AUTOSAR XML (schema 00049)
# Copyright (c) 2024 Mercedes-Benz AG
standard types defined: boolean, uint16, uint32, uint8
package /Units
  13 x unit:
    percent: display-name=%  # %
    A: display-name=A
    km: display-name=km
    km_per_h: display-name=km/h  # km/h
    m_per_s_sq: display-name=m/s²  # m/s²
    NoUnit: display-name=NoUnit
    ns: display-name=ns
    s: display-name=s
    V: display-name=V
    deg: display-name=°  # °
    deg_per_s: display-name=°/s  # °/s
    deg_per_s_sq: display-name=°/s²  # °/s²
    deg_C: display-name=°C  # °C
package /ImplementationDataTypes
  41 x impl type, all with category=TYPE_REFERENCE:
    c02_Ndef_False_True_ST3: data-constr=c02_Ndef_False_True_ST3, implementation-data-type=uint8, invalid-value=3  # 02_Ndef_False_True_ST3
    c02_TransMd_Stat: data-constr=c02_TransMd_Stat, implementation-data-type=uint8, invalid-value=3  # 02_TransMd_Stat
    c3_HAD_Ext_Stat_ST3: data-constr=c3_HAD_Ext_Stat_ST3, implementation-data-type=uint8, invalid-value=7  # 03_HAD_Ext_State_ST3
    c03_IMU_Force_Ang_Stat_ST3: data-constr=c03_IMU_Force_Ang_Stat_ST3, implementation-data-type=uint8  # 03_IMU_Force_Ang_Stat_ST3
    c03_IMU_Stat_ST3: data-constr=c03_IMU_Stat_ST3, implementation-data-type=uint8  # 03_IMU_Stat_ST3
    c03_ISw_Stat: data-constr=c03_ISw_Stat, implementation-data-type=uint8, invalid-value=7  # 03_ISw_Stat
    c03_PN14_ProdMd_Stat_ST3: data-constr=c03_PN14_ProdMd_Stat_ST3, implementation-data-type=uint8, invalid-value=7  # 03_PN14_ProdMd_Stat_ST3
    c03_PN14_TDP_Sw_Stat: data-constr=c03_PN14_TDP_Sw_Stat, implementation-data-type=uint8, invalid-value=7  # 03_PN14_TDP_Sw_Stat
    c04_VehOpMode: data-constr=c04_VehOpMode, implementation-data-type=uint8, invalid-value=15  # 04_VehOpMode
    c07_per_0to100_1_SNA: data-constr=c07_per_0to100_1_SNA, implementation-data-type=uint8, invalid-value=127  # 07_%_0-100_1_SNA
    c07_0_111_1_SNA: data-constr=c07_0_111_1_SNA, implementation-data-type=uint8, invalid-value=127  # 07_0-111_SNA
    c08_0_254_1_SNA_255: data-constr=c08_0_254_1_SNA_255, implementation-data-type=uint8, invalid-value=255  # 08_0-254_1_SNA=255
    c08_0_255_1_SNA_na: data-constr=c08_0_255_1_SNA_na, implementation-data-type=uint8  # 08_0-255_1_SNA=-
    c08_TmSync_Stat: implementation-data-type=uint8  # 08_TmSync_Stat
    c08_UInt_SNA_na: data-constr=c08_UInt_SNA_na, implementation-data-type=uint8  # 08_UInt_SNA=-
    c08_deg_m50_160_1: data-constr=c08_deg_m50_160_1, implementation-data-type=uint8, invalid-value=255  # 08_°_-50-+160_1
    c08_degC_m40_85_0k5: data-constr=c08_degC_m40_85_0k5, implementation-data-type=uint8, invalid-value=255  # 08_°C_-40-+85_0,5
    c10_V_0_25k55_0k025: data-constr=c10_V_0_25k55_0k025, implementation-data-type=uint16, invalid-value=1023  # 10_V_0-25,55_0,025
    c10_WakeupRsn_ST3: data-constr=c10_WakeupRsn_ST3, implementation-data-type=uint16, invalid-value=1023  # 10_WakeupRsn_ST3
    c12_0_4094_1_SNA: data-constr=c12_0_4094_1_SNA, implementation-data-type=uint16, invalid-value=4095  # 12_0-4094_1_SNA
    c12_km_p_h_0_409k4_0k1: data-constr=c12_km_p_h_0_409k4_0k1, implementation-data-type=uint16, invalid-value=4095  # 12_km/h_0-409,4_0,1
    c13_A_m409k6_409k4_0k1: data-constr=c13_A_m409k6_409k4_0k1, implementation-data-type=uint16, invalid-value=8191  # 13_A_-409,6-409,4_0,1
    c16_CRC_woSNA: data-constr=c16_CRC_woSNA, implementation-data-type=uint16  # 16_CRC_w/oSNA
    c16_m_pro_s_sq_m50_50_0d002: data-constr=c16_m_pro_s_sq_m50_50_0d002, implementation-data-type=uint16, invalid-value=65535  # 16_m/s²_-50_+50_0.002
    c16_deg_per_sec_m300_300_0d01: data-constr=c16_deg_per_sec_m300_300_0d01, implementation-data-type=uint16, invalid-value=65535  # 16_°/s_-300-+300_0,01
    c16_deg_per_s_sq_m1200_1200_0d04: data-constr=c16_deg_per_s_sq_m1200_1200_0d04, implementation-data-type=uint16, invalid-value=65535  # 16_°/s²_-1200-+1200_0,04
    c24_km_0_999999k9_0k1_Invld_SNA: data-constr=c24_km_0_999999k9_0k1_Invld_SNA, implementation-data-type=uint32, invalid-value=16777215  # 24_km_0-999999,9_0,1_Invld_SNA
    c32_ns_0_4294967295_1_noSNA: data-constr=c32_ns_0_4294967295_1_noSNA, implementation-data-type=uint32  # 32_ns_0-4294967295_1_noSNA
    c32_s_0_4294967295_1_noSNA: data-constr=c32_s_0_4294967295_1_noSNA, implementation-data-type=uint32  # 32_s_0-4294967295_1_noSNA
    DC_BOOL: implementation-data-type=boolean
    NM_ActvWakeup: implementation-data-type=boolean
    NM_Coord_Id: range raw 0..3, implementation-data-type=uint8
    NM_Coord_SleepRdy: implementation-data-type=boolean
    NM_PartNw_Info: implementation-data-type=boolean
    NM_RepeatMsg_Rq: implementation-data-type=boolean
    Rsrv03: range raw 0..7, implementation-data-type=uint8, invalid-value=7
    Rsrv05: range raw 0..31, implementation-data-type=uint8, invalid-value=31
    Rsrv08: range raw 0..255, implementation-data-type=uint8, invalid-value=255
    Rsrv09: range raw 0..511, implementation-data-type=uint16, invalid-value=511
    Rsrv16: range raw 0..65535, implementation-data-type=uint16, invalid-value=65535
    Rsrv32: range raw 0..4294967295, implementation-data-type=uint32, invalid-value=4294967295
package /DataConstraints
  range c02_Ndef_False_True_ST3: raw 1..3  # 02_Ndef_False_True_ST3
  range c02_TransMd_Stat: raw 0..3  # 02_TransMd_Stat
  range c3_HAD_Ext_Stat_ST3: raw 0..7  # 03_HAD_Ext_State_ST3
  range c03_IMU_Force_Ang_Stat_ST3: raw 0..6  # 03_IMU_Force_Ang_Stat_ST3
  range c03_IMU_Stat_ST3: raw 0..4  # 03_IMU_Stat_ST3
  range c03_ISw_Stat: raw 0..7  # 03_ISw_Stat
  range c03_PN14_ProdMd_Stat_ST3: raw 0..7  # 03_PN14_ProdMd_Stat_ST3
  range c03_PN14_TDP_Sw_Stat: raw 0..7  # 03_PN14_TDP_Sw_Stat
  range c04_VehOpMode: raw 0..15  # 04_VehOpMode
  range c07_per_0to100_1_SNA: phys 0..127, raw 0..127  # 07_%_0-100_1_SNA
  range c07_0_111_1_SNA: phys 0..127, raw 0..127  # 07_0-111_SNA
  range c08_0_254_1_SNA_255: phys 0..255, raw 0..255  # 08_0-254_1_SNA=255
  range c08_0_255_1_SNA_na: phys 0..255, raw 0..255  # 08_0-255_1_SNA=-
  range c08_UInt_SNA_na: raw 0..255  # 08_UInt_SNA=-
  range c08_deg_m50_160_1: phys -50..205, raw 0..255  # 08_°_-50-+160_1
  range c08_degC_m40_85_0k5: phys -40..87.5, raw 0..255  # 08_°C_-40-+85_0,5
  range c10_V_0_25k55_0k025: phys 0..25.575, raw 0..1023  # 10_V_0-25,55_0,025
  range c10_WakeupRsn_ST3: raw 0..1023  # 10_WakeupRsn_ST3
  range c12_0_4094_1_SNA: phys 0..4095, raw 0..4095  # 12_0-4094_1_SNA
  range c12_km_p_h_0_409k4_0k1: phys 0..409.5, raw 0..4095  # 12_km/h_0-409,4_0,1
  range c13_A_m409k6_409k4_0k1: phys -409.6..409.5, raw 0..8191  # 13_A_-409,6-409,4_0,1
  range c16_CRC_woSNA: raw 0..65535  # 16_CRC_w/oSNA
  range c16_m_pro_s_sq_m50_50_0d002: phys -50..81.07, raw 0..65535  # 16_m/s²_-50_+50_0.002
  range c16_deg_per_sec_m300_300_0d01: phys -300..355.35, raw 0..65535  # 16_°/s_-300-+300_0,01
  range c16_deg_per_s_sq_m1200_1200_0d04: phys -1200..1421.4, raw 0..65535  # 16_°/s²_-1200-+1200_0,04
  range c24_km_0_999999k9_0k1_Invld_SNA: phys 0..1677721.5, raw 0..16777215  # 24_km_0-999999,9_0,1_Invld_SNA
  range c32_ns_0_4294967295_1_noSNA: phys 0..4294967295, raw 0..4294967295  # 32_ns_0-4294967295_1_noSNA
  range c32_s_0_4294967295_1_noSNA: phys 0..4294967295, raw 0..4294967295  # 32_s_0-4294967295_1_noSNA
package /ApplicationDataTypes
  41 x app type:
    c02_Ndef_False_True_ST3: category=VALUE, compu-method=c02_Ndef_False_True_ST3, data-constr=c02_Ndef_False_True_ST3, invalid-value=I_C02_NDEF_FALSE_TRUE_ST3_SNA  # 02_Ndef_False_True_ST3
    c02_TransMd_Stat: category=VALUE, compu-method=c02_TransMd_Stat, data-constr=c02_TransMd_Stat, invalid-value=I_C02_TRANSMD_STAT_SNA  # 02_TransMd_Stat
    c3_HAD_Ext_Stat_ST3: category=VALUE, compu-method=c3_HAD_Ext_Stat_ST3, data-constr=c3_HAD_Ext_Stat_ST3, invalid-value=I_C3_HAD_EXT_STAT_ST3_SNA  # 03_HAD_Ext_State_ST3
    c03_IMU_Force_Ang_Stat_ST3: category=VALUE, compu-method=c03_IMU_Force_Ang_Stat_ST3, data-constr=c03_IMU_Force_Ang_Stat_ST3  # 03_IMU_Force_Ang_Stat_ST3
    c03_IMU_Stat_ST3: category=VALUE, compu-method=c03_IMU_Stat_ST3, data-constr=c03_IMU_Stat_ST3  # 03_IMU_Stat_ST3
    c03_ISw_Stat: category=VALUE, compu-method=c03_ISw_Stat, data-constr=c03_ISw_Stat, invalid-value=I_C03_ISW_STAT_SNA  # 03_ISw_Stat
    c03_PN14_ProdMd_Stat_ST3: category=VALUE, compu-method=c03_PN14_ProdMd_Stat_ST3, data-constr=c03_PN14_ProdMd_Stat_ST3, invalid-value=I_C03_PN14_PRODMD_STAT_ST3_SNA  # 03_PN14_ProdMd_Stat_ST3
    c03_PN14_TDP_Sw_Stat: category=VALUE, compu-method=c03_PN14_TDP_Sw_Stat, data-constr=c03_PN14_TDP_Sw_Stat, invalid-value=I_C03_PN14_TDP_SW_STAT_SNA  # 03_PN14_TDP_Sw_Stat
    c04_VehOpMode: category=VALUE, compu-method=c04_VehOpMode, data-constr=c04_VehOpMode, invalid-value=I_C04_VEHOPMODE_SNA  # 04_VehOpMode
    c07_per_0to100_1_SNA: category=VALUE, compu-method=c07_per_0to100_1_SNA, data-constr=c07_per_0to100_1_SNA, invalid-value=I_C07_PER_0TO100_1_SNA_SNA %, unit=%  # 07_%_0-100_1_SNA
    c07_0_111_1_SNA: category=VALUE, compu-method=c07_0_111_1_SNA, data-constr=c07_0_111_1_SNA, invalid-value=I_C07_0_111_1_SNA_SNA, unit=NoUnit  # 07_0-111_SNA
    c08_0_254_1_SNA_255: category=VALUE, compu-method=c08_0_254_1_SNA_255, data-constr=c08_0_254_1_SNA_255, invalid-value=I_C08_0_254_1_SNA_255_SNA, unit=NoUnit  # 08_0-254_1_SNA=255
    c08_0_255_1_SNA_na: category=VALUE, compu {identical}, data-constr=c08_0_255_1_SNA_na, unit=NoUnit  # 08_0-255_1_SNA=-
    c08_TmSync_Stat: category=VALUE, compu-method=c08_TmSync_Stat  # 08_TmSync_Stat
    c08_UInt_SNA_na: category=VALUE, data-constr=c08_UInt_SNA_na  # 08_UInt_SNA=-
    c08_deg_m50_160_1: category=VALUE, compu-method=c08_deg_m50_160_1, data-constr=c08_deg_m50_160_1, invalid-value=I_C08_DEG_M50_160_1_SNA °, unit=°  # 08_°_-50-+160_1
    c08_degC_m40_85_0k5: category=VALUE, compu-method=c08_degC_m40_85_0k5, data-constr=c08_degC_m40_85_0k5, invalid-value=I_C08_DEGC_M40_85_0K5_SNA °C, unit=°C  # 08_°C_-40-+85_0,5
    c10_V_0_25k55_0k025: category=VALUE, compu-method=c10_V_0_25k55_0k025, data-constr=c10_V_0_25k55_0k025, invalid-value=I_C10_V_0_25K55_0K025_SNA V, unit=V  # 10_V_0-25,55_0,025
    c10_WakeupRsn_ST3: category=VALUE, compu-method=c10_WakeupRsn_ST3, data-constr=c10_WakeupRsn_ST3, invalid-value=I_C10_WAKEUPRSN_ST3_SNA  # 10_WakeupRsn_ST3
    c12_0_4094_1_SNA: category=VALUE, compu-method=c12_0_4094_1_SNA, data-constr=c12_0_4094_1_SNA, invalid-value=I_C12_0_4094_1_SNA_SNA, unit=NoUnit  # 12_0-4094_1_SNA
    c12_km_p_h_0_409k4_0k1: category=VALUE, compu-method=c12_km_p_h_0_409k4_0k1, data-constr=c12_km_p_h_0_409k4_0k1, invalid-value=I_C12_KM_P_H_0_409K4_0K1_SNA km/h, unit=km/h  # 12_km/h_0-409,4_0,1
    c13_A_m409k6_409k4_0k1: category=VALUE, compu-method=c13_A_m409k6_409k4_0k1, data-constr=c13_A_m409k6_409k4_0k1, invalid-value=I_C13_A_M409K6_409K4_0K1_SNA A, unit=A  # 13_A_-409,6-409,4_0,1
    c16_CRC_woSNA: category=VALUE, data-constr=c16_CRC_woSNA  # 16_CRC_w/oSNA
    c16_m_pro_s_sq_m50_50_0d002: category=VALUE, compu-method=c16_m_pro_s_sq_m50_50_0d002, data-constr=c16_m_pro_s_sq_m50_50_0d002, invalid-value=I_C16_M_PRO_S_SQ_M50_50_0D002_SNA m/s², unit=m/s²  # 16_m/s²_-50_+50_0.002
    c16_deg_per_sec_m300_300_0d01: category=VALUE, compu-method=c16_deg_per_sec_m300_300_0d01, data-constr=c16_deg_per_sec_m300_300_0d01, invalid-value=I_C16_DEG_PER_SEC_M300_300_0D01_SNA °/s, unit=°/s  # 16_°/s_-300-+300_0,01
    c16_deg_per_s_sq_m1200_1200_0d04: category=VALUE, compu-method=c16_deg_per_s_sq_m1200_1200_0d04, data-constr=c16_deg_per_s_sq_m1200_1200_0d04, invalid-value=I_C16_DEG_PER_S_SQ_M1200_1200_0D04_SNA °/s², unit=°/s²  # 16_°/s²_-1200-+1200_0,04
    c24_km_0_999999k9_0k1_Invld_SNA: category=VALUE, compu-method=c24_km_0_999999k9_0k1_Invld_SNA, data-constr=c24_km_0_999999k9_0k1_Invld_SNA, invalid-value=I_C24_KM_0_999999K9_0K1_INVLD_SNA_SNA km, unit=km  # 24_km_0-999999,9_0,1_Invld_SNA
    c32_ns_0_4294967295_1_noSNA: category=VALUE, compu {identical; unit ns}, data-constr=c32_ns_0_4294967295_1_noSNA, unit=ns  # 32_ns_0-4294967295_1_noSNA
    c32_s_0_4294967295_1_noSNA: category=VALUE, compu {identical; unit s}, data-constr=c32_s_0_4294967295_1_noSNA, unit=s  # 32_s_0-4294967295_1_noSNA
    DC_BOOL: category=BOOLEAN, compu {0=FALSE, 1=TRUE}
    NM_ActvWakeup: category=BOOLEAN, compu {0=FALSE, 1=TRUE}
    NM_Coord_Id: category=VALUE, range raw 0..3
    NM_Coord_SleepRdy: category=BOOLEAN, compu {0=FALSE, 1=TRUE}
    NM_PartNw_Info: category=BOOLEAN, compu {0=FALSE, 1=TRUE}
    NM_RepeatMsg_Rq: category=BOOLEAN, compu {0=FALSE, 1=TRUE}
    Rsrv03: category=VALUE, range raw 0..7, invalid-value=7
    Rsrv05: category=VALUE, range raw 0..31, invalid-value=31
    Rsrv08: category=VALUE, range raw 0..255, invalid-value=255
    Rsrv09: category=VALUE, range raw 0..511, invalid-value=511
    Rsrv16: category=VALUE, range raw 0..65535, invalid-value=65535
    Rsrv32: category=VALUE, range raw 0..4294967295, invalid-value=4294967295
package /CompuMethods
  compu method c02_Ndef_False_True_ST3: 1=I_C02_NDEF_FALSE_TRUE_ST3_FALSE (FALSE) (False), 2=I_C02_NDEF_FALSE_TRUE_ST3_TRUE (TRUE) (True), 3=I_C02_NDEF_FALSE_TRUE_ST3_SNA (SNA) (SNA value from data type)  # OLDNAME: st3_02_NDEF_FALSE_TRUE_SNA / DO NOT USE for future implementation of STAR3 and following architectures. Use 02_False_True instead.
  compu method c02_TransMd_Stat: 0=I_C02_TRANSMD_STAT_OFF (OFF) (Transport mode permanently off), 1=I_C02_TRANSMD_STAT_TEMP_OFF (TEMP_OFF) (Transport mode temporarily off), 2=I_C02_TRANSMD_STAT_ACTV (ACTV) (Transport mode active), 3=I_C02_TRANSMD_STAT_SNA (SNA) (SNA value from data type)
  compu method c3_HAD_Ext_Stat_ST3: 0=I_C3_HAD_EXT_STAT_ST3_HAD_OFF (HAD_OFF), 1=I_C3_HAD_EXT_STAT_ST3_HAD_IN_PREPARATION (HAD_IN_PREPARATION), 2=I_C3_HAD_EXT_STAT_ST3_HAD_FADE_IN (HAD_FADE_IN) (HAD FADE IN), 3=I_C3_HAD_EXT_STAT_ST3_HAD_ON (HAD_ON), 4=I_C3_HAD_EXT_STAT_ST3_HAD_FADE_OUT (HAD_FADE_OUT) (HAD FADE OUT), 7=I_C3_HAD_EXT_STAT_ST3_SNA (SNA) (SNA value from data type)  # st3_03_HAD_State / 03_HAD_Ext_State_ST3
  compu method c03_IMU_Force_Ang_Stat_ST3: 0=I_C03_IMU_FORCE_ANG_STAT_ST3_UNKNOWN (UNKNOWN) (Unknown), 1=I_C03_IMU_FORCE_ANG_STAT_ST3_INIT (INIT) (Initialization phase), 2=I_C03_IMU_FORCE_ANG_STAT_ST3_VALID (VALID) (Angular rates valid, within specification), 3=I_C03_IMU_FORCE_ANG_STAT_ST3_ERROR_SPORADIC (ERROR_SPORADIC) (Sporadic error of angular rates), 4=I_C03_IMU_FORCE_ANG_STAT_ST3_ERROR_PERMANENT (ERROR_PERMANENT) (Permanent error of angular rates), 5=I_C03_IMU_FORCE_ANG_STAT_ST3_ERROR_OVERLOAD (ERROR_OVERLOAD) (Overload of angular rates), 6=I_C03_IMU_FORCE_ANG_STAT_ST3_ERROR_TEMPERATURE (ERROR_TEMPERATURE) (Temperature outside of range or temperature gradient to high)
  compu method c03_IMU_Stat_ST3: 0=I_C03_IMU_STAT_ST3_UNKNOWN (UNKNOWN) (Unknown), 1=I_C03_IMU_STAT_ST3_INIT (INIT) (Initialization phase), 2=I_C03_IMU_STAT_ST3_OPERATIONAL (OPERATIONAL) (IMU operational, no overall error), 3=I_C03_IMU_STAT_ST3_ERROR_SPORADIC (ERROR_SPORADIC) (Overall sporadic error), 4=I_C03_IMU_STAT_ST3_ERROR_PERMANENT (ERROR_PERMANENT) (Overall permanent error)
  compu method c03_ISw_Stat: 0=I_C03_ISW_STAT_IGN_LOCK (IGN_LOCK) (Ignition lock (0)), 1=I_C03_ISW_STAT_IGN_OFF (IGN_OFF) (Ignition off (15c)), 2=I_C03_ISW_STAT_IGN_ACC (IGN_ACC) (Ignition accessory (15r)), 4=I_C03_ISW_STAT_IGN_ON (IGN_ON) (Ignition on (15)), 5=I_C03_ISW_STAT_IGN_START (IGN_START) (Ignition start (50)), 7=I_C03_ISW_STAT_SNA (SNA) (SNA value from data type)
  compu method c03_PN14_ProdMd_Stat_ST3: 0=I_C03_PN14_PRODMD_STAT_ST3_OFF (OFF) (Productionmode off), 1=I_C03_PN14_PRODMD_STAT_ST3_ON (ON) (Productionmode active), 2=I_C03_PN14_PRODMD_STAT_ST3_SF01 (SF01) (Productionmode Special Funcion 1), 3=I_C03_PN14_PRODMD_STAT_ST3_SF02 (SF02) (Productionmode Special Funcion 2), 4=I_C03_PN14_PRODMD_STAT_ST3_SF03 (SF03) (Productionmode Special Funcion 3), 7=I_C03_PN14_PRODMD_STAT_ST3_SNA (SNA) (SNA value from data type)
  compu method c03_PN14_TDP_Sw_Stat: 0=I_C03_PN14_TDP_SW_STAT_CLS (CLS) (TDP switch is closed), 1=I_C03_PN14_TDP_SW_STAT_PRE_RESET (PRE_RESET) (Pre-Reset warning), 2=I_C03_PN14_TDP_SW_STAT_RESET (RESET) (Reset active), 3=I_C03_PN14_TDP_SW_STAT_PRE_OPN (PRE_OPN) (Pre-Open warning), 4=I_C03_PN14_TDP_SW_STAT_OPN (OPN) (TDP switch is open), 7=I_C03_PN14_TDP_SW_STAT_SNA (SNA) (SNA value from data type)
  compu method c04_VehOpMode: 0=I_C04_VEHOPMODE_DRV (DRV) (Drive), 1=I_C04_VEHOPMODE_DIAG (DIAG) (Diagnostic), 2=I_C04_VEHOPMODE_REMSTART_PRECON (REMSTART_PRECON) (Remote_start preconditioning), 3=I_C04_VEHOPMODE_ENG_RUN_CONT (ENG_RUN_CONT) (Engine continuos running), 4=I_C04_VEHOPMODE_KEY_PARK (KEY_PARK) (Key_parking), 5=I_C04_VEHOPMODE_REMSTART_BAT_CHRG (REMSTART_BAT_CHRG) (Remote start battery charge), 6=I_C04_VEHOPMODE_AVP (AVP) (Automated Valet Parking), 7=I_C04_VEHOPMODE_SDC (SDC) (Self Driving Car), 8=I_C04_VEHOPMODE_ADSE (ADSE) (Automated Driving for Specific Environments), 15=I_C04_VEHOPMODE_SNA (SNA) (SNA value from data type)
  compu method c07_per_0to100_1_SNA: phys=raw for raw 0..100, 127=I_C07_PER_0TO100_1_SNA_SNA (SNA) (SNA value from data type); unit %
  compu method percent_1_0: identical; unit %
  compu method c07_0_111_1_SNA: phys=raw for raw 0..111, 127=I_C07_0_111_1_SNA_SNA (SNA) (SNA value from data type)
  compu method c08_0_254_1_SNA_255: phys=raw for raw 0..254, 255=I_C08_0_254_1_SNA_255_SNA (SNA) (SNA value from data type)
  compu method c08_TmSync_Stat: mask 0b10000000: 0b00000000=c08_TmSync_Stat_TM_SYNC_STAT_INVALID_FALSE (c08_TmSync_Stat_TM_SYNC_STAT_INVALID), mask 0b10000000: 0b10000000=c08_TmSync_Stat_TM_SYNC_STAT_INVALID_TRUE (c08_TmSync_Stat_TM_SYNC_STAT_INVALID), mask 0b10000001: 0b00000000=c08_TmSync_Stat_TIMEOUT_FALSE (c08_TmSync_Stat_TIMEOUT), mask 0b10000001: 0b00000001=c08_TmSync_Stat_TIMEOUT_TRUE (c08_TmSync_Stat_TIMEOUT), mask 0b10000010: 0b00000000=c08_TmSync_Stat_BIT1_RESERVED_FALSE (c08_TmSync_Stat_BIT1_RESERVED), mask 0b10000010: 0b00000010=c08_TmSync_Stat_BIT1_RESERVED_TRUE (c08_TmSync_Stat_BIT1_RESERVED), mask 0b10000100: 0b00000000=c08_TmSync_Stat_SYNC_TO_GATEWAY_FALSE (c08_TmSync_Stat_SYNC_TO_GATEWAY), mask 0b10000100: 0b00000100=c08_TmSync_Stat_SYNC_TO_GATEWAY_TRUE (c08_TmSync_Stat_SYNC_TO_GATEWAY), mask 0b10001000: 0b00000000=c08_TmSync_Stat_GLOBAL_TIME_BASE_FALSE (c08_TmSync_Stat_GLOBAL_TIME_BASE), mask 0b10001000: 0b00001000=c08_TmSync_Stat_GLOBAL_TIME_BASE_TRUE (c08_TmSync_Stat_GLOBAL_TIME_BASE), mask 0b10010000: 0b00000000=c08_TmSync_Stat_TIMELEAP_FUTURE_FALSE (c08_TmSync_Stat_TIMELEAP_FUTURE), mask 0b10010000: 0b00010000=c08_TmSync_Stat_TIMELEAP_FUTURE_TRUE (c08_TmSync_Stat_TIMELEAP_FUTURE), mask 0b10100000: 0b00000000=c08_TmSync_Stat_TIMELEAP_PAST_FALSE (c08_TmSync_Stat_TIMELEAP_PAST), mask 0b10100000: 0b00100000=c08_TmSync_Stat_TIMELEAP_PAST_TRUE (c08_TmSync_Stat_TIMELEAP_PAST), mask 0b11000000: 0b00000000=c08_TmSync_Stat_SYNC_TO_PURE_LOCAL_TIME_BASE_FALSE (c08_TmSync_Stat_SYNC_TO_PURE_LOCAL_TIME_BASE), mask 0b11000000: 0b01000000=c08_TmSync_Stat_SYNC_TO_PURE_LOCAL_TIME_BASE_TRUE (c08_TmSync_Stat_SYNC_TO_PURE_LOCAL_TIME_BASE)
  compu method c08_deg_m50_160_1: phys=raw-50 for raw 0..210, 255=I_C08_DEG_M50_160_1_SNA (SNA) (SNA value from data type); unit °
  compu method deg_1_m50: phys=raw-50; unit °
  compu method c08_degC_m40_85_0k5: phys=raw*0.5-40 for raw 0..250, 255=I_C08_DEGC_M40_85_0K5_SNA (SNA) (SNA value from data type); unit °C
  compu method deg_C_0d5_m40: phys=raw*0.5-40; unit °C
  compu method c10_V_0_25k55_0k025: phys=raw*0.025 for raw 0..1022, 1023=I_C10_V_0_25K55_0K025_SNA (SNA) (SNA value from data type); unit V
  compu method V_0d025_0: phys=raw*0.025; unit V
  compu method c10_WakeupRsn_ST3: 0=I_C10_WAKEUPRSN_ST3_NETWORK (NETWORK) (Wakeup by network), 1=I_C10_WAKEUPRSN_ST3_NW_MAIN (NW_MAIN) (Wakeup by MAIN Ethernet), 11=I_C10_WAKEUPRSN_ST3_NW_HEADUNIT1 (NW_HEADUNIT1) (Wakeup by HEADUNIT1 CAN), 12=I_C10_WAKEUPRSN_ST3_NW_HEADUNIT2 (NW_HEADUNIT2) (Wakeup by HEADUNIT2 CAN), 13=I_C10_WAKEUPRSN_ST3_NW_PERIPHERY (NW_PERIPHERY) (Wakeup by PERIPHERY CAN), 14=I_C10_WAKEUPRSN_ST3_NW_BODY1 (NW_BODY1) (Wakeup by BODY1 CAN), 15=I_C10_WAKEUPRSN_ST3_NW_CHASSIS (NW_CHASSIS) (Wakeup by CHASSIS FlexRay), 16=I_C10_WAKEUPRSN_ST3_NW_RADAR_R (NW_RADAR_R) (Wakeup by RADAR_R CAN), 17=I_C10_WAKEUPRSN_ST3_NW_RADAR_F (NW_RADAR_F) (Wakeup by RADAR_F CAN), 18=I_C10_WAKEUPRSN_ST3_NW_OBD_PTI (NW_OBD_PTI) (Wakeup by OBD_PTI CAN), 19=I_C10_WAKEUPRSN_ST3_NW_STEERING_WHEEL (NW_STEERING_WHEEL) (Wakeup by STEERING_WHEEL CAN), 20=I_C10_WAKEUPRSN_ST3_NW_CPC (NW_CPC) (Wakeup by CPC CAN), 21=I_C10_WAKEUPRSN_ST3_NW_ECM (NW_ECM) (Wakeup by ECM CAN), 22=I_C10_WAKEUPRSN_ST3_NW_ENERGY (NW_ENERGY) (Wakeup by ENERGY CAN), 23=I_C10_WAKEUPRSN_ST3_NW_INV (NW_INV) (Wakeup by INV CAN), 24=I_C10_WAKEUPRSN_ST3_NW_TCM (NW_TCM) (Wakeup by TCM CAN), 25=I_C10_WAKEUPRSN_ST3_NW_AEPU (NW_AEPU) (Wakeup by AEPU CAN), 26=I_C10_WAKEUPRSN_ST3_NW_BODY2 (NW_BODY2) (Wakeup by BODY2 CAN), 27=I_C10_WAKEUPRSN_ST3_NW_BODY3 (NW_BODY3) (Wakeup by BODY3 CAN), 28=I_C10_WAKEUPRSN_ST3_NW_CAL_COC (NW_CAL_COC) (Wakeup by CAL_COC CAN), 29=I_C10_WAKEUPRSN_ST3_NW_CAL_DL (NW_CAL_DL) (Wakeup by CAL_DL CAN), 30=I_C10_WAKEUPRSN_ST3_NW_CAL_DR (NW_CAL_DR) (Wakeup by CAL_DR CAN), 31=I_C10_WAKEUPRSN_ST3_NW_ECM_PERIPHERY1 (NW_ECM_PERIPHERY1) (Wakeup by ECM_PERIPHERY1 CAN), 32=I_C10_WAKEUPRSN_ST3_NW_ECM_PERIPHERY2 (NW_ECM_PERIPHERY2) (Wakeup by ECM_PERIPHERY2 CAN), 33=I_C10_WAKEUPRSN_ST3_NW_ENGINE_PT3 (NW_ENGINE_PT3) (Wakeup by ENGINE_PT3 CAN), 34=I_C10_WAKEUPRSN_ST3_NW_HAD_BACKUP (NW_HAD_BACKUP) (Wakeup by HAD_BACKUP CAN), 35=I_C10_WAKEUPRSN_ST3_NW_HYBRID_PT3 (NW_HYBRID_PT3) (Wakeup by HYBRID_PT3 CAN), 36=I_C10_WAKEUPRSN_ST3_NW_LSM_F (NW_LSM_F) (Wakeup by LSM_F CAN), 37=I_C10_WAKEUPRSN_ST3_NW_POWERTRAIN_PT3 (NW_POWERTRAIN_PT3) (Wakeup by POWERTRAIN_PT3 CAN), 38=I_C10_WAKEUPRSN_ST3_NW_PT_SENSOR_PT3 (NW_PT_SENSOR_PT3) (Wakeup by PT_SENSOR_PT3 CAN), 39=I_C10_WAKEUPRSN_ST3_NW_RVC_HSVL (NW_RVC_HSVL) (Wakeup by RVC_HSVL CAN), 40=I_C10_WAKEUPRSN_ST3_NW_SPV (NW_SPV) (Wakeup by SPV CAN), 41=I_C10_WAKEUPRSN_ST3_NW_SUSPENSION_F (NW_SUSPENSION_F) (Wakeup by SUSPENSION_F CAN), 42=I_C10_WAKEUPRSN_ST3_NW_SUSPENSION_R (NW_SUSPENSION_R) (Wakeup by SUSPENSION_R CAN), 43=I_C10_WAKEUPRSN_ST3_NW_EIS_BASE_GW (NW_EIS_BASE_GW) (Wakeup by EIS_BASE_GW CAN), 44=I_C10_WAKEUPRSN_ST3_NW_EIS_GW_BASE (NW_EIS_GW_BASE) (Wakeup by EIS_GW_BASE CAN), 45=I_C10_WAKEUPRSN_ST3_NW_AUXILIARY1 (NW_AUXILIARY1) (Wakeup by AUXILIARY1 CAN), 46=I_C10_WAKEUPRSN_ST3_NW_AUXILIARY2 (NW_AUXILIARY2) (Wakeup by AUXILIARY2 CAN), 47=I_C10_WAKEUPRSN_ST3_NW_DRIVE_UNIT (NW_DRIVE_UNIT) (Wakeup by DRIVE_UNIT CAN), 48=I_C10_WAKEUPRSN_ST3_NW_INLET (NW_INLET) (Wakeup by INLET CAN), 49=I_C10_WAKEUPRSN_ST3_NW_BODY4 (NW_BODY4) (Wakeup by BODY4 CAN), 50=I_C10_WAKEUPRSN_ST3_NW_DRIVING (NW_DRIVING) (Wakeup by DRIVING-CAN), 51=I_C10_WAKEUPRSN_ST3_NW_EDS1 (NW_EDS1) (Wakeup by EDS1-CAN), 52=I_C10_WAKEUPRSN_ST3_NW_EDS2 (NW_EDS2) (Wakeup by EDS2-CAN), 53=I_C10_WAKEUPRSN_ST3_NW_HAD_IMU (NW_HAD_IMU) (Wakeup by HAD_IMU-CAN), 54=I_C10_WAKEUPRSN_ST3_NW_MULTIPURPOSE (NW_MULTIPURPOSE) (Wakeup by MULTIPURPOSE-CAN), 55=I_C10_WAKEUPRSN_ST3_NW_PERIPHERY2 (NW_PERIPHERY2) (Wakeup by PERIPHERY2-CAN), 56=I_C10_WAKEUPRSN_ST3_NW_SUSPENSION_AMG (NW_SUSPENSION_AMG) (Wakeup by SUSPENSION_AMG-CAN), 57=I_C10_WAKEUPRSN_ST3_NW_BMS_SENSOR (NW_BMS_SENSOR) (Wakeup by BMS_SENSOR-CAN), 115=I_C10_WAKEUPRSN_ST3_LIN_HVAC_F (LIN_HVAC_F) (Wakeup by LIN-Slave HVAC_F), 116=I_C10_WAKEUPRSN_ST3_LIN_HVAC_R (LIN_HVAC_R) (Wakeup by LIN-Slave HVAC_R), 117=I_C10_WAKEUPRSN_ST3_LIN_VCS (LIN_VCS) (Wakeup by LIN-Slave VCS), 118=I_C10_WAKEUPRSN_ST3_LIN_WPRA (LIN_WPRA) (Wakeup by LIN-Slave WPRA), 119=I_C10_WAKEUPRSN_ST3_LIN_IHTM_RC (LIN_IHTM_RC) (Wakeup by LIN-Slave IHTM_RC), 120=I_C10_WAKEUPRSN_ST3_LIN_PTC48_R (LIN_PTC48_R) (Wakeup by LIN-Slave PTC48_R), 121=I_C10_WAKEUPRSN_ST3_LIN_AQS (LIN_AQS) (Wakeup by LIN-Slave AQS), 122=I_C10_WAKEUPRSN_ST3_LIN_ECP2_1 (LIN_ECP2_1) (Wakeup by LIN-Slave ECP2_1), 123=I_C10_WAKEUPRSN_ST3_LIN_EXV1 (LIN_EXV1) (Wakeup by LIN-Slave EXV1), 124=I_C10_WAKEUPRSN_ST3_LIN_IHTM (LIN_IHTM) (Wakeup by LIN-Slave IHTM), 125=I_C10_WAKEUPRSN_ST3_LIN_EAC (LIN_EAC) (Wakeup by LIN-Slave EAC), 126=I_C10_WAKEUPRSN_ST3_LIN_EAC48 (LIN_EAC48) (Wakeup by LIN-Slave EAC48), 127=I_C10_WAKEUPRSN_ST3_LIN_PTC_HV (LIN_PTC_HV) (Wakeup by LIN-Slave PTC_HV), 128=I_C10_WAKEUPRSN_ST3_TERM_15 (TERM_15) (Wakeup by discrete terminal 15 signal), 129=I_C10_WAKEUPRSN_ST3_SBW_LVR_PSD (SBW_LVR_PSD) (Shift By Wire Lever Pressed), 130=I_C10_WAKEUPRSN_ST3_TERM_54 (TERM_54) (Wakeup by terminal 54 active), 131=I_C10_WAKEUPRSN_ST3_LIN_HFA (LIN_HFA) (Wakeup by LIN-Slave Hands Free Access), 132=I_C10_WAKEUPRSN_ST3_LIN_IBS (LIN_IBS) (Wakeup by LIN-Slave Battery sensor), 133=I_C10_WAKEUPRSN_ST3_LIN_DOOR_HANDLE (LIN_DOOR_HANDLE) (Wakeup by LIN-Slave Door Handle), 134=I_C10_WAKEUPRSN_ST3_LIN_LISB48 (LIN_LISB48) (Wakeup by LIN-Slave LISB48), 135=I_C10_WAKEUPRSN_ST3_CMN_ECU_RST_POR (CMN_ECU_RST_POR) (Wakeup by ECU Power On Reset, Common Reason), 136=I_C10_WAKEUPRSN_ST3_CMN_ECU_RST_DIAG (CMN_ECU_RST_DIAG) (Wakeup by ECU Diagnostic Reset, Common Reason), 137=I_C10_WAKEUPRSN_ST3_CMN_ECU_RST_TEST (CMN_ECU_RST_TEST) (Wakeup by ECU Test Reset, Common Reason), 138=I_C10_WAKEUPRSN_ST3_CMN_ECU_RST_ERR (CMN_ECU_RST_ERR) (Wakeup by ECU Error Reset, Common Reason), 139=I_C10_WAKEUPRSN_ST3_CMN_ETH_WAKEUPLINE (CMN_ETH_WAKEUPLINE) (Wakeup by Ethernet Wakeup-Line, Common Reason), 140=I_C10_WAKEUPRSN_ST3_CMN_AFTERRUN (CMN_AFTERRUN) (Wakeup by afterrun, Common Reason), 141=I_C10_WAKEUPRSN_ST3_CRASH (CRASH) (Wakeup by crash signal), 142=I_C10_WAKEUPRSN_ST3_LIN_VCI (LIN_VCI) (Wakeup by LIN-Slave VCI), 143=I_C10_WAKEUPRSN_ST3_LIN_CIS (LIN_CIS) (Wakeup by LIN-Slave CIS), 150=I_C10_WAKEUPRSN_ST3_HANDLE_TAG2 (HANDLE_TAG2) (Wakeup by door handle TAG 2), 151=I_C10_WAKEUPRSN_ST3_DAC_MOBILE (DAC_MOBILE) (Wakeup by DAC Mobile (driving authorization check)), 181=I_C10_WAKEUPRSN_ST3_EASY_ENTRY_ACTV (EASY_ENTRY_ACTV) (Wakeup by Easy Entry active), 183=I_C10_WAKEUPRSN_ST3_ERR_SEAT_HTVN (ERR_SEAT_HTVN) (Wakeup by error seat heating/ventilation), 184=I_C10_WAKEUPRSN_ST3_ERR_SEAT_CHM (ERR_SEAT_CHM) (Wakeup by error console heating), 199=I_C10_WAKEUPRSN_ST3_VEHSL_EVENT (VEHSL_EVENT) (Wakeup by Vehicle State Living signal update), 200=I_C10_WAKEUPRSN_ST3_RLS (RLS) (Wakeup by rotary light switch), 201=I_C10_WAKEUPRSN_ST3_EF_KEY (EF_KEY) (Wakeup by emergency flasher key), 202=I_C10_WAKEUPRSN_ST3_RHU_FT (RHU_FT) (Wakeup by residual heat utilization front), 203=I_C10_WAKEUPRSN_ST3_RHU_R (RHU_R) (Wakeup by residual heat utilization rear), 204=I_C10_WAKEUPRSN_ST3_ICH_RQ (ICH_RQ) (Wakeup by idependent car heater request), 205=I_C10_WAKEUPRSN_ST3_VPRZR_VN (VPRZR_VN) (Wakeup by Vaporizer ventilation), 206=I_C10_WAKEUPRSN_ST3_PRECON (PRECON) (Wakeup by PreConditioning), 207=I_C10_WAKEUPRSN_ST3_SOL_VN (SOL_VN) (Wakeup by Solar Ventilation), 208=I_C10_WAKEUPRSN_ST3_EXTLGT_ACTV (EXTLGT_ACTV) (Wakeup by exterior lighting active), 209=I_C10_WAKEUPRSN_ST3_INTLGT_ACTV (INTLGT_ACTV) (Wakeup by interior lighting active), 210=I_C10_WAKEUPRSN_ST3_TSSR_ACTV (TSSR_ACTV) (Wakeup by TSSR active), 211=I_C10_WAKEUPRSN_ST3_SEAT_HT_F_ACTV (SEAT_HT_F_ACTV) (Wakeup by seat heating front active), 212=I_C10_WAKEUPRSN_ST3_SEAT_HT_R_ACTV (SEAT_HT_R_ACTV) (Wakeup by seat heating rear active), 213=I_C10_WAKEUPRSN_ST3_SEAT_VN_F_ACTV (SEAT_VN_F_ACTV) (Wakeup by seat ventilation front active), 214=I_C10_WAKEUPRSN_ST3_SEAT_VN_R_ACTV (SEAT_VN_R_ACTV) (Wakeup by seat ventilation rear active), 215=I_C10_WAKEUPRSN_ST3_EHS_3S (EHS_3S) (Wakeup by 3S engine hood switch (Pawl)), 216=I_C10_WAKEUPRSN_ST3_T58D_POTI (T58D_POTI) (Wakeup by terminal 58d potentiometer), 217=I_C10_WAKEUPRSN_ST3_DRB (DRB) (Wakeup by Double Roller Blind), 218=I_C10_WAKEUPRSN_ST3_BKRST_UNLK_RM (BKRST_UNLK_RM) (Wakeup by Backrest Unlock rear Middle), 219=I_C10_WAKEUPRSN_ST3_DL_SW2_PSD (DL_SW2_PSD) (Wakeup by Deck Lid Switch Pressed 2), 220=I_C10_WAKEUPRSN_ST3_DL_SW (DL_SW) (Wakeup by deck lid switch pressed), 221=I_C10_WAKEUPRSN_ST3_BGC_SW (BGC_SW) (Wakeup by switch inside baggage compartment pressed), 222=I_C10_WAKEUPRSN_ST3_BKRST_RL_LK_UNLK (BKRST_RL_LK_UNLK) (Wakeup by back rest rear left locked or unlocked), 223=I_C10_WAKEUPRSN_ST3_BKRST_RR_LK_UNLK (BKRST_RR_LK_UNLK) (Wakeup by back rest rear right locked or unlocked), 224=I_C10_WAKEUPRSN_ST3_DL_CLS_LK_SW (DL_CLS_LK_SW) (Wakeup by deck lid switch close/lock close pressed), 225=I_C10_WAKEUPRSN_ST3_DL_RLTCH (DL_RLTCH) (Wakeup by deck lid rotary latch pressed), 226=I_C10_WAKEUPRSN_ST3_BKRST_3L_LK_UNLK (BKRST_3L_LK_UNLK) (Wakeup by back rest 3rd row left locked or unlocked), 227=I_C10_WAKEUPRSN_ST3_BKRST_3R_LK_UNLK (BKRST_3R_LK_UNLK) (Wakeup by back rest 3rd row right locked or unlocked), 228=I_C10_WAKEUPRSN_ST3_GAS_DR_SW (GAS_DR_SW) (Wakeup by gas door switch), 229=I_C10_WAKEUPRSN_ST3_AILCF (AILCF) (Wakeup by AILCF), 230=I_C10_WAKEUPRSN_ST3_AILCC (AILCC) (Wakeup by AILCC), 250=I_C10_WAKEUPRSN_ST3_FRONT_TRUNK_SWITCH (FRONT_TRUNK_SWITCH) (Wakeup by front trunk switch), 251=I_C10_WAKEUPRSN_ST3_FRONT_TRUNK_LATCH_PRSD (FRONT_TRUNK_LATCH_PRSD) (Wakeup by front trunk latch pressed), 252=I_C10_WAKEUPRSN_ST3_BIG_FLIP_WNDW_SWITCH (BIG_FLIP_WNDW_SWITCH) (Wakeup by big flip window switch), 253=I_C10_WAKEUPRSN_ST3_BIG_FLIP_WNDW_STATE (BIG_FLIP_WNDW_STATE) (Wakeup by big flip window state), 256=I_C10_WAKEUPRSN_ST3_TRLR_ELEC_ACT (TRLR_ELEC_ACT) (Wakeup by electrical trailer hitch activation), 257=I_C10_WAKEUPRSN_ST3_TRLR_DET (TRLR_DET) (Wakeup by trailer detected), 258=I_C10_WAKEUPRSN_ST3_DL_LK (DL_LK) (Wakeup by delayed locking), 259=I_C10_WAKEUPRSN_ST3_START_SW_PSD (START_SW_PSD) (Wakeup by start switch pressed), 260=I_C10_WAKEUPRSN_ST3_RADIO_DATA (RADIO_DATA) (Wakeup by radio data), 261=I_C10_WAKEUPRSN_ST3_RLTCH_DR (RLTCH_DR) (Wakeup by rotational latch door), 263=I_C10_WAKEUPRSN_ST3_PKBRKSW (PKBRKSW) (Wakeup by Parking switch pressed), 264=I_C10_WAKEUPRSN_ST3_KEYLESS_GO (KEYLESS_GO) (Wakeup by Keyless Go/Start (Core 1/0)), 265=I_C10_WAKEUPRSN_ST3_PNM12 (PNM12) (Wakeup by Power network management 12V), 266=I_C10_WAKEUPRSN_ST3_PNM48 (PNM48) (Wakeup by Power network management 48V), 267=I_C10_WAKEUPRSN_ST3_BAT48_LOWCHARGE (BAT48_LOWCHARGE) (Wakeup by 48V battery due to low charge), 270=I_C10_WAKEUPRSN_ST3_PN14_IODM (PN14_IODM) (Wakeup by IOD Measurement), 271=I_C10_WAKEUPRSN_ST3_PN14_REMSRV_STAT (PN14_REMSRV_STAT) (Wakeup by Change of Remote Service Status), 272=I_C10_WAKEUPRSN_ST3_PN14_DDP (PN14_DDP) (Wakeup by Deep Discharge Protection), 273=I_C10_WAKEUPRSN_ST3_PN14_LOWCHARGE (PN14_LOWCHARGE) (Wakeup by low charge of the battery), 274=I_C10_WAKEUPRSN_ST3_PN14_REMODHV12V (PN14_REMODHV12V) (Wakeup by reload mode HV 12V), 275=I_C10_WAKEUPRSN_ST3_PN14_DLM (PN14_DLM) (Wakeup by Powernet CutOff (Dynamic Load Management)), 276=I_C10_WAKEUPRSN_ST3_SDC_PN2_LOWCHARGE (SDC_PN2_LOWCHARGE) (Wakeup by low charge of the battery in SDC_PNM2), 277=I_C10_WAKEUPRSN_ST3_SDC_PN2_REMODHV12V (SDC_PN2_REMODHV12V) (Wakeup by reload mode HV 12 in SDC_PNM2), 278=I_C10_WAKEUPRSN_ST3_PN14_REM_ENGINE_START (PN14_REM_ENGINE_START) (Wakeup by PN14 remote engine start), 280=I_C10_WAKEUPRSN_ST3_DATA_EXCHG (DATA_EXCHG) (Wakeup by data exchange with vehicle functions), 281=I_C10_WAKEUPRSN_ST3_INTERNET_CON (INTERNET_CON) (Wakeup by internet connection), 282=I_C10_WAKEUPRSN_ST3_CMN_USER_DATA (CMN_USER_DATA) (Wakeup by user data, Common Reason), 290=I_C10_WAKEUPRSN_ST3_CMN_SERV_LOCAL (CMN_SERV_LOCAL) (Wakeup by local activated service, Common Reason), 291=I_C10_WAKEUPRSN_ST3_CMN_SERV_REM (CMN_SERV_REM) (Wakeup by remote activated service, Common Reason), 292=I_C10_WAKEUPRSN_ST3_VEH_REAR_LOWERING (VEH_REAR_LOWERING) (Wakeup by vehicle rear lowering), 300=I_C10_WAKEUPRSN_ST3_CMN_BTN_PSD (CMN_BTN_PSD) (Wakeup by button pressed, Common Reason), 301=I_C10_WAKEUPRSN_ST3_FLAP_PSD (FLAP_PSD) (Wakeup by flap pressed), 302=I_C10_WAKEUPRSN_ST3_CHADEMO (CHADEMO) (Wakeup by CHADEMO charging system), 303=I_C10_WAKEUPRSN_ST3_GBT (GBT) (Wakeup by GBT charging system), 304=I_C10_WAKEUPRSN_ST3_CMN_PROXIMITY (CMN_PROXIMITY) (Wakeup by proximity, Common Reason), 305=I_C10_WAKEUPRSN_ST3_CTRL_PILOT (CTRL_PILOT) (Wakeup by control pilot), 306=I_C10_WAKEUPRSN_ST3_CMN_HV_DET (CMN_HV_DET) (Wakeup by HiVolt detection, Common Reason), 307=I_C10_WAKEUPRSN_ST3_CMN_CHRG_TMR (CMN_CHRG_TMR) (Wakeup by charging timer, Common Reason), 308=I_C10_WAKEUPRSN_ST3_TRCT_BAT_OP_STRATEGY (TRCT_BAT_OP_STRATEGY) (Wakeup by traction battery operating strategy), 309=I_C10_WAKEUPRSN_ST3_VTA (VTA) (Wakeup by VTA alarm), 310=I_C10_WAKEUPRSN_ST3_PDD (PDD) (Wakeup by PDD collision detected), 311=I_C10_WAKEUPRSN_ST3_UNEQUAL_STRING_VOLT (UNEQUAL_STRING_VOLT) (Wakeup by unequal string voltages), 312=I_C10_WAKEUPRSN_ST3_MUTE_ACTV (MUTE_ACTV) (Wakeup by mute activated), 313=I_C10_WAKEUPRSN_ST3_VIDEO_RQ (VIDEO_RQ) (Wakeup by video in request), 314=I_C10_WAKEUPRSN_ST3_ALARM_ACTV (ALARM_ACTV) (Wakeup by alarm activation), 315=I_C10_WAKEUPRSN_ST3_RECIRC_AIR_RQ (RECIRC_AIR_RQ) (Wakeup by FLA/NFS recirc air request), 316=I_C10_WAKEUPRSN_ST3_TPM_SYNC (TPM_SYNC) (Wakeup by TPM synchronize BackEndServer), 320=I_C10_WAKEUPRSN_ST3_DI_DISP_RQ (DI_DISP_RQ) (Wakeup by DI display request), 321=I_C10_WAKEUPRSN_ST3_DI_IND_RQ (DI_IND_RQ) (Wakeup by DI indicator request), 322=I_C10_WAKEUPRSN_ST3_HUD_RQ (HUD_RQ) (Wakeup by HUD request), 323=I_C10_WAKEUPRSN_ST3_ON_KEY (ON_KEY) (Wakeup by on key), 325=I_C10_WAKEUPRSN_ST3_MSG_DISP_RQ (MSG_DISP_RQ) (Wakeup by message display request), 326=I_C10_WAKEUPRSN_ST3_ROOF_LMP_ON_RQ (ROOF_LMP_ON_RQ) (Wakeup by rooflamps on request), 327=I_C10_WAKEUPRSN_ST3_IL_ON_RQ (IL_ON_RQ) (Wakeup by interior light activated from special vehicle), 328=I_C10_WAKEUPRSN_ST3_SPS_APPL (SPS_APPL) (Wakeup by special vehicle application), 330=I_C10_WAKEUPRSN_ST3_PWC_WRAPPER (PWC_WRAPPER) (Wakeup by PWC Wrapper), 331=I_C10_WAKEUPRSN_ST3_PW_SW (PW_SW) (Wakeup by power window switch), 332=I_C10_WAKEUPRSN_ST3_CLKS_SW (CLKS_SW) (Wakeup by centrol locking system switch), 333=I_C10_WAKEUPRSN_ST3_SEAT_SW (SEAT_SW) (Wakeup by seat switch), 334=I_C10_WAKEUPRSN_ST3_DL_REM_SW (DL_REM_SW) (Wakeup by deck lid remote switch), 335=I_C10_WAKEUPRSN_ST3_TANK_UNLK_SW (TANK_UNLK_SW) (Wakeup by tank unlock switch), 336=I_C10_WAKEUPRSN_ST3_SLTCH_DR (SLTCH_DR) (Wakeup by secondary latch), 337=I_C10_WAKEUPRSN_ST3_INSRLVR_SW (INSRLVR_SW) (Wakeup by inside release lever switch), 338=I_C10_WAKEUPRSN_ST3_OUTSRLVR_SW (OUTSRLVR_SW) (Wakeup by outside release lever switch), 339=I_C10_WAKEUPRSN_ST3_TRL_HTCH_SW (TRL_HTCH_SW) (Wakeup by trailer hitch switch), 340=I_C10_WAKEUPRSN_ST3_TSSR_R_RB_SW (TSSR_R_RB_SW) (Wakeup by TSSR switch), 341=I_C10_WAKEUPRSN_ST3_CSL_SW (CSL_SW) (Wakeup by child security switch), 342=I_C10_WAKEUPRSN_ST3_GEAR_SW (GEAR_SW) (Wakeup by gear switch), 343=I_C10_WAKEUPRSN_ST3_AD_SW (AD_SW) (Wakeup by automated door switch), 344=I_C10_WAKEUPRSN_ST3_T2R_SW (T2R_SW) (Wakeup by automated door Tip2Run), 345=I_C10_WAKEUPRSN_ST3_HV_INTERLOCK_ERR (HV_INTERLOCK_ERR) (Wakeup by interlock error), 346=I_C10_WAKEUPRSN_ST3_NFC (NFC) (Wakeup by NFC), 347=I_C10_WAKEUPRSN_ST3_POLLING (POLLING) (Wakeup by Polling (COD belonging to the car was detected)), 348=I_C10_WAKEUPRSN_ST3_TSL_P_PSD (TSL_P_PSD) (Wakeup by Transmission Selector Lever P button pressed), 349=I_C10_WAKEUPRSN_ST3_STWHL_LVR_PSD (STWHL_LVR_PSD) (Wakeup by Steering Wheel Lever pressed), 350=I_C10_WAKEUPRSN_ST3_BAT14_DDP (BAT14_DDP) (Wakeup by Deep discharge protection), 351=I_C10_WAKEUPRSN_ST3_BAT14_LOWCHARGE (BAT14_LOWCHARGE) (Wakeup by low charge of the 12V battery), 352=I_C10_WAKEUPRSN_ST3_BAT14_CHARGECURR (BAT14_CHARGECURR) (Wakeup by charge Current detection), 353=I_C10_WAKEUPRSN_ST3_BAT14_IODM (BAT14_IODM) (Wakeup by IOD Measurement), 354=I_C10_WAKEUPRSN_ST3_BAT14_IODAVG (BAT14_IODAVG) (Wakeup by Average IOD Measurement), 355=I_C10_WAKEUPRSN_ST3_BMS_TMR (BMS_TMR) (Wakeup by BMS timer), 356=I_C10_WAKEUPRSN_ST3_CPD (CPD) (Wakeup by child presence detection), 357=I_C10_WAKEUPRSN_ST3_BMS_TP_EVENT (BMS_TP_EVENT) (Wakeup by thermal propagation event), 358=I_C10_WAKEUPRSN_ST3_BMS_TEMP_CHANGE (BMS_TEMP_CHANGE) (Wakeup by temperature change in HV Battery), 359=I_C10_WAKEUPRSN_ST3_BMS_CHARGE_OVER_MAX_OCV (BMS_CHARGE_OVER_MAX_OCV) (Wakeup by charge over maximum allowed OCV), 360=I_C10_WAKEUPRSN_ST3_BRK_PDL (BRK_PDL) (Wakeup by brake pedal), 361=I_C10_WAKEUPRSN_ST3_VEPM_TMR (VEPM_TMR) (Wakeup by RTC event from VEPM), 362=I_C10_WAKEUPRSN_ST3_PNM_TMR (PNM_TMR) (Wakeup by RTC event from PNM), 363=I_C10_WAKEUPRSN_ST3_BAT14_PREOPEN (BAT14_PREOPEN) (Wakeup by Bat14 for pre open request), 364=I_C10_WAKEUPRSN_ST3_BAT14_HIGHCHARGE (BAT14_HIGHCHARGE) (Wakeup by high charge of the 12V battery), 365=I_C10_WAKEUPRSN_ST3_BAT14_FULLCHRGEMG (BAT14_FULLCHRGEMG) (Wakeup by Bat14 for Fullcharge emergency), 366=I_C10_WAKEUPRSN_ST3_BAT14_CTREMG (BAT14_CTREMG) (Wakeup by Bat14 for CTR emergency), 380=I_C10_WAKEUPRSN_ST3_PNSEC (PNSec) (Wakeup by Secondary Power Network 12V), 381=I_C10_WAKEUPRSN_ST3_PNSEC_BCM (PNSec_BCM) (Wakeup by BCM (recharge battery) of Secondary Power Network 12V), 382=I_C10_WAKEUPRSN_ST3_PNSEC_DCDCCTRL (PNSec_DCDCCtrl) (Wakeup by DCDCCtrl (DCDC-converter for battery recharge) of Secondary Power Network 12V), 383=I_C10_WAKEUPRSN_ST3_PNSEC_DDP (PNSec_DDP) (Wakeup by DDP (deep discharge protection) of Secondary Power Network 12V), 384=I_C10_WAKEUPRSN_ST3_PNSEC_ICC (PNSec_ICC) (Wakeup by ICC (battery warning) of Secondary Power Network 12V), 385=I_C10_WAKEUPRSN_ST3_DEPTM_TMR (DEPTM_TMR) (Wakeup by Departure Time Timer), 390=I_C10_WAKEUPRSN_ST3_CNM_ETH_WAKEUPLINE_CS (CNM_ETH_WAKEUPLINE_CS) (Wakeup by Ethernet CS Line), 391=I_C10_WAKEUPRSN_ST3_CNM_DIAGNOSTIC_ETH_ACT_LINE (CNM_DIAGNOSTIC_ETH_ACT_LINE) (Wakeup by Ethernet Tester connected via the TX Line and pulled the diagnostic activation line), 400=I_C10_WAKEUPRSN_ST3_FOTA_TMR (FOTA_TMR) (Wakeup by FOTA Timer), 410=I_C10_WAKEUPRSN_ST3_BMS_RTM_AFTERRUN_DATA_TRANSFER (BMS_RTM_AFTERRUN_DATA_TRANSFER) (Wakeup by real time monitoring data transfer trigger of BMS), 1020=I_C10_WAKEUPRSN_ST3_RESERVE_3 (RESERVE_3) (Wakeup by Reserve 3), 1021=I_C10_WAKEUPRSN_ST3_RESERVE_2 (RESERVE_2) (Wakeup by Reserve 2), 1022=I_C10_WAKEUPRSN_ST3_RESERVE_1 (RESERVE_1) (Wakeup by Reserve 1), 1023=I_C10_WAKEUPRSN_ST3_SNA (SNA) (SNA value from data type)  # 1 - 99: Auflistung der Netzwerke, z.B. MAIN Wakeup by MAIN -CHASSIS Wakeup by CHASSIS -ENGINE Wakeup by ENGINE … Was ist mit LIN? 100 - 1022: ECU-spezifische Weckgründe, allgemein gehalten, damit die Gründe von allen ECUs verwendet werden können. / 1 - 99: Networks,e.g. MAIN Wakeup by MAIN - CHASSIS Wakeup by CHASSIS -ENGINE Wakeup by ENGINE | What about LIN? 100 - 1022: ECU-specific wakeup reasons, generically so that the reasons can be used by all ECUs
  compu method c12_0_4094_1_SNA: phys=raw for raw 0..4094, 4095=I_C12_0_4094_1_SNA_SNA (SNA) (SNA value from data type)
  compu method c12_km_p_h_0_409k4_0k1: phys=raw*0.1 for raw 0..4094, 4095=I_C12_KM_P_H_0_409K4_0K1_SNA (SNA) (SNA value from data type); unit km/h
  compu method km_per_h_0d1_0: phys=raw*0.1; unit km/h
  compu method c13_A_m409k6_409k4_0k1: phys=raw*0.1-409.6 for raw 0..8190, 8191=I_C13_A_M409K6_409K4_0K1_SNA (SNA) (SNA value from data type); unit A
  compu method A_0d1_m409d6: phys=raw*0.1-409.6; unit A
  compu method c16_m_pro_s_sq_m50_50_0d002: phys=raw*0.002-50 for raw 0..50000, 65535=I_C16_M_PRO_S_SQ_M50_50_0D002_SNA (SNA) (SNA value from data type); unit m/s²
  compu method m_per_s_sq_0d002_m50d0: phys=raw*0.002-50; unit m/s²
  compu method c16_deg_per_sec_m300_300_0d01: phys=raw*0.01-300 for raw 0..60000, 65535=I_C16_DEG_PER_SEC_M300_300_0D01_SNA (SNA) (SNA value from data type); unit °/s
  compu method deg_per_sec_0d01_m300: phys=raw*0.01-300; unit °/s
  compu method c16_deg_per_s_sq_m1200_1200_0d04: phys=raw*0.04-1200 for raw 0..60000, 65535=I_C16_DEG_PER_S_SQ_M1200_1200_0D04_SNA (SNA) (SNA value from data type); unit °/s²
  compu method deg_per_s_sq_0d04_m1200: phys=raw*0.04-1200; unit °/s²
  compu method c24_km_0_999999k9_0k1_Invld_SNA: phys=raw*0.1 for raw 0..9999999, 16777214=I_C24_KM_0_999999K9_0K1_INVLD_SNA_INVLD (INVLD) (Invalid), 16777215=I_C24_KM_0_999999K9_0K1_INVLD_SNA_SNA (SNA) (SNA value from data type); unit km
  compu method km_0d1_0: phys=raw*0.1; unit km
package /DataTypeMappingSets
  data type mapping set DATA_TYPE_MAPPING_SET
    data-type-maps:
      application-data-type=c02_Ndef_False_True_ST3, implementation-data-type=c02_Ndef_False_True_ST3
      application-data-type=c02_TransMd_Stat, implementation-data-type=c02_TransMd_Stat
      application-data-type=c3_HAD_Ext_Stat_ST3, implementation-data-type=c3_HAD_Ext_Stat_ST3
      application-data-type=c03_IMU_Force_Ang_Stat_ST3, implementation-data-type=c03_IMU_Force_Ang_Stat_ST3
      application-data-type=c03_IMU_Stat_ST3, implementation-data-type=c03_IMU_Stat_ST3
      application-data-type=c03_ISw_Stat, implementation-data-type=c03_ISw_Stat
      application-data-type=c03_PN14_ProdMd_Stat_ST3, implementation-data-type=c03_PN14_ProdMd_Stat_ST3
      application-data-type=c03_PN14_TDP_Sw_Stat, implementation-data-type=c03_PN14_TDP_Sw_Stat
      application-data-type=c04_VehOpMode, implementation-data-type=c04_VehOpMode
      application-data-type=c07_per_0to100_1_SNA, implementation-data-type=c07_per_0to100_1_SNA
      application-data-type=c07_0_111_1_SNA, implementation-data-type=c07_0_111_1_SNA
      application-data-type=c08_0_254_1_SNA_255, implementation-data-type=c08_0_254_1_SNA_255
      application-data-type=c08_0_255_1_SNA_na, implementation-data-type=c08_0_255_1_SNA_na
      application-data-type=c08_TmSync_Stat, implementation-data-type=c08_TmSync_Stat
      application-data-type=c08_UInt_SNA_na, implementation-data-type=c08_UInt_SNA_na
      application-data-type=c08_deg_m50_160_1, implementation-data-type=c08_deg_m50_160_1
      application-data-type=c08_degC_m40_85_0k5, implementation-data-type=c08_degC_m40_85_0k5
      application-data-type=c10_V_0_25k55_0k025, implementation-data-type=c10_V_0_25k55_0k025
      application-data-type=c10_WakeupRsn_ST3, implementation-data-type=c10_WakeupRsn_ST3
      application-data-type=c12_0_4094_1_SNA, implementation-data-type=c12_0_4094_1_SNA
      application-data-type=c12_km_p_h_0_409k4_0k1, implementation-data-type=c12_km_p_h_0_409k4_0k1
      application-data-type=c13_A_m409k6_409k4_0k1, implementation-data-type=c13_A_m409k6_409k4_0k1
      application-data-type=c16_CRC_woSNA, implementation-data-type=c16_CRC_woSNA
      application-data-type=c16_m_pro_s_sq_m50_50_0d002, implementation-data-type=c16_m_pro_s_sq_m50_50_0d002
      application-data-type=c16_deg_per_sec_m300_300_0d01, implementation-data-type=c16_deg_per_sec_m300_300_0d01
      application-data-type=c16_deg_per_s_sq_m1200_1200_0d04, implementation-data-type=c16_deg_per_s_sq_m1200_1200_0d04
      application-data-type=c24_km_0_999999k9_0k1_Invld_SNA, implementation-data-type=c24_km_0_999999k9_0k1_Invld_SNA
      application-data-type=c32_ns_0_4294967295_1_noSNA, implementation-data-type=c32_ns_0_4294967295_1_noSNA
      application-data-type=c32_s_0_4294967295_1_noSNA, implementation-data-type=c32_s_0_4294967295_1_noSNA
      application-data-type=DC_BOOL, implementation-data-type=DC_BOOL
      application-data-type=NM_ActvWakeup, implementation-data-type=NM_ActvWakeup
      application-data-type=NM_Coord_Id, implementation-data-type=NM_Coord_Id
      application-data-type=NM_Coord_SleepRdy, implementation-data-type=NM_Coord_SleepRdy
      application-data-type=NM_PartNw_Info, implementation-data-type=NM_PartNw_Info
      application-data-type=NM_RepeatMsg_Rq, implementation-data-type=NM_RepeatMsg_Rq
      application-data-type=Rsrv03, implementation-data-type=Rsrv03
      application-data-type=Rsrv05, implementation-data-type=Rsrv05
      application-data-type=Rsrv08, implementation-data-type=Rsrv08
      application-data-type=Rsrv09, implementation-data-type=Rsrv09
      application-data-type=Rsrv16, implementation-data-type=Rsrv16
      application-data-type=Rsrv32, implementation-data-type=Rsrv32
package /SystemSignalGroups
  20 x system signal group:
    ADAS_HAD_Stat_IDC_M_FSI_Pr5_ST3: system-signal=[ADAS_HAD_Ext_Stat_M_FSI_ST3, CRC_ADAS_HAD_Stat_IDC_M_FSI_Pr5_ST3, Rsrv1_ADAS_HAD_Stat_IDC_M_FSI_Pr5_ST3, Rsrv2_ADAS_HAD_Stat_IDC_M_FSI_Pr5_ST3, SQC_ADAS_HAD_Stat_IDC_M_FSI_Pr5_ST3]  # Zustand hochautomatisiertes Fahren IDC Master / Highly automated driving state Master
    ADAS_HAD_Stat_IDC_M_FSI_Pr5_ST3_azb6uvmzdxiqsmnean8m9u52u: system-signal=[ADAS_HAD_Ext_Stat_M_FSI_ST3, CRC_ADAS_HAD_Stat_IDC_M_FSI_Pr5_ST3, Rsrv1_ADAS_HAD_Stat_IDC_M_FSI_Pr5_ST3, Rsrv2_ADAS_HAD_Stat_IDC_M_FSI_Pr5_ST3, SQC_ADAS_HAD_Stat_IDC_M_FSI_Pr5_ST3]  # Zustand hochautomatisiertes Fahren IDC Master (degraded) / Highly automated driving state Master (degraded)
    DI_Odo_Pr5_ST3: system-signal=[CRC_DI_Odo_Pr5_ST3, Odo_ST3, SQC_DI_Odo_Pr5_ST3]  # DriverInformation Odometer
    DI_Odo_Pr5_ST3_e68xmtlkywxgxsdwekdjjhw3t: system-signal=[CRC_DI_Odo_Pr5_ST3, Odo_ST3, SQC_DI_Odo_Pr5_ST3]  # DriverInformation Odometer (degraded)
    Ign_Stat_Pr5_ST3: system-signal=[CRC_Ign_Stat_Pr5_ST3, ISw_Stat_ST3, KG_StartSw_Psd_ST3, SQC_Ign_Stat_Pr5_ST3, Veh_Op_Mode_ST3]  # Zuendungsstatus / Ignition state
    Ign_Stat_Pr5_ST3_csgs1dv6drms80o1i9p49677w: system-signal=[CRC_Ign_Stat_Pr5_ST3, ISw_Stat_ST3, KG_StartSw_Psd_ST3, SQC_Ign_Stat_Pr5_ST3, Veh_Op_Mode_ST3]  # Zuendungsstatus (degraded) / Ignition state (degraded)
    IMU_A_Output_Fast_Pr5_ST3: system-signal=[CRC_IMU_A_Output_Fast_Pr5_ST3, IMU_A_AngAcc_Stat_Fast_ST3, IMU_A_AngAcc_X_Fast_ST3, IMU_A_AngAcc_Y_Fast_ST3, IMU_A_AngAcc_Z_Fast_ST3, IMU_A_AngRate_X_Fast_ST3, IMU_A_AngRate_Y_Fast_ST3, IMU_A_AngRate_Z_Fast_ST3, IMU_A_AngRates_Stat_Fast_ST3, IMU_A_SpecForce_Stat_Fast_ST3, IMU_A_SpecForce_X_Fast_ST3, IMU_A_SpecForce_Y_Fast_ST3, IMU_A_SpecForce_Z_Fast_ST3, IMU_A_Stat_Fast_ST3, IMU_A_Temp_Fast_ST3, IMU_A_TmStmp_NanoSec_Fast_ST3, IMU_A_TmStmp_Sec_Fast_ST3, IMU_A_TmSync_Stat_Fast_ST3, Rsrv01_IMU_A_Output_Fast_Pr5_ST3, Rsrv02_IMU_A_Output_Fast_Pr5_ST3, Rsrv03_IMU_A_Output_Fast_Pr5_ST3, Rsrv04_IMU_A_Output_Fast_Pr5_ST3, Rsrv05_IMU_A_Output_Fast_Pr5_ST3, Rsrv06_IMU_A_Output_Fast_Pr5_ST3, Rsrv07_IMU_A_Output_Fast_Pr5_ST3, SQC_IMU_A_Output_Fast_Pr5_ST3]  # IMU A Output Pr 5 ST3
    IMU_A_Output_Fast_Pr5_ST3_5ym0lyqjosyobfhfksta75zc4: system-signal=[CRC_IMU_A_Output_Fast_Pr5_ST3, IMU_A_AngAcc_Stat_Fast_ST3, IMU_A_AngAcc_X_Fast_ST3, IMU_A_AngAcc_Y_Fast_ST3, IMU_A_AngAcc_Z_Fast_ST3, IMU_A_AngRate_X_Fast_ST3, IMU_A_AngRate_Y_Fast_ST3, IMU_A_AngRate_Z_Fast_ST3, IMU_A_AngRates_Stat_Fast_ST3, IMU_A_SpecForce_Stat_Fast_ST3, IMU_A_SpecForce_X_Fast_ST3, IMU_A_SpecForce_Y_Fast_ST3, IMU_A_SpecForce_Z_Fast_ST3, IMU_A_Stat_Fast_ST3, IMU_A_Temp_Fast_ST3, IMU_A_TmStmp_NanoSec_Fast_ST3, IMU_A_TmStmp_Sec_Fast_ST3, IMU_A_TmSync_Stat_Fast_ST3, Rsrv01_IMU_A_Output_Fast_Pr5_ST3, Rsrv02_IMU_A_Output_Fast_Pr5_ST3, Rsrv03_IMU_A_Output_Fast_Pr5_ST3, Rsrv04_IMU_A_Output_Fast_Pr5_ST3, Rsrv05_IMU_A_Output_Fast_Pr5_ST3, Rsrv06_IMU_A_Output_Fast_Pr5_ST3, Rsrv07_IMU_A_Output_Fast_Pr5_ST3, SQC_IMU_A_Output_Fast_Pr5_ST3]  # IMU A Output Pr 5 ST3 (degraded)
    IMU_B_Output_Fast_Pr5_ST3: system-signal=[CRC_IMU_B_Output_Fast_Pr5_ST3, IMU_B_AngAcc_Stat_Fast_ST3, IMU_B_AngAcc_X_Fast_ST3, IMU_B_AngAcc_Y_Fast_ST3, IMU_B_AngAcc_Z_Fast_ST3, IMU_B_AngRate_X_Fast_ST3, IMU_B_AngRate_Y_Fast_ST3, IMU_B_AngRate_Z_Fast_ST3, IMU_B_AngRates_Stat_Fast_ST3, IMU_B_SpecForce_Stat_Fast_ST3, IMU_B_SpecForce_X_Fast_ST3, IMU_B_SpecForce_Y_Fast_ST3, IMU_B_SpecForce_Z_Fast_ST3, IMU_B_Stat_Fast_ST3, IMU_B_Temp_Fast_ST3, IMU_B_TmStmp_NanoSec_Fast_ST3, IMU_B_TmStmp_Sec_Fast_ST3, IMU_B_TmSync_Stat_Fast_ST3, Rsrv01_IMU_B_Output_Fast_Pr5_ST3, Rsrv02_IMU_B_Output_Fast_Pr5_ST3, Rsrv03_IMU_B_Output_Fast_Pr5_ST3, Rsrv04_IMU_B_Output_Fast_Pr5_ST3, Rsrv05_IMU_B_Output_Fast_Pr5_ST3, Rsrv06_IMU_B_Output_Fast_Pr5_ST3, Rsrv07_IMU_B_Output_Fast_Pr5_ST3, SQC_IMU_B_Output_Fast_Pr5_ST3]  # IMU B Output Pr 5 ST3
    IMU_B_Output_Fast_Pr5_ST3_dk96owji618h3fdh75ws5eyj3: system-signal=[CRC_IMU_B_Output_Fast_Pr5_ST3, IMU_B_AngAcc_Stat_Fast_ST3, IMU_B_AngAcc_X_Fast_ST3, IMU_B_AngAcc_Y_Fast_ST3, IMU_B_AngAcc_Z_Fast_ST3, IMU_B_AngRate_X_Fast_ST3, IMU_B_AngRate_Y_Fast_ST3, IMU_B_AngRate_Z_Fast_ST3, IMU_B_AngRates_Stat_Fast_ST3, IMU_B_SpecForce_Stat_Fast_ST3, IMU_B_SpecForce_X_Fast_ST3, IMU_B_SpecForce_Y_Fast_ST3, IMU_B_SpecForce_Z_Fast_ST3, IMU_B_Stat_Fast_ST3, IMU_B_Temp_Fast_ST3, IMU_B_TmStmp_NanoSec_Fast_ST3, IMU_B_TmStmp_Sec_Fast_ST3, IMU_B_TmSync_Stat_Fast_ST3, Rsrv01_IMU_B_Output_Fast_Pr5_ST3, Rsrv02_IMU_B_Output_Fast_Pr5_ST3, Rsrv03_IMU_B_Output_Fast_Pr5_ST3, Rsrv04_IMU_B_Output_Fast_Pr5_ST3, Rsrv05_IMU_B_Output_Fast_Pr5_ST3, Rsrv06_IMU_B_Output_Fast_Pr5_ST3, Rsrv07_IMU_B_Output_Fast_Pr5_ST3, SQC_IMU_B_Output_Fast_Pr5_ST3]  # IMU B Output Pr 5 ST3 (degraded)
    VSS_TP_Auth_ST3: system-signal=[VSS_TP_Auth_0_ST3, VSS_TP_Auth_1_ST3, VSS_TP_Auth_2_ST3, VSS_TP_Auth_3_ST3, VSS_TP_Auth_4_ST3, VSS_TP_Auth_5_ST3, VSS_TP_Auth_6_ST3, VSS_TP_Auth_7_ST3]  # VSS-Transportprotokoll für Authentifizierung / Vehicle Security System Transport Protocol for authentication broadcast
    VSS_TP_Auth_ST3_6j4id7sghlvlbroli4wjozjik: system-signal=[VSS_TP_Auth_0_ST3, VSS_TP_Auth_1_ST3, VSS_TP_Auth_2_ST3, VSS_TP_Auth_3_ST3, VSS_TP_Auth_4_ST3, VSS_TP_Auth_5_ST3, VSS_TP_Auth_6_ST3, VSS_TP_Auth_7_ST3]  # VSS-Transportprotokoll für Authentifizierung (degraded) / Vehicle Security System Transport Protocol for authentication broadcast (degraded)
    VSS_TP_RealTmOffset_ST3: system-signal=[VSS_TP_RealTmOffset_0_ST3, VSS_TP_RealTmOffset_1_ST3, VSS_TP_RealTmOffset_2_ST3, VSS_TP_RealTmOffset_3_ST3, VSS_TP_RealTmOffset_4_ST3, VSS_TP_RealTmOffset_5_ST3, VSS_TP_RealTmOffset_6_ST3, VSS_TP_RealTmOffset_7_ST3]  # VSS-Transportprotokoll für Echtzeit-Offset / Vehicle Security System Transport Protocol for real time offset broadcast
    VSS_TP_RealTmOffset_ST3_1t7vc44gftc0wv35k5kgc2in9: system-signal=[VSS_TP_RealTmOffset_0_ST3, VSS_TP_RealTmOffset_1_ST3, VSS_TP_RealTmOffset_2_ST3, VSS_TP_RealTmOffset_3_ST3, VSS_TP_RealTmOffset_4_ST3, VSS_TP_RealTmOffset_5_ST3, VSS_TP_RealTmOffset_6_ST3, VSS_TP_RealTmOffset_7_ST3]  # VSS-Transportprotokoll für Echtzeit-Offset (degraded) / Vehicle Security System Transport Protocol for real time offset broadcast (degraded)
    VSS_TP_SecTickCount_Lvl1_ST3: system-signal=[VSS_TP_SecTickCount_Lvl1_0_ST3, VSS_TP_SecTickCount_Lvl1_1_ST3, VSS_TP_SecTickCount_Lvl1_2_ST3, VSS_TP_SecTickCount_Lvl1_3_ST3, VSS_TP_SecTickCount_Lvl1_4_ST3, VSS_TP_SecTickCount_Lvl1_5_ST3, VSS_TP_SecTickCount_Lvl1_6_ST3, VSS_TP_SecTickCount_Lvl1_7_ST3]  # VSS-Transportprotokoll für sichere Zeit Stufe 1 / Vehicle Security System Transport Protocol for secure tick count level #1
    VSS_TP_SecTickCount_Lvl1_ST3_mzmfdqtqz5kvv1kfpvg0kql3: system-signal=[VSS_TP_SecTickCount_Lvl1_0_ST3, VSS_TP_SecTickCount_Lvl1_1_ST3, VSS_TP_SecTickCount_Lvl1_2_ST3, VSS_TP_SecTickCount_Lvl1_3_ST3, VSS_TP_SecTickCount_Lvl1_4_ST3, VSS_TP_SecTickCount_Lvl1_5_ST3, VSS_TP_SecTickCount_Lvl1_6_ST3, VSS_TP_SecTickCount_Lvl1_7_ST3]  # VSS-Transportprotokoll für sichere Zeit Stufe 1 (degraded) / Vehicle Security System Transport Protocol for secure tick count level #1 (degraded)
    VSS_TP_SharedSecret_ST3: system-signal=[VSS_TP_SharedSecret_0_ST3, VSS_TP_SharedSecret_1_ST3, VSS_TP_SharedSecret_2_ST3, VSS_TP_SharedSecret_3_ST3, VSS_TP_SharedSecret_4_ST3, VSS_TP_SharedSecret_5_ST3, VSS_TP_SharedSecret_6_ST3, VSS_TP_SharedSecret_7_ST3]  # VSS-Transportprotokoll für gemeinsames Geheimnis / Vehicle Security System Transport Protocol for shared secret broadcast
    VSS_TP_SharedSecret_ST3_8pj4t8t4rm3tw3pk5hj7vonti: system-signal=[VSS_TP_SharedSecret_0_ST3, VSS_TP_SharedSecret_1_ST3, VSS_TP_SharedSecret_2_ST3, VSS_TP_SharedSecret_3_ST3, VSS_TP_SharedSecret_4_ST3, VSS_TP_SharedSecret_5_ST3, VSS_TP_SharedSecret_6_ST3, VSS_TP_SharedSecret_7_ST3]  # VSS-Transportprotokoll für gemeinsames Geheimnis (degraded) / Vehicle Security System Transport Protocol for shared secret broadcast (degraded)
    VSS_TP_VIN_ST3: system-signal=[VSS_TP_VIN_0_ST3, VSS_TP_VIN_1_ST3, VSS_TP_VIN_2_ST3, VSS_TP_VIN_3_ST3, VSS_TP_VIN_4_ST3, VSS_TP_VIN_5_ST3, VSS_TP_VIN_6_ST3, VSS_TP_VIN_7_ST3]  # VSS-Transportprotokoll für Fahrzeugidentifikationsnummer / Vehicle Security System Transport Protocol for Vehicle Identification Number
    VSS_TP_VIN_ST3_bz1xsv84cxzl09j028gn39p69: system-signal=[VSS_TP_VIN_0_ST3, VSS_TP_VIN_1_ST3, VSS_TP_VIN_2_ST3, VSS_TP_VIN_3_ST3, VSS_TP_VIN_4_ST3, VSS_TP_VIN_5_ST3, VSS_TP_VIN_6_ST3, VSS_TP_VIN_7_ST3]  # VSS-Transportprotokoll für Fahrzeugidentifikationsnummer (degraded) / Vehicle Security System Transport Protocol for Vehicle Identification Number (degraded)
package /EcuInstances
  ecu instance IDC_M_FSI:
    associated-com-i-pdu-group=[IDC_M_FSI_HAD_IMU_Tx_PNC_All_Active, IDC_M_FSI_HAD_IMU_Tx_PNC_20, IDC_M_FSI_HAD_IMU_Tx_PNC_23, IDC_M_FSI_HAD_IMU_Rx_PNC_All_Active, IDC_M_FSI_HAD_IMU_Rx_PNC_20, IDC_M_FSI_HAD_IMU_Rx_PNC_23]
    com-configuration-gw-time-base=0.005
    com-configuration-rx-time-base=0.005
    com-configuration-tx-time-base=0.005
    pn-reset-time=1.1
    pnc-prepare-sleep-timer=1.3
    sleep-mode-supported=true
    wake-up-over-bus-supported=true
    can communication controller IDC_M_FSI_HAD_IMU: wake-up-by-controller-supported=true, can-controller-attributes=can-controller-configuration-requirements={can-controller-fd-requirements={max-number-of-time-quanta-per-bit=20, max-sample-point=75.0, max-sync-jump-width=25.0, min-number-of-time-quanta-per-bit=20, min-sample-point=75.0, min-sync-jump-width=25.0, padding-value=0, tx-bit-rate-switch=true}, max-number-of-time-quanta-per-bit=40, max-sample-point=80.0, max-sync-jump-width=20.0, min-number-of-time-quanta-per-bit=40, min-sample-point=80.0, min-sync-jump-width=20.0}
    can communication connector IDC_M_FSI_HAD_IMU_4176sqdaqq92x7hd4zy6lbigy: comm-controller=IDC_M_FSI_HAD_IMU, pnc-gateway-type=NONE, pnc-wakeup-data-mask=2415919360
  ecu instance IMU_B:
    associated-com-i-pdu-group=[IMU_B_HAD_IMU_Tx_PNC_All_Active, IMU_B_HAD_IMU_Tx_PNC_20, IMU_B_HAD_IMU_Tx_PNC_23, IMU_B_HAD_IMU_Rx_PNC_All_Active, IMU_B_HAD_IMU_Rx_PNC_20, IMU_B_HAD_IMU_Rx_PNC_23]
    com-configuration-gw-time-base=0.005
    com-configuration-rx-time-base=0.005
    com-configuration-tx-time-base=0.005
    pn-reset-time=1.1
    pnc-prepare-sleep-timer=1.3
    sleep-mode-supported=true
    wake-up-over-bus-supported=true
    can communication controller IMU_B_HAD_IMU: wake-up-by-controller-supported=true, can-controller-attributes=can-controller-configuration-requirements={can-controller-fd-requirements={max-number-of-time-quanta-per-bit=20, max-sample-point=75.0, max-sync-jump-width=25.0, min-number-of-time-quanta-per-bit=20, min-sample-point=75.0, min-sync-jump-width=25.0, padding-value=0, tx-bit-rate-switch=true}, max-number-of-time-quanta-per-bit=40, max-sample-point=80.0, max-sync-jump-width=20.0, min-number-of-time-quanta-per-bit=40, min-sample-point=80.0, min-sync-jump-width=20.0}
    can communication connector IMU_B_HAD_IMU_e7z1zoxtgl3nmnp12dav9hlcf: comm-controller=IMU_B_HAD_IMU, pnc-gateway-type=ACTIVE, pnc-wakeup-data-mask=2415919360
package /Pdus/HAD_IMU/PKG_HAD_IMU
  pdu IMU_A_Output_Fast_ST3: length=40, minimum-delay=0.005, transmission-mode-true-timing=event-controlled-timing=number-of-repetitions=0, unused-bit-pattern=255  # IMU A Output ST3
    signal CRC_IMU_A_Output_Fast_Pr5_ST3: start 0, 16 bit, little-endian, data-type-policy=OVERRIDE, i-signal-type=PRIMITIVE, init-value=19231, base-type=uint16, data-constr=c16_CRC_woSNA, to IDC_M_FSI(timeout 0.3 s)  # CRC-Checksumme der Signal Gruppe gemäß AUTOSAR Profil 5 / CRC-checksum of signal group according to AUTOSAR Profile 5
    signal IMU_A_AngAcc_Stat_Fast_ST3: start 27, 3 bit, little-endian, data-type-policy=OVERRIDE, i-signal-type=PRIMITIVE, init-value=0, base-type=uint8, compu-method=c03_IMU_Force_Ang_Stat_ST3, data-constr=c03_IMU_Force_Ang_Stat_ST3, to IDC_M_FSI(timeout 0.3 s)  # Status der Winkelbeschleunigungssignale fast / Status of angular acceleration signals fast
    signal IMU_A_AngAcc_X_Fast_ST3: start 55, 16 bit, little-endian, data-type-policy=OVERRIDE, i-signal-type=PRIMITIVE, init-value=65535, base-type=uint16, invalid-value=65535, compu-method=c16_deg_per_s_sq_m1200_1200_0d04, data-constr=c16_deg_per_s_sq_m1200_1200_0d04, to IDC_M_FSI(timeout 0.3 s)  # Winkelbeschleunigung um die X-Achse fast / Angular acceleration about X axis fast
    signal IMU_A_AngAcc_Y_Fast_ST3: start 71, 16 bit, little-endian, data-type-policy=OVERRIDE, i-signal-type=PRIMITIVE, init-value=65535, base-type=uint16, invalid-value=65535, compu-method=c16_deg_per_s_sq_m1200_1200_0d04, data-constr=c16_deg_per_s_sq_m1200_1200_0d04, to IDC_M_FSI(timeout 0.3 s)  # Winkelbeschleunigung um die Y-Achse fast / Angular acceleration about Y axis fast
    signal IMU_A_AngAcc_Z_Fast_ST3: start 87, 16 bit, little-endian, data-type-policy=OVERRIDE, i-signal-type=PRIMITIVE, init-value=65535, base-type=uint16, invalid-value=65535, compu-method=c16_deg_per_s_sq_m1200_1200_0d04, data-constr=c16_deg_per_s_sq_m1200_1200_0d04, to IDC_M_FSI(timeout 0.3 s)  # Winkelbeschleunigung um die Z-Achse fast / Angular acceleration about Z axis fast
    signal IMU_A_AngRate_X_Fast_ST3: start 103, 16 bit, little-endian, data-type-policy=OVERRIDE, i-signal-type=PRIMITIVE, init-value=65535, base-type=uint16, invalid-value=65535, compu-method=c16_deg_per_sec_m300_300_0d01, data-constr=c16_deg_per_sec_m300_300_0d01, to IDC_M_FSI(timeout 0.3 s)  # Drehrate über die X-Achse fast / Angular rate about X axis fast
    signal IMU_A_AngRate_Y_Fast_ST3: start 119, 16 bit, little-endian, data-type-policy=OVERRIDE, i-signal-type=PRIMITIVE, init-value=65535, base-type=uint16, invalid-value=65535, compu-method=c16_deg_per_sec_m300_300_0d01, data-constr=c16_deg_per_sec_m300_300_0d01, to IDC_M_FSI(timeout 0.3 s)  # Drehrate über die Y-Achse fast / Angular rate about Y axis fast
    signal IMU_A_AngRate_Z_Fast_ST3: start 135, 16 bit, little-endian, data-type-policy=OVERRIDE, i-signal-type=PRIMITIVE, init-value=65535, base-type=uint16, invalid-value=65535, compu-method=c16_deg_per_sec_m300_300_0d01, data-constr=c16_deg_per_sec_m300_300_0d01, to IDC_M_FSI(timeout 0.3 s)  # Drehrate über die Z-Achse fast / Angular rate about Z axis fast
    signal IMU_A_AngRates_Stat_Fast_ST3: start 30, 3 bit, little-endian, data-type-policy=OVERRIDE, i-signal-type=PRIMITIVE, init-value=0, base-type=uint8, compu-method=c03_IMU_Force_Ang_Stat_ST3, data-constr=c03_IMU_Force_Ang_Stat_ST3, to IDC_M_FSI(timeout 0.3 s)  # Status der Drehratensignale fast / Status of angular rate signals fast
    signal IMU_A_SpecForce_Stat_Fast_ST3: start 36, 3 bit, little-endian, data-type-policy=OVERRIDE, i-signal-type=PRIMITIVE, init-value=0, base-type=uint8, compu-method=c03_IMU_Force_Ang_Stat_ST3, data-constr=c03_IMU_Force_Ang_Stat_ST3, to IDC_M_FSI(timeout 0.3 s)  # Status spezifischer Kraftsignale fast / Status of specific force signals fast
    signal IMU_A_SpecForce_X_Fast_ST3: start 151, 16 bit, little-endian, data-type-policy=OVERRIDE, i-signal-type=PRIMITIVE, init-value=65535, base-type=uint16, invalid-value=65535, compu-method=c16_m_pro_s_sq_m50_50_0d002, data-constr=c16_m_pro_s_sq_m50_50_0d002, to IDC_M_FSI(timeout 0.3 s)  # Spezifische Kraft entlang der X-Achse fast / Specific force along X axis fast
    signal IMU_A_SpecForce_Y_Fast_ST3: start 167, 16 bit, little-endian, data-type-policy=OVERRIDE, i-signal-type=PRIMITIVE, init-value=65535, base-type=uint16, invalid-value=65535, compu-method=c16_m_pro_s_sq_m50_50_0d002, data-constr=c16_m_pro_s_sq_m50_50_0d002, to IDC_M_FSI(timeout 0.3 s)  # Spezifische Kraft entlang der Y-Achse fast / Specific force along Y axis fast
    signal IMU_A_SpecForce_Z_Fast_ST3: start 183, 16 bit, little-endian, data-type-policy=OVERRIDE, i-signal-type=PRIMITIVE, init-value=65535, base-type=uint16, invalid-value=65535, compu-method=c16_m_pro_s_sq_m50_50_0d002, data-constr=c16_m_pro_s_sq_m50_50_0d002, to IDC_M_FSI(timeout 0.3 s)  # Spezifische Kraft entlang der Z-Achse fast / Specific force along Z axis fast
    signal IMU_A_Stat_Fast_ST3: start 24, 3 bit, little-endian, data-type-policy=OVERRIDE, i-signal-type=PRIMITIVE, init-value=0, base-type=uint8, compu-method=c03_IMU_Stat_ST3, data-constr=c03_IMU_Stat_ST3, to IDC_M_FSI(timeout 0.3 s)  # Gesamtstatus der IMU fast / Overall IMU status fast
    signal IMU_A_Temp_Fast_ST3: start 39, 8 bit, little-endian, data-type-policy=OVERRIDE, i-signal-type=PRIMITIVE, init-value=255, base-type=uint8, invalid-value=255, compu-method=c08_deg_m50_160_1, data-constr=c08_deg_m50_160_1, to IDC_M_FSI(timeout 0.3 s)  # IMU-Temperatur fast / IMU Temperature fast
    signal IMU_A_TmStmp_NanoSec_Fast_ST3: start 199, 32 bit, little-endian, data-type-policy=OVERRIDE, i-signal-type=PRIMITIVE, init-value=0, base-type=uint32, compu {identical; unit ns}, data-constr=c32_ns_0_4294967295_1_noSNA, to IDC_M_FSI(timeout 0.3 s)  # IMU Zeitstempel, Ziffernbruchteil in Nanosekunden fast / IMU Time Stamp, fractional digits part in nanoseconds fast
    signal IMU_A_TmStmp_Sec_Fast_ST3: start 231, 32 bit, little-endian, data-type-policy=OVERRIDE, i-signal-type=PRIMITIVE, init-value=0, base-type=uint32, compu {identical; unit s}, data-constr=c32_s_0_4294967295_1_noSNA, to IDC_M_FSI(timeout 0.3 s)  # IMU Zeitstempel, ganze Sekunde Teil fast / IMU Time Stamp, whole seconds part fast
    signal IMU_A_TmSync_Stat_Fast_ST3: start 47, 8 bit, little-endian, data-type-policy=OVERRIDE, i-signal-type=PRIMITIVE, init-value=128, base-type=uint8, compu-method=c08_TmSync_Stat, to IDC_M_FSI(timeout 0.3 s)  # Status der globalen Zeitsynchronisierung fast / Global Time Sync Status fast
    signal SQC_IMU_A_Output_Fast_Pr5_ST3: start 16, 8 bit, little-endian, data-type-policy=OVERRIDE, i-signal-type=PRIMITIVE, init-value=0, base-type=uint8, compu {identical}, data-constr=c08_0_255_1_SNA_na, to IDC_M_FSI(timeout 0.3 s)  # Sequenzzähler / Sequence counter
    signal Rsrv01_IMU_A_Output_Fast_Pr5_ST3: start 263, 9 bit, little-endian, data-type-policy=OVERRIDE, i-signal-type=PRIMITIVE, init-value=511, base-type=uint16, invalid-value=511, range raw 0..511, to IDC_M_FSI  # Rsrv 01 IMU A Output Pr 5 ST3 fast
    signal Rsrv02_IMU_A_Output_Fast_Pr5_ST3: start 272, 8 bit, little-endian, data-type-policy=OVERRIDE, i-signal-type=PRIMITIVE, init-value=255, base-type=uint8, invalid-value=255, range raw 0..255, to IDC_M_FSI  # Rsrv 02 IMU A Output Pr 5 ST3 fast
    signal Rsrv03_IMU_A_Output_Fast_Pr5_ST3: start 280, 8 bit, little-endian, data-type-policy=OVERRIDE, i-signal-type=PRIMITIVE, init-value=255, base-type=uint8, invalid-value=255, range raw 0..255, to IDC_M_FSI  # Rsrv 03 IMU A Output Pr 5 ST3 fast
    signal Rsrv04_IMU_A_Output_Fast_Pr5_ST3: start 288, 8 bit, little-endian, data-type-policy=OVERRIDE, i-signal-type=PRIMITIVE, init-value=255, base-type=uint8, invalid-value=255, range raw 0..255, to IDC_M_FSI  # Rsrv 04 IMU A Output Pr 5 ST3 fast
    signal Rsrv05_IMU_A_Output_Fast_Pr5_ST3: start 296, 8 bit, little-endian, data-type-policy=OVERRIDE, i-signal-type=PRIMITIVE, init-value=255, base-type=uint8, invalid-value=255, range raw 0..255, to IDC_M_FSI  # Rsrv 05 IMU A Output Pr 5 ST3 fast
    signal Rsrv06_IMU_A_Output_Fast_Pr5_ST3: start 304, 16 bit, little-endian, data-type-policy=OVERRIDE, i-signal-type=PRIMITIVE, init-value=65535, base-type=uint16, invalid-value=65535, range raw 0..65535, to IDC_M_FSI  # Rsrv 06 IMU A Output Pr 5 ST3 fast
    signal Rsrv07_IMU_A_Output_Fast_Pr5_ST3: start 33, 3 bit, little-endian, data-type-policy=OVERRIDE, i-signal-type=PRIMITIVE, init-value=7, base-type=uint8, invalid-value=7, range raw 0..7, to IDC_M_FSI  # Rsrv 07 IMU A Output Pr 5 ST3 fast
    mapping IMU_A_Output_Fast_Pr5_ST3_5ym0lyqjosyobfhfksta75zc4: i-signal-group=IMU_A_Output_Fast_Pr5_ST3_5ym0lyqjosyobfhfksta75zc4, packing-byte-order=little-endian, transfer-property=TRIGGERED
  pdu IMU_B_Output_Fast_ST3: length=40, minimum-delay=0.005, transmission-mode-true-timing=event-controlled-timing=number-of-repetitions=0, unused-bit-pattern=255  # IMU B Output ST3
    signal CRC_IMU_B_Output_Fast_Pr5_ST3: start 0, 16 bit, little-endian, data-type-policy=OVERRIDE, i-signal-type=PRIMITIVE, init-value=50979, base-type=uint16, data-constr=c16_CRC_woSNA, to IDC_M_FSI(timeout 0.3 s)  # CRC-Checksumme der Signal Gruppe gemäß AUTOSAR Profil 5 / CRC-checksum of signal group according to AUTOSAR Profile 5
    signal IMU_B_AngAcc_Stat_Fast_ST3: start 27, 3 bit, little-endian, data-type-policy=OVERRIDE, i-signal-type=PRIMITIVE, init-value=0, base-type=uint8, compu-method=c03_IMU_Force_Ang_Stat_ST3, data-constr=c03_IMU_Force_Ang_Stat_ST3, to IDC_M_FSI(timeout 0.3 s)  # Status der Winkelbeschleunigungssignale fast / Status of angular acceleration signals fast
    signal IMU_B_AngAcc_X_Fast_ST3: start 55, 16 bit, little-endian, data-type-policy=OVERRIDE, i-signal-type=PRIMITIVE, init-value=65535, base-type=uint16, invalid-value=65535, compu-method=c16_deg_per_s_sq_m1200_1200_0d04, data-constr=c16_deg_per_s_sq_m1200_1200_0d04, to IDC_M_FSI(timeout 0.3 s)  # Winkelbeschleunigung um die X-Achse fast / Angular acceleration about X axis fast
    signal IMU_B_AngAcc_Y_Fast_ST3: start 71, 16 bit, little-endian, data-type-policy=OVERRIDE, i-signal-type=PRIMITIVE, init-value=65535, base-type=uint16, invalid-value=65535, compu-method=c16_deg_per_s_sq_m1200_1200_0d04, data-constr=c16_deg_per_s_sq_m1200_1200_0d04, to IDC_M_FSI(timeout 0.3 s)  # Winkelbeschleunigung um die Y-Achse fast / Angular acceleration about Y axis fast
    signal IMU_B_AngAcc_Z_Fast_ST3: start 87, 16 bit, little-endian, data-type-policy=OVERRIDE, i-signal-type=PRIMITIVE, init-value=65535, base-type=uint16, invalid-value=65535, compu-method=c16_deg_per_s_sq_m1200_1200_0d04, data-constr=c16_deg_per_s_sq_m1200_1200_0d04, to IDC_M_FSI(timeout 0.3 s)  # Winkelbeschleunigung um die Z-Achse fast / Angular acceleration about Z axis fast
    signal IMU_B_AngRate_X_Fast_ST3: start 103, 16 bit, little-endian, data-type-policy=OVERRIDE, i-signal-type=PRIMITIVE, init-value=65535, base-type=uint16, invalid-value=65535, compu-method=c16_deg_per_sec_m300_300_0d01, data-constr=c16_deg_per_sec_m300_300_0d01, to IDC_M_FSI(timeout 0.3 s)  # Drehrate über die X-Achse fast / Angular rate about X axis fast
    signal IMU_B_AngRate_Y_Fast_ST3: start 119, 16 bit, little-endian, data-type-policy=OVERRIDE, i-signal-type=PRIMITIVE, init-value=65535, base-type=uint16, invalid-value=65535, compu-method=c16_deg_per_sec_m300_300_0d01, data-constr=c16_deg_per_sec_m300_300_0d01, to IDC_M_FSI(timeout 0.3 s)  # Drehrate über die Y-Achse fast / Angular rate about Y axis fast
    signal IMU_B_AngRate_Z_Fast_ST3: start 135, 16 bit, little-endian, data-type-policy=OVERRIDE, i-signal-type=PRIMITIVE, init-value=65535, base-type=uint16, invalid-value=65535, compu-method=c16_deg_per_sec_m300_300_0d01, data-constr=c16_deg_per_sec_m300_300_0d01, to IDC_M_FSI(timeout 0.3 s)  # Drehrate über die Z-Achse fast / Angular rate about Z axis fast
    signal IMU_B_AngRates_Stat_Fast_ST3: start 30, 3 bit, little-endian, data-type-policy=OVERRIDE, i-signal-type=PRIMITIVE, init-value=0, base-type=uint8, compu-method=c03_IMU_Force_Ang_Stat_ST3, data-constr=c03_IMU_Force_Ang_Stat_ST3, to IDC_M_FSI(timeout 0.3 s)  # Status der Drehratensignale fast / Status of angular rate signals fast
    signal IMU_B_SpecForce_Stat_Fast_ST3: start 36, 3 bit, little-endian, data-type-policy=OVERRIDE, i-signal-type=PRIMITIVE, init-value=0, base-type=uint8, compu-method=c03_IMU_Force_Ang_Stat_ST3, data-constr=c03_IMU_Force_Ang_Stat_ST3, to IDC_M_FSI(timeout 0.3 s)  # Status spezifischer Kraftsignale fast / Status of specific force signals fast
    signal IMU_B_SpecForce_X_Fast_ST3: start 151, 16 bit, little-endian, data-type-policy=OVERRIDE, i-signal-type=PRIMITIVE, init-value=65535, base-type=uint16, invalid-value=65535, compu-method=c16_m_pro_s_sq_m50_50_0d002, data-constr=c16_m_pro_s_sq_m50_50_0d002, to IDC_M_FSI(timeout 0.3 s)  # Spezifische Kraft entlang der X-Achse fast / Specific force along X axis fast
    signal IMU_B_SpecForce_Y_Fast_ST3: start 167, 16 bit, little-endian, data-type-policy=OVERRIDE, i-signal-type=PRIMITIVE, init-value=65535, base-type=uint16, invalid-value=65535, compu-method=c16_m_pro_s_sq_m50_50_0d002, data-constr=c16_m_pro_s_sq_m50_50_0d002, to IDC_M_FSI(timeout 0.3 s)  # Spezifische Kraft entlang der Y-Achse fast / Specific force along Y axis fast
    signal IMU_B_SpecForce_Z_Fast_ST3: start 183, 16 bit, little-endian, data-type-policy=OVERRIDE, i-signal-type=PRIMITIVE, init-value=65535, base-type=uint16, invalid-value=65535, compu-method=c16_m_pro_s_sq_m50_50_0d002, data-constr=c16_m_pro_s_sq_m50_50_0d002, to IDC_M_FSI(timeout 0.3 s)  # Spezifische Kraft entlang der Z-Achse fast / Specific force along Z axis fast
    signal IMU_B_Stat_Fast_ST3: start 24, 3 bit, little-endian, data-type-policy=OVERRIDE, i-signal-type=PRIMITIVE, init-value=0, base-type=uint8, compu-method=c03_IMU_Stat_ST3, data-constr=c03_IMU_Stat_ST3, to IDC_M_FSI(timeout 0.3 s)  # Gesamtstatus der IMU fast / Overall IMU status fast
    signal IMU_B_Temp_Fast_ST3: start 39, 8 bit, little-endian, data-type-policy=OVERRIDE, i-signal-type=PRIMITIVE, init-value=255, base-type=uint8, invalid-value=255, compu-method=c08_deg_m50_160_1, data-constr=c08_deg_m50_160_1, to IDC_M_FSI(timeout 0.3 s)  # IMU-Temperatur fast / IMU Temperature fast
    signal IMU_B_TmStmp_NanoSec_Fast_ST3: start 199, 32 bit, little-endian, data-type-policy=OVERRIDE, i-signal-type=PRIMITIVE, init-value=0, base-type=uint32, compu {identical; unit ns}, data-constr=c32_ns_0_4294967295_1_noSNA, to IDC_M_FSI(timeout 0.3 s)  # IMU Zeitstempel, Ziffernbruchteil in Nanosekunden fast / IMU Time Stamp, fractional digits part in nanoseconds fast
    signal IMU_B_TmStmp_Sec_Fast_ST3: start 231, 32 bit, little-endian, data-type-policy=OVERRIDE, i-signal-type=PRIMITIVE, init-value=0, base-type=uint32, compu {identical; unit s}, data-constr=c32_s_0_4294967295_1_noSNA, to IDC_M_FSI(timeout 0.3 s)  # IMU Zeitstempel, ganze Sekunde Teil fast / IMU Time Stamp, whole seconds part fast
    signal IMU_B_TmSync_Stat_Fast_ST3: start 47, 8 bit, little-endian, data-type-policy=OVERRIDE, i-signal-type=PRIMITIVE, init-value=128, base-type=uint8, compu-method=c08_TmSync_Stat, to IDC_M_FSI(timeout 0.3 s)  # Status der globalen Zeitsynchronisierung fast / Global Time Sync Status fast
    signal SQC_IMU_B_Output_Fast_Pr5_ST3: start 16, 8 bit, little-endian, data-type-policy=OVERRIDE, i-signal-type=PRIMITIVE, init-value=0, base-type=uint8, compu {identical}, data-constr=c08_0_255_1_SNA_na, to IDC_M_FSI(timeout 0.3 s)  # Sequenzzähler / Sequence counter
    signal Rsrv01_IMU_B_Output_Fast_Pr5_ST3: start 263, 9 bit, little-endian, data-type-policy=OVERRIDE, i-signal-type=PRIMITIVE, init-value=511, base-type=uint16, invalid-value=511, range raw 0..511, to IDC_M_FSI  # Rsrv 01 IMU B Output Pr 5 ST3 fast
    signal Rsrv02_IMU_B_Output_Fast_Pr5_ST3: start 272, 8 bit, little-endian, data-type-policy=OVERRIDE, i-signal-type=PRIMITIVE, init-value=255, base-type=uint8, invalid-value=255, range raw 0..255, to IDC_M_FSI  # Rsrv 02 IMU B Output Pr 5 ST3 fast
    signal Rsrv03_IMU_B_Output_Fast_Pr5_ST3: start 280, 8 bit, little-endian, data-type-policy=OVERRIDE, i-signal-type=PRIMITIVE, init-value=255, base-type=uint8, invalid-value=255, range raw 0..255, to IDC_M_FSI  # Rsrv 03 IMU B Output Pr 5 ST3 fast
    signal Rsrv04_IMU_B_Output_Fast_Pr5_ST3: start 288, 8 bit, little-endian, data-type-policy=OVERRIDE, i-signal-type=PRIMITIVE, init-value=255, base-type=uint8, invalid-value=255, range raw 0..255, to IDC_M_FSI  # Rsrv 04 IMU B Output Pr 5 ST3 fast
    signal Rsrv05_IMU_B_Output_Fast_Pr5_ST3: start 296, 8 bit, little-endian, data-type-policy=OVERRIDE, i-signal-type=PRIMITIVE, init-value=255, base-type=uint8, invalid-value=255, range raw 0..255, to IDC_M_FSI  # Rsrv 05 IMU B Output Pr 5 ST3 fast
    signal Rsrv06_IMU_B_Output_Fast_Pr5_ST3: start 304, 16 bit, little-endian, data-type-policy=OVERRIDE, i-signal-type=PRIMITIVE, init-value=65535, base-type=uint16, invalid-value=65535, range raw 0..65535, to IDC_M_FSI  # Rsrv 06 IMU B Output Pr 5 ST3 fast
    signal Rsrv07_IMU_B_Output_Fast_Pr5_ST3: start 33, 3 bit, little-endian, data-type-policy=OVERRIDE, i-signal-type=PRIMITIVE, init-value=7, base-type=uint8, invalid-value=7, range raw 0..7, to IDC_M_FSI  # Rsrv 07 IMU B Output Pr 5 ST3 fast
    mapping IMU_B_Output_Fast_Pr5_ST3_dk96owji618h3fdh75ws5eyj3: i-signal-group=IMU_B_Output_Fast_Pr5_ST3_dk96owji618h3fdh75ws5eyj3, packing-byte-order=little-endian, transfer-property=TRIGGERED
  secured i pdu IMU_B_HAD_IMU_GW_Container_ST3_IMU_B_HAD_IMU_GW_Container_ST3_Ign_Stat_ST3_secured:
    length=8
    contained-i-pdu-props={collection-semantics=QUEUED, header-id-short-header=0x8000, timeout=0.01, trigger=NEVER}
    authentication-props=SECOC_AP_CMAC_AES_128_24
    freshness-props=SECOC_FP_10000_40_8_true
    payload=IMU_B_HAD_IMU_GW_Container_ST3_IMU_B_HAD_IMU_GW_Container_ST3_Ign_Stat_ST3_9o5nwdmsgjwwul51gt4t8a2ev
    secure-communication-props={authentication-retries=0, data-id=28212, freshness-value-id=1}
  secured i pdu IMU_B_HAD_IMU_GW_Container_ST3_IMU_B_HAD_IMU_GW_Container_ST3_PN14_Master_Stat1_ST3_secured:
    length=12
    contained-i-pdu-props={collection-semantics=QUEUED, header-id-short-header=0x398000, timeout=0.02, trigger=NEVER}
    authentication-props=SECOC_AP_CMAC_AES_128_24
    freshness-props=SECOC_FP_10000_40_8_true
    payload=IMU_B_HAD_IMU_GW_Container_ST3_IMU_B_HAD_IMU_GW_Container_ST3_PN14_Master_Stat1_ST3_55a6a0fnjme4imo147rnfut1q
    secure-communication-props={authentication-retries=0, data-id=57668, freshness-value-id=1}
  secured i pdu IDC_M_FSI_HAD_IMU_Container_ST3_IDC_M_FSI_HAD_IMU_Container_ST3_ADAS_HAD_Stat_IDC_M_FSI_ST3_secured:
    length=12
    contained-i-pdu-props={collection-semantics=QUEUED, header-id-short-header=0xa2fe03, timeout=0.01, trigger=NEVER}
    authentication-props=SECOC_AP_CMAC_AES_128_24
    freshness-props=SECOC_FP_10000_40_8_true
    payload=IDC_M_FSI_HAD_IMU_Container_ST3_IDC_M_FSI_HAD_IMU_Container_ST3_ADAS_HAD_Stat_IDC_M_FSI_ST3_3ft8f4vbg9cfnchzrcot530mq
    secure-communication-props={authentication-retries=0, data-id=28326, freshness-value-id=1}
package /Pdus/HAD_IMU/PKG_HAD_IMU/IDC_M_FSI_HAD_IMU_Container_ST3
  pdu IDC_M_FSI_HAD_IMU_Container_ST3_ADAS_HAD_Stat_IDC_M_FSI_ST3: length=8, transmission-mode-true-timing=cyclic-timing={time-offset=0.005, time-period=0.02}, unused-bit-pattern=255  # AdvancedDriverAssistanceSystems HAD Status IDC M FSI ST3 / AdvancedDriverAssistanceSystems HAD state IDC M FSI ST3
    signal ADAS_HAD_Ext_Stat_M_FSI_ST3: start 24, 3 bit, little-endian, data-type-policy=OVERRIDE, i-signal-type=PRIMITIVE, init-value=7, base-type=uint8, invalid-value=7, compu-method=c3_HAD_Ext_Stat_ST3, data-constr=c3_HAD_Ext_Stat_ST3, to IMU_B  # HAD Extended system state
    signal CRC_ADAS_HAD_Stat_IDC_M_FSI_Pr5_ST3: start 0, 16 bit, little-endian, data-type-policy=OVERRIDE, i-signal-type=PRIMITIVE, init-value=34676, base-type=uint16, data-constr=c16_CRC_woSNA, to IMU_B  # mCRC-Checksumme der Signal Gruppe gemäß AUTOSAR Profil 5 / CRC-checksum of signal group according to AUTOSAR Profile 5
    signal SQC_ADAS_HAD_Stat_IDC_M_FSI_Pr5_ST3: start 16, 8 bit, little-endian, data-type-policy=OVERRIDE, i-signal-type=PRIMITIVE, init-value=0, base-type=uint8, compu {identical}, data-constr=c08_0_255_1_SNA_na, to IMU_B  # Sequenzzähler / Sequence counter
    signal Rsrv1_ADAS_HAD_Stat_IDC_M_FSI_Pr5_ST3: start 27, 5 bit, little-endian, data-type-policy=OVERRIDE, i-signal-type=PRIMITIVE, init-value=31, base-type=uint8, invalid-value=31, range raw 0..31, to IMU_B  # Reserved for future purpose
    signal Rsrv2_ADAS_HAD_Stat_IDC_M_FSI_Pr5_ST3: start 32, 32 bit, little-endian, data-type-policy=OVERRIDE, i-signal-type=PRIMITIVE, init-value=4294967295, base-type=uint32, invalid-value=4294967295, range raw 0..4294967295, to IMU_B  # Reserved for future purpose
    mapping ADAS_HAD_Stat_IDC_M_FSI_Pr5_ST3_azb6uvmzdxiqsmnean8m9u52u: i-signal-group=ADAS_HAD_Stat_IDC_M_FSI_Pr5_ST3_azb6uvmzdxiqsmnean8m9u52u, packing-byte-order=little-endian, transfer-property=PENDING
package /Pdus/HAD_IMU/PKG_HAD_IMU/IMU_B_HAD_IMU_GW_Container_ST3
  pdu IMU_B_HAD_IMU_GW_Container_ST3_DI_OdoSpeedometer_ST3: length=8, contained-i-pdu-props={collection-semantics=QUEUED, header-id-short-header=0x320400, timeout=0.02, trigger=NEVER}, minimum-delay=0.1, transmission-mode-true-timing={cyclic-timing=time-period=1.0, event-controlled-timing=number-of-repetitions=0}, unused-bit-pattern=255  # Fahrerinformation Odometer und Tacho / DriverInformation Odometer and speedometer
    signal CRC_DI_Odo_Pr5_ST3: start 0, 16 bit, little-endian, data-type-policy=OVERRIDE, i-signal-type=PRIMITIVE, init-value=8633, base-type=uint16, data-constr=c16_CRC_woSNA, transfer-property=PENDING, to IDC_M_FSI  # CRC-Checksumme der Signal Gruppe gemäß AUTOSAR Profil 5 / CRC-checksum of signal group according to AUTOSAR Profile 5
    signal Odo_ST3: start 24, 24 bit, little-endian, data-type-policy=OVERRIDE, i-signal-type=PRIMITIVE, init-value=16777215, base-type=uint32, invalid-value=16777215, compu-method=c24_km_0_999999k9_0k1_Invld_SNA, data-constr=c24_km_0_999999k9_0k1_Invld_SNA, transfer-property=TRIGGERED-ON-CHANGE, to IDC_M_FSI  # Kilometerstand (für alle) / Odometer (for everyone)
    signal SQC_DI_Odo_Pr5_ST3: start 16, 8 bit, little-endian, data-type-policy=OVERRIDE, i-signal-type=PRIMITIVE, init-value=0, base-type=uint8, compu {identical}, data-constr=c08_0_255_1_SNA_na, transfer-property=PENDING, to IDC_M_FSI  # Sequenzzähler / Sequence counter
    signal VehSpd_Disp_ST3: start 48, 12 bit, little-endian, data-type-policy=OVERRIDE, i-signal-type=PRIMITIVE, init-value=4095, base-type=uint16, invalid-value=4095, compu-method=c12_km_p_h_0_409k4_0k1, data-constr=c12_km_p_h_0_409k4_0k1, transfer-property=TRIGGERED-ON-CHANGE  # NICHT MEHR VERWENDEN/LÄUFT zu MB.EA-L AUS!!! Bitte VehSpd_X_Disp_Rq_ST3 verwenden ------ Angezeigte Geschwindigkeit (ohne Zeigerdämpfung) / DONT USE/EOL is MB.EA-L!!! Use VehSpd_X_Disp_Rq_ST3 instead ------ Displayed vehicle speed (without attenuation)
    mapping DI_Odo_Pr5_ST3_e68xmtlkywxgxsdwekdjjhw3t: i-signal-group=DI_Odo_Pr5_ST3_e68xmtlkywxgxsdwekdjjhw3t, packing-byte-order=little-endian, transfer-property=TRIGGERED-ON-CHANGE, update-indication-bit-position=63
  pdu IMU_B_HAD_IMU_GW_Container_ST3_Ign_Stat_ST3: length=4, minimum-delay=0.02, transmission-mode-true-timing={cyclic-timing=time-period=0.1, event-controlled-timing=number-of-repetitions=0}, unused-bit-pattern=255  # Zuendungsstatus / Ignition state
    signal CRC_Ign_Stat_Pr5_ST3: start 0, 16 bit, little-endian, data-type-policy=OVERRIDE, i-signal-type=PRIMITIVE, init-value=20886, base-type=uint16, data-constr=c16_CRC_woSNA, transfer-property=PENDING, to IDC_M_FSI  # CRC-Checksumme der Signal Gruppe gemäß AUTOSAR Profil 5 / CRC-checksum of signal group according to AUTOSAR Profile 5
    signal ISw_Stat_ST3: start 24, 3 bit, little-endian, data-type-policy=OVERRIDE, i-signal-type=PRIMITIVE, init-value=7, base-type=uint8, invalid-value=7, compu-method=c03_ISw_Stat, data-constr=c03_ISw_Stat, transfer-property=TRIGGERED-ON-CHANGE, to IDC_M_FSI  # Klemmenstatus / Ignition switch state
    signal KG_StartSw_Psd_ST3: start 31, 1 bit, little-endian, data-type-policy=OVERRIDE, i-signal-type=PRIMITIVE, init-value=0, base-type=boolean, transfer-property=TRIGGERED-ON-CHANGE, to IDC_M_FSI  # Keyless Go Starttaster betätigt / Keyless Go start switch pressed
    signal SQC_Ign_Stat_Pr5_ST3: start 16, 8 bit, little-endian, data-type-policy=OVERRIDE, i-signal-type=PRIMITIVE, init-value=0, base-type=uint8, compu {identical}, data-constr=c08_0_255_1_SNA_na, transfer-property=PENDING, to IDC_M_FSI  # Sequenzzähler / Sequence counter
    signal Veh_Op_Mode_ST3: start 27, 4 bit, little-endian, data-type-policy=OVERRIDE, i-signal-type=PRIMITIVE, init-value=0, base-type=uint8, invalid-value=15, compu-method=c04_VehOpMode, data-constr=c04_VehOpMode, transfer-property=TRIGGERED-ON-CHANGE, to IDC_M_FSI  # Fahrzeug Betriebsmodus / Operating Mode Vehicle
    mapping Ign_Stat_Pr5_ST3_csgs1dv6drms80o1i9p49677w: i-signal-group=Ign_Stat_Pr5_ST3_csgs1dv6drms80o1i9p49677w, packing-byte-order=little-endian, transfer-property=TRIGGERED-ON-CHANGE
  pdu IMU_B_HAD_IMU_GW_Container_ST3_PN14_Master_Stat1_ST3: length=8, transmission-mode-true-timing=cyclic-timing=time-period=0.2, unused-bit-pattern=255  # Status 12V Bordnetz Master / Powernetwork 12V master state
    signal PN14_DDP_Sw2_Stat_ST3: start 57, 3 bit, little-endian, data-type-policy=OVERRIDE, i-signal-type=PRIMITIVE, init-value=7, base-type=uint8, invalid-value=7, compu-method=c03_PN14_TDP_Sw_Stat, data-constr=c03_PN14_TDP_Sw_Stat, transfer-property=PENDING  # Schalterstatus DDP Switch 2 (Always On Switch) / State of DDP Switch2 (Always On Switch)
    signal PN14_DDP_Sw_Stat_ST3: start 2, 3 bit, little-endian, data-type-policy=OVERRIDE, i-signal-type=PRIMITIVE, init-value=0, base-type=uint8, invalid-value=7, compu-method=c03_PN14_TDP_Sw_Stat, data-constr=c03_PN14_TDP_Sw_Stat, transfer-property=PENDING, to IDC_M_FSI  # Schalterstatus Tiefentladeschutz / Deep discharge protection switch state
    signal PN14_ExtBat_Charge_Actv_ST3: start 55, 2 bit, little-endian, data-type-policy=OVERRIDE, i-signal-type=PRIMITIVE, init-value=3, base-type=uint8, invalid-value=3, compu-method=c02_Ndef_False_True_ST3, data-constr=c02_Ndef_False_True_ST3, transfer-property=PENDING  # Externe Batterieladung erkannt / external barttery charging detected
    signal PN14_PNSec_RechargeEnable_ST3: start 53, 2 bit, little-endian, data-type-policy=OVERRIDE, i-signal-type=PRIMITIVE, init-value=3, base-type=uint8, invalid-value=3, compu-method=c02_Ndef_False_True_ST3, data-constr=c02_Ndef_False_True_ST3, transfer-property=PENDING  # Freigabe zum Nachladen der Sekundärbatterie / Enable for Recharge Secondary-Batterie
    signal PN14_ProdMd_BatStat_ST3: start 8, 7 bit, little-endian, data-type-policy=OVERRIDE, i-signal-type=PRIMITIVE, init-value=127, base-type=uint8, invalid-value=127, compu-method=c07_per_0to100_1_SNA, data-constr=c07_per_0to100_1_SNA, transfer-property=PENDING  # Der aktuelle Status der 12V Versorgungsbatterie während Produktions-Mode. / Actual 12V battery state during production mode
    signal PN14_ProdMd_Stat_ST3: start 5, 3 bit, little-endian, data-type-policy=OVERRIDE, i-signal-type=PRIMITIVE, init-value=7, base-type=uint8, invalid-value=7, compu-method=c03_PN14_ProdMd_Stat_ST3, data-constr=c03_PN14_ProdMd_Stat_ST3, transfer-property=PENDING  # Status des Bordnetz Produktionsmodus / Powernet production mode state
    signal PN14_SupBat_Curr_ST3: start 32, 13 bit, little-endian, data-type-policy=OVERRIDE, i-signal-type=PRIMITIVE, init-value=8191, base-type=uint16, invalid-value=8191, compu-method=c13_A_m409k6_409k4_0k1, data-constr=c13_A_m409k6_409k4_0k1, transfer-property=PENDING  # Versorgungsbatterie Iststrom / Supply battery current
    signal PN14_SupBat_Stat_ST3: start 15, 7 bit, little-endian, data-type-policy=OVERRIDE, i-signal-type=PRIMITIVE, init-value=127, base-type=uint8, invalid-value=127, compu-method=c07_0_111_1_SNA, data-constr=c07_0_111_1_SNA, transfer-property=PENDING  # Status Versorgungsbatterie / Supply battery state
    signal PN14_SupBat_Temp_ST3: start 45, 8 bit, little-endian, data-type-policy=OVERRIDE, i-signal-type=PRIMITIVE, init-value=255, base-type=uint8, invalid-value=255, compu-method=c08_degC_m40_85_0k5, data-constr=c08_degC_m40_85_0k5, transfer-property=PENDING  # Temperatur Versorgungsbatterie / Supply battery temperature
    signal PN14_SupBat_Volt_ST3: start 22, 10 bit, little-endian, data-type-policy=OVERRIDE, i-signal-type=PRIMITIVE, init-value=1023, base-type=uint16, invalid-value=1023, compu-method=c10_V_0_25k55_0k025, data-constr=c10_V_0_25k55_0k025, transfer-property=PENDING  # Versorgungsbatterie Istspannung / Supply battery voltage
    signal PN14_TransMd_Stat_ST3: start 0, 2 bit, little-endian, data-type-policy=OVERRIDE, i-signal-type=PRIMITIVE, init-value=3, base-type=uint8, invalid-value=3, compu-method=c02_TransMd_Stat, data-constr=c02_TransMd_Stat, transfer-property=PENDING  # Bordnetz Status Transportmodus / Powernet transport mode status
  pdu IMU_B_HAD_IMU_GW_Container_ST3_VSS_TP_Auth_ST3: length=8, contained-i-pdu-props={collection-semantics=QUEUED, header-id-short-header=0x410001, timeout=0.01, trigger=NEVER}, minimum-delay=0.02, transmission-mode-true-timing=event-controlled-timing=number-of-repetitions=0, unused-bit-pattern=255  # VSS-Transportprotokoll für Authentifizierung / Vehicle Security System Transport Protocol for authentication broadcast
    signal VSS_TP_Auth_0_ST3: start 0, 8 bit, little-endian, data-type-policy=OVERRIDE, i-signal-type=PRIMITIVE, init-value=255, base-type=uint8, data-constr=c08_UInt_SNA_na, to IDC_M_FSI  # VSS-Transportprotokoll für Authentifizierung, Byte 0 / Vehicle Security System Transport Protocol for authentication broadcast, Byte 0
    signal VSS_TP_Auth_1_ST3: start 8, 8 bit, little-endian, data-type-policy=OVERRIDE, i-signal-type=PRIMITIVE, init-value=255, base-type=uint8, data-constr=c08_UInt_SNA_na, to IDC_M_FSI  # VSS-Transportprotokoll für Authentifizierung, Byte 1 / Vehicle Security System Transport Protocol for authentication broadcast, Byte 1
    signal VSS_TP_Auth_2_ST3: start 16, 8 bit, little-endian, data-type-policy=OVERRIDE, i-signal-type=PRIMITIVE, init-value=255, base-type=uint8, data-constr=c08_UInt_SNA_na, to IDC_M_FSI  # VSS-Transportprotokoll für Authentifizierung, Byte 2 / Vehicle Security System Transport Protocol for authentication broadcast, Byte 2
    signal VSS_TP_Auth_3_ST3: start 24, 8 bit, little-endian, data-type-policy=OVERRIDE, i-signal-type=PRIMITIVE, init-value=255, base-type=uint8, data-constr=c08_UInt_SNA_na, to IDC_M_FSI  # VSS-Transportprotokoll für Authentifizierung, Byte 3 / Vehicle Security System Transport Protocol for authentication broadcast, Byte 3
    signal VSS_TP_Auth_4_ST3: start 32, 8 bit, little-endian, data-type-policy=OVERRIDE, i-signal-type=PRIMITIVE, init-value=255, base-type=uint8, data-constr=c08_UInt_SNA_na, to IDC_M_FSI  # VSS-Transportprotokoll für Authentifizierung, Byte 4 / Vehicle Security System Transport Protocol for authentication broadcast, Byte 4
    signal VSS_TP_Auth_5_ST3: start 40, 8 bit, little-endian, data-type-policy=OVERRIDE, i-signal-type=PRIMITIVE, init-value=255, base-type=uint8, data-constr=c08_UInt_SNA_na, to IDC_M_FSI  # VSS-Transportprotokoll für Authentifizierung, Byte 5 / Vehicle Security System Transport Protocol for authentication broadcast, Byte 5
    signal VSS_TP_Auth_6_ST3: start 48, 8 bit, little-endian, data-type-policy=OVERRIDE, i-signal-type=PRIMITIVE, init-value=255, base-type=uint8, data-constr=c08_UInt_SNA_na, to IDC_M_FSI  # VSS-Transportprotokoll für Authentifizierung, Byte 6 / Vehicle Security System Transport Protocol for authentication broadcast, Byte 6
    signal VSS_TP_Auth_7_ST3: start 56, 8 bit, little-endian, data-type-policy=OVERRIDE, i-signal-type=PRIMITIVE, init-value=255, base-type=uint8, data-constr=c08_UInt_SNA_na, to IDC_M_FSI  # VSS-Transportprotokoll für Authentifizierung, Byte 7 / Vehicle Security System Transport Protocol for authentication broadcast, Byte 7
    mapping VSS_TP_Auth_ST3_6j4id7sghlvlbroli4wjozjik: i-signal-group=VSS_TP_Auth_ST3_6j4id7sghlvlbroli4wjozjik, packing-byte-order=little-endian, transfer-property=TRIGGERED
  pdu IMU_B_HAD_IMU_GW_Container_ST3_VSS_TP_RealTmOffset_ST3: length=8, contained-i-pdu-props={collection-semantics=QUEUED, header-id-short-header=0x410002, timeout=0.01, trigger=NEVER}, minimum-delay=0.02, transmission-mode-true-timing=event-controlled-timing=number-of-repetitions=0, unused-bit-pattern=255  # VSS-Transportprotokoll für Echtzeit-Offset / Vehicle Security System Transport Protocol for real time offset broadcast
    signal VSS_TP_RealTmOffset_0_ST3: start 0, 8 bit, little-endian, data-type-policy=OVERRIDE, i-signal-type=PRIMITIVE, init-value=255, base-type=uint8, data-constr=c08_UInt_SNA_na, to IDC_M_FSI  # VSS-Transportprotokoll für Echtzeit-Offset, Byte 0 / Vehicle Security System Transport Protocol for real time offset broadcast, Byte 0
    signal VSS_TP_RealTmOffset_1_ST3: start 8, 8 bit, little-endian, data-type-policy=OVERRIDE, i-signal-type=PRIMITIVE, init-value=255, base-type=uint8, data-constr=c08_UInt_SNA_na, to IDC_M_FSI  # VSS-Transportprotokoll für Echtzeit-Offset, Byte 1 / Vehicle Security System Transport Protocol for real time offset broadcast, Byte 1
    signal VSS_TP_RealTmOffset_2_ST3: start 16, 8 bit, little-endian, data-type-policy=OVERRIDE, i-signal-type=PRIMITIVE, init-value=255, base-type=uint8, data-constr=c08_UInt_SNA_na, to IDC_M_FSI  # VSS-Transportprotokoll für Echtzeit-Offset, Byte 2 / Vehicle Security System Transport Protocol for real time offset broadcast, Byte 2
    signal VSS_TP_RealTmOffset_3_ST3: start 24, 8 bit, little-endian, data-type-policy=OVERRIDE, i-signal-type=PRIMITIVE, init-value=255, base-type=uint8, data-constr=c08_UInt_SNA_na, to IDC_M_FSI  # VSS-Transportprotokoll für Echtzeit-Offset, Byte 3 / Vehicle Security System Transport Protocol for real time offset broadcast, Byte 3
    signal VSS_TP_RealTmOffset_4_ST3: start 32, 8 bit, little-endian, data-type-policy=OVERRIDE, i-signal-type=PRIMITIVE, init-value=255, base-type=uint8, data-constr=c08_UInt_SNA_na, to IDC_M_FSI  # VSS-Transportprotokoll für Echtzeit-Offset, Byte 4 / Vehicle Security System Transport Protocol for real time offset broadcast, Byte 4
    signal VSS_TP_RealTmOffset_5_ST3: start 40, 8 bit, little-endian, data-type-policy=OVERRIDE, i-signal-type=PRIMITIVE, init-value=255, base-type=uint8, data-constr=c08_UInt_SNA_na, to IDC_M_FSI  # VSS-Transportprotokoll für Echtzeit-Offset, Byte 5 / Vehicle Security System Transport Protocol for real time offset broadcast, Byte 5
    signal VSS_TP_RealTmOffset_6_ST3: start 48, 8 bit, little-endian, data-type-policy=OVERRIDE, i-signal-type=PRIMITIVE, init-value=255, base-type=uint8, data-constr=c08_UInt_SNA_na, to IDC_M_FSI  # VSS-Transportprotokoll für Echtzeit-Offset, Byte 6 / Vehicle Security System Transport Protocol for real time offset broadcast, Byte 6
    signal VSS_TP_RealTmOffset_7_ST3: start 56, 8 bit, little-endian, data-type-policy=OVERRIDE, i-signal-type=PRIMITIVE, init-value=255, base-type=uint8, data-constr=c08_UInt_SNA_na, to IDC_M_FSI  # VSS-Transportprotokoll für Echtzeit-Offset, Byte 7 / Vehicle Security System Transport Protocol for real time offset broadcast, Byte 7
    mapping VSS_TP_RealTmOffset_ST3_1t7vc44gftc0wv35k5kgc2in9: i-signal-group=VSS_TP_RealTmOffset_ST3_1t7vc44gftc0wv35k5kgc2in9, packing-byte-order=little-endian, transfer-property=TRIGGERED
  pdu IMU_B_HAD_IMU_GW_Container_ST3_VSS_TP_SecTickCount_Lvl1_ST3: length=8, contained-i-pdu-props={collection-semantics=QUEUED, header-id-short-header=0x410004, timeout=0.01, trigger=NEVER}, minimum-delay=0.02, transmission-mode-true-timing=event-controlled-timing=number-of-repetitions=0, unused-bit-pattern=255  # VSS-Transportprotokoll für sichere Zeit Stufe 1 / Vehicle Security System Transport Protocol for secure tick count level #1
    signal VSS_TP_SecTickCount_Lvl1_0_ST3: start 0, 8 bit, little-endian, data-type-policy=OVERRIDE, i-signal-type=PRIMITIVE, init-value=255, base-type=uint8, data-constr=c08_UInt_SNA_na, to IDC_M_FSI  # VSS-Transportprotokoll für sichere Zeit Stufe 1, Byte 0 / Vehicle Security System Transport Protocol for secure tick count level #1, Byte 0
    signal VSS_TP_SecTickCount_Lvl1_1_ST3: start 8, 8 bit, little-endian, data-type-policy=OVERRIDE, i-signal-type=PRIMITIVE, init-value=255, base-type=uint8, data-constr=c08_UInt_SNA_na, to IDC_M_FSI  # VSS-Transportprotokoll für sichere Zeit Stufe 1, Byte 1 / Vehicle Security System Transport Protocol for secure tick count level #1, Byte 1
    signal VSS_TP_SecTickCount_Lvl1_2_ST3: start 16, 8 bit, little-endian, data-type-policy=OVERRIDE, i-signal-type=PRIMITIVE, init-value=255, base-type=uint8, data-constr=c08_UInt_SNA_na, to IDC_M_FSI  # VSS-Transportprotokoll für sichere Zeit Stufe 1, Byte 2 / Vehicle Security System Transport Protocol for secure tick count level #1, Byte 2
    signal VSS_TP_SecTickCount_Lvl1_3_ST3: start 24, 8 bit, little-endian, data-type-policy=OVERRIDE, i-signal-type=PRIMITIVE, init-value=255, base-type=uint8, data-constr=c08_UInt_SNA_na, to IDC_M_FSI  # VSS-Transportprotokoll für sichere Zeit Stufe 1, Byte 3 / Vehicle Security System Transport Protocol for secure tick count level #1, Byte 3
    signal VSS_TP_SecTickCount_Lvl1_4_ST3: start 32, 8 bit, little-endian, data-type-policy=OVERRIDE, i-signal-type=PRIMITIVE, init-value=255, base-type=uint8, data-constr=c08_UInt_SNA_na, to IDC_M_FSI  # VSS-Transportprotokoll für sichere Zeit Stufe 1, Byte 4 / Vehicle Security System Transport Protocol for secure tick count level #1, Byte 4
    signal VSS_TP_SecTickCount_Lvl1_5_ST3: start 40, 8 bit, little-endian, data-type-policy=OVERRIDE, i-signal-type=PRIMITIVE, init-value=255, base-type=uint8, data-constr=c08_UInt_SNA_na, to IDC_M_FSI  # VSS-Transportprotokoll für sichere Zeit Stufe 1, Byte 5 / Vehicle Security System Transport Protocol for secure tick count level #1, Byte 5
    signal VSS_TP_SecTickCount_Lvl1_6_ST3: start 48, 8 bit, little-endian, data-type-policy=OVERRIDE, i-signal-type=PRIMITIVE, init-value=255, base-type=uint8, data-constr=c08_UInt_SNA_na, to IDC_M_FSI  # VSS-Transportprotokoll für sichere Zeit Stufe 1, Byte 6 / Vehicle Security System Transport Protocol for secure tick count level #1, Byte 6
    signal VSS_TP_SecTickCount_Lvl1_7_ST3: start 56, 8 bit, little-endian, data-type-policy=OVERRIDE, i-signal-type=PRIMITIVE, init-value=255, base-type=uint8, data-constr=c08_UInt_SNA_na, to IDC_M_FSI  # VSS-Transportprotokoll für sichere Zeit Stufe 1, Byte 7 / Vehicle Security System Transport Protocol for secure tick count level #1, Byte 7
    mapping VSS_TP_SecTickCount_Lvl1_ST3_mzmfdqtqz5kvv1kfpvg0kql3: i-signal-group=VSS_TP_SecTickCount_Lvl1_ST3_mzmfdqtqz5kvv1kfpvg0kql3, packing-byte-order=little-endian, transfer-property=TRIGGERED
  pdu IMU_B_HAD_IMU_GW_Container_ST3_VSS_TP_SharedSecret_ST3: length=8, contained-i-pdu-props={collection-semantics=QUEUED, header-id-short-header=0x410003, timeout=0.01, trigger=NEVER}, minimum-delay=0.02, transmission-mode-true-timing=event-controlled-timing=number-of-repetitions=0, unused-bit-pattern=255  # VSS-Transportprotokoll für gemeinsames Geheimnis / Vehicle Security System Transport Protocol for shared secret broadcast
    signal VSS_TP_SharedSecret_0_ST3: start 0, 8 bit, little-endian, data-type-policy=OVERRIDE, i-signal-type=PRIMITIVE, init-value=255, base-type=uint8, data-constr=c08_UInt_SNA_na, to IDC_M_FSI  # VSS-Transportprotokoll für gemeinsames Geheimnis, Byte 0 / Vehicle Security System Transport Protocol for shared secret broadcast, Byte 0
    signal VSS_TP_SharedSecret_1_ST3: start 8, 8 bit, little-endian, data-type-policy=OVERRIDE, i-signal-type=PRIMITIVE, init-value=255, base-type=uint8, data-constr=c08_UInt_SNA_na, to IDC_M_FSI  # VSS-Transportprotokoll für gemeinsames Geheimnis, Byte 1 / Vehicle Security System Transport Protocol for shared secret broadcast, Byte 1
    signal VSS_TP_SharedSecret_2_ST3: start 16, 8 bit, little-endian, data-type-policy=OVERRIDE, i-signal-type=PRIMITIVE, init-value=255, base-type=uint8, data-constr=c08_UInt_SNA_na, to IDC_M_FSI  # VSS-Transportprotokoll für gemeinsames Geheimnis, Byte 2 / Vehicle Security System Transport Protocol for shared secret broadcast, Byte 2
    signal VSS_TP_SharedSecret_3_ST3: start 24, 8 bit, little-endian, data-type-policy=OVERRIDE, i-signal-type=PRIMITIVE, init-value=255, base-type=uint8, data-constr=c08_UInt_SNA_na, to IDC_M_FSI  # VSS-Transportprotokoll für gemeinsames Geheimnis, Byte 3 / Vehicle Security System Transport Protocol for shared secret broadcast, Byte 3
    signal VSS_TP_SharedSecret_4_ST3: start 32, 8 bit, little-endian, data-type-policy=OVERRIDE, i-signal-type=PRIMITIVE, init-value=255, base-type=uint8, data-constr=c08_UInt_SNA_na, to IDC_M_FSI  # VSS-Transportprotokoll für gemeinsames Geheimnis, Byte 4 / Vehicle Security System Transport Protocol for shared secret broadcast, Byte 4
    signal VSS_TP_SharedSecret_5_ST3: start 40, 8 bit, little-endian, data-type-policy=OVERRIDE, i-signal-type=PRIMITIVE, init-value=255, base-type=uint8, data-constr=c08_UInt_SNA_na, to IDC_M_FSI  # VSS-Transportprotokoll für gemeinsames Geheimnis, Byte 5 / Vehicle Security System Transport Protocol for shared secret broadcast, Byte 5
    signal VSS_TP_SharedSecret_6_ST3: start 48, 8 bit, little-endian, data-type-policy=OVERRIDE, i-signal-type=PRIMITIVE, init-value=255, base-type=uint8, data-constr=c08_UInt_SNA_na, to IDC_M_FSI  # VSS-Transportprotokoll für gemeinsames Geheimnis, Byte 6 / Vehicle Security System Transport Protocol for shared secret broadcast, Byte 6
    signal VSS_TP_SharedSecret_7_ST3: start 56, 8 bit, little-endian, data-type-policy=OVERRIDE, i-signal-type=PRIMITIVE, init-value=255, base-type=uint8, data-constr=c08_UInt_SNA_na, to IDC_M_FSI  # VSS-Transportprotokoll für gemeinsames Geheimnis, Byte 7 / Vehicle Security System Transport Protocol for shared secret broadcast, Byte 7
    mapping VSS_TP_SharedSecret_ST3_8pj4t8t4rm3tw3pk5hj7vonti: i-signal-group=VSS_TP_SharedSecret_ST3_8pj4t8t4rm3tw3pk5hj7vonti, packing-byte-order=little-endian, transfer-property=TRIGGERED
  pdu IMU_B_HAD_IMU_GW_Container_ST3_VSS_TP_VIN_ST3: length=8, contained-i-pdu-props={collection-semantics=QUEUED, header-id-short-header=0x410000, timeout=0.01, trigger=NEVER}, minimum-delay=0.02, transmission-mode-true-timing=event-controlled-timing=number-of-repetitions=0, unused-bit-pattern=255  # VSS-Transportprotokoll für Fahrzeugidentifikationsnummer / Vehicle Security System Transport Protocol for Vehicle Identification Number
    signal VSS_TP_VIN_0_ST3: start 0, 8 bit, little-endian, data-type-policy=OVERRIDE, i-signal-type=PRIMITIVE, init-value=63, base-type=uint8, data-constr=c08_UInt_SNA_na, to IDC_M_FSI  # VSS-Transportprotokoll für Fahrzeugidentifikationsnummer, Byte 0 / Vehicle Security System Transport Protocol for Vehicle Identification Number, Byte 0
    signal VSS_TP_VIN_1_ST3: start 8, 8 bit, little-endian, data-type-policy=OVERRIDE, i-signal-type=PRIMITIVE, init-value=63, base-type=uint8, data-constr=c08_UInt_SNA_na, to IDC_M_FSI  # VSS-Transportprotokoll für Fahrzeugidentifikationsnummer, Byte 1 / Vehicle Security System Transport Protocol for Vehicle Identification Number, Byte 1
    signal VSS_TP_VIN_2_ST3: start 16, 8 bit, little-endian, data-type-policy=OVERRIDE, i-signal-type=PRIMITIVE, init-value=63, base-type=uint8, data-constr=c08_UInt_SNA_na, to IDC_M_FSI  # VSS-Transportprotokoll für Fahrzeugidentifikationsnummer, Byte 2 / Vehicle Security System Transport Protocol for Vehicle Identification Number, Byte 2
    signal VSS_TP_VIN_3_ST3: start 24, 8 bit, little-endian, data-type-policy=OVERRIDE, i-signal-type=PRIMITIVE, init-value=63, base-type=uint8, data-constr=c08_UInt_SNA_na, to IDC_M_FSI  # VSS-Transportprotokoll für Fahrzeugidentifikationsnummer, Byte 3 / Vehicle Security System Transport Protocol for Vehicle Identification Number, Byte 3
    signal VSS_TP_VIN_4_ST3: start 32, 8 bit, little-endian, data-type-policy=OVERRIDE, i-signal-type=PRIMITIVE, init-value=63, base-type=uint8, data-constr=c08_UInt_SNA_na, to IDC_M_FSI  # VSS-Transportprotokoll für Fahrzeugidentifikationsnummer, Byte 4 / Vehicle Security System Transport Protocol for Vehicle Identification Number, Byte 4
    signal VSS_TP_VIN_5_ST3: start 40, 8 bit, little-endian, data-type-policy=OVERRIDE, i-signal-type=PRIMITIVE, init-value=63, base-type=uint8, data-constr=c08_UInt_SNA_na, to IDC_M_FSI  # VSS-Transportprotokoll für Fahrzeugidentifikationsnummer, Byte 5 / Vehicle Security System Transport Protocol for Vehicle Identification Number, Byte 5
    signal VSS_TP_VIN_6_ST3: start 48, 8 bit, little-endian, data-type-policy=OVERRIDE, i-signal-type=PRIMITIVE, init-value=63, base-type=uint8, data-constr=c08_UInt_SNA_na, to IDC_M_FSI  # VSS-Transportprotokoll für Fahrzeugidentifikationsnummer, Byte 6 / Vehicle Security System Transport Protocol for Vehicle Identification Number, Byte 6
    signal VSS_TP_VIN_7_ST3: start 56, 8 bit, little-endian, data-type-policy=OVERRIDE, i-signal-type=PRIMITIVE, init-value=63, base-type=uint8, data-constr=c08_UInt_SNA_na, to IDC_M_FSI  # VSS-Transportprotokoll für Fahrzeugidentifikationsnummer, Byte 7 / Vehicle Security System Transport Protocol for Vehicle Identification Number, Byte 7
    mapping VSS_TP_VIN_ST3_bz1xsv84cxzl09j028gn39p69: i-signal-group=VSS_TP_VIN_ST3_bz1xsv84cxzl09j028gn39p69, packing-byte-order=little-endian, transfer-property=TRIGGERED
package /DataTransformations
  data transformation set DATATRANSFORMATION_SET
    4 x data transformation, all with execute-despite-data-unavailability=true:
      BaseTrans_Profile_5_8: transformer-chain=[ComBasedTransformer8, E2E_Profile_5]  # Base Transformer Base Profile 5
      BaseTrans_Profile_5_40: transformer-chain=[ComBasedTransformer40, E2E_Profile_5]  # Base Transformer Base Profile 5
      BaseTrans_Profile_5_6: transformer-chain=[ComBasedTransformer6, E2E_Profile_5]  # Base Transformer Base Profile 5
      BaseTrans_Profile_5_4: transformer-chain=[ComBasedTransformer4, E2E_Profile_5]  # Base Transformer Base Profile 5
    5 x transformation technology:
      ComBasedTransformer8: buffer-properties={buffer-computation=compu-rational-coeffs={compu-numerator=8, compu-denominator=1}, header-length=0, in-place=false}, protocol=COMBased, transformer-class=SERIALIZER, version=1
      E2E_Profile_5:  # E2E Profile 5
        buffer-properties={header-length=0, in-place=true}
        has-internal-state=true
        needs-original-data=false
        protocol=E2E
        end-to-end-transformation-description{max-delta-counter=3, max-error-state-init=0, max-error-state-invalid=0, max-error-state-valid=0, min-ok-state-init=1, min-ok-state-invalid=1, min-ok-state-valid=1, offset=0, profile-name=PROFILE_05, upper-header-bits-to-shift=0, window-size-init=10, window-size-invalid=10, window-size-valid=10}
        transformer-class=SAFETY
        version=1.0.0
      ComBasedTransformer40: buffer-properties={buffer-computation=compu-rational-coeffs={compu-numerator=40, compu-denominator=1}, header-length=0, in-place=false}, protocol=COMBased, transformer-class=SERIALIZER, version=1
      ComBasedTransformer6: buffer-properties={buffer-computation=compu-rational-coeffs={compu-numerator=6, compu-denominator=1}, header-length=0, in-place=false}, protocol=COMBased, transformer-class=SERIALIZER, version=1
      ComBasedTransformer4: buffer-properties={buffer-computation=compu-rational-coeffs={compu-numerator=4, compu-denominator=1}, header-length=0, in-place=false}, protocol=COMBased, transformer-class=SERIALIZER, version=1
package /ISignalGroups/HAD_IMU/PKG_HAD_IMU/IDC_M_FSI_HAD_IMU_Container_ST3_ADAS_HAD_Stat_IDC_M_FSI_ST3
  i signal group ADAS_HAD_Stat_IDC_M_FSI_Pr5_ST3_azb6uvmzdxiqsmnean8m9u52u:  # Zustand hochautomatisiertes Fahren IDC Master (degraded) / Highly automated driving state Master (degraded)
    com-based-signal-group-transformations=BaseTrans_Profile_5_8
    i-signal=[ADAS_HAD_Ext_Stat_M_FSI_ST3, CRC_ADAS_HAD_Stat_IDC_M_FSI_Pr5_ST3, Rsrv1_ADAS_HAD_Stat_IDC_M_FSI_Pr5_ST3, Rsrv2_ADAS_HAD_Stat_IDC_M_FSI_Pr5_ST3, SQC_ADAS_HAD_Stat_IDC_M_FSI_Pr5_ST3]
    system-signal-group=ADAS_HAD_Stat_IDC_M_FSI_Pr5_ST3_azb6uvmzdxiqsmnean8m9u52u
    end-to-end-transformation-i-signal-props{transformer=E2E_Profile_5, data-ids=1083, data-length=64}
package /ISignalGroups/HAD_IMU/PKG_HAD_IMU/IMU_A_Output_Fast_ST3
  i signal group IMU_A_Output_Fast_Pr5_ST3_5ym0lyqjosyobfhfksta75zc4:  # IMU A Output Pr 5 ST3 (degraded)
    com-based-signal-group-transformations=BaseTrans_Profile_5_40
    i-signal=[CRC_IMU_A_Output_Fast_Pr5_ST3, IMU_A_AngAcc_Stat_Fast_ST3, IMU_A_AngAcc_X_Fast_ST3, IMU_A_AngAcc_Y_Fast_ST3, IMU_A_AngAcc_Z_Fast_ST3, IMU_A_AngRate_X_Fast_ST3, IMU_A_AngRate_Y_Fast_ST3, IMU_A_AngRate_Z_Fast_ST3, IMU_A_AngRates_Stat_Fast_ST3, IMU_A_SpecForce_Stat_Fast_ST3, IMU_A_SpecForce_X_Fast_ST3, IMU_A_SpecForce_Y_Fast_ST3, IMU_A_SpecForce_Z_Fast_ST3, IMU_A_Stat_Fast_ST3, IMU_A_Temp_Fast_ST3, IMU_A_TmStmp_NanoSec_Fast_ST3, IMU_A_TmStmp_Sec_Fast_ST3, IMU_A_TmSync_Stat_Fast_ST3, Rsrv01_IMU_A_Output_Fast_Pr5_ST3, Rsrv02_IMU_A_Output_Fast_Pr5_ST3, Rsrv03_IMU_A_Output_Fast_Pr5_ST3, Rsrv04_IMU_A_Output_Fast_Pr5_ST3, Rsrv05_IMU_A_Output_Fast_Pr5_ST3, Rsrv06_IMU_A_Output_Fast_Pr5_ST3, Rsrv07_IMU_A_Output_Fast_Pr5_ST3, SQC_IMU_A_Output_Fast_Pr5_ST3]
    system-signal-group=IMU_A_Output_Fast_Pr5_ST3_5ym0lyqjosyobfhfksta75zc4
    end-to-end-transformation-i-signal-props{transformer=E2E_Profile_5, data-ids=931, data-length=320}
package /ISignalGroups/HAD_IMU/PKG_HAD_IMU/IMU_B_HAD_IMU_GW_Container_ST3_DI_OdoSpeedometer_ST3
  i signal group DI_Odo_Pr5_ST3_e68xmtlkywxgxsdwekdjjhw3t: com-based-signal-group-transformations=BaseTrans_Profile_5_6, i-signal=[CRC_DI_Odo_Pr5_ST3, Odo_ST3, SQC_DI_Odo_Pr5_ST3], system-signal-group=DI_Odo_Pr5_ST3_e68xmtlkywxgxsdwekdjjhw3t, end-to-end-transformation-i-signal-props{transformer=E2E_Profile_5, data-ids=186, data-length=48}  # DriverInformation Odometer (degraded)
package /ISignalGroups/HAD_IMU/PKG_HAD_IMU/IMU_B_HAD_IMU_GW_Container_ST3_Ign_Stat_ST3
  i signal group Ign_Stat_Pr5_ST3_csgs1dv6drms80o1i9p49677w: com-based-signal-group-transformations=BaseTrans_Profile_5_4, i-signal=[CRC_Ign_Stat_Pr5_ST3, ISw_Stat_ST3, KG_StartSw_Psd_ST3, SQC_Ign_Stat_Pr5_ST3, Veh_Op_Mode_ST3], system-signal-group=Ign_Stat_Pr5_ST3_csgs1dv6drms80o1i9p49677w, end-to-end-transformation-i-signal-props{transformer=E2E_Profile_5, data-ids=51, data-length=32}  # Zuendungsstatus (degraded) / Ignition state (degraded)
package /ISignalGroups/HAD_IMU/PKG_HAD_IMU/IMU_B_HAD_IMU_GW_Container_ST3_VSS_TP_Auth_ST3
  i signal group VSS_TP_Auth_ST3_6j4id7sghlvlbroli4wjozjik: i-signal=[VSS_TP_Auth_0_ST3, VSS_TP_Auth_1_ST3, VSS_TP_Auth_2_ST3, VSS_TP_Auth_3_ST3, VSS_TP_Auth_4_ST3, VSS_TP_Auth_5_ST3, VSS_TP_Auth_6_ST3, VSS_TP_Auth_7_ST3], system-signal-group=VSS_TP_Auth_ST3_6j4id7sghlvlbroli4wjozjik  # VSS-Transportprotokoll für Authentifizierung (degraded) / Vehicle Security System Transport Protocol for authentication broadcast (degraded)
package /ISignalGroups/HAD_IMU/PKG_HAD_IMU/IMU_B_HAD_IMU_GW_Container_ST3_VSS_TP_RealTmOffset_ST3
  i signal group VSS_TP_RealTmOffset_ST3_1t7vc44gftc0wv35k5kgc2in9: i-signal=[VSS_TP_RealTmOffset_0_ST3, VSS_TP_RealTmOffset_1_ST3, VSS_TP_RealTmOffset_2_ST3, VSS_TP_RealTmOffset_3_ST3, VSS_TP_RealTmOffset_4_ST3, VSS_TP_RealTmOffset_5_ST3, VSS_TP_RealTmOffset_6_ST3, VSS_TP_RealTmOffset_7_ST3], system-signal-group=VSS_TP_RealTmOffset_ST3_1t7vc44gftc0wv35k5kgc2in9  # VSS-Transportprotokoll für Echtzeit-Offset (degraded) / Vehicle Security System Transport Protocol for real time offset broadcast (degraded)
package /ISignalGroups/HAD_IMU/PKG_HAD_IMU/IMU_B_HAD_IMU_GW_Container_ST3_VSS_TP_SecTickCount_Lvl1_ST3
  i signal group VSS_TP_SecTickCount_Lvl1_ST3_mzmfdqtqz5kvv1kfpvg0kql3: i-signal=[VSS_TP_SecTickCount_Lvl1_0_ST3, VSS_TP_SecTickCount_Lvl1_1_ST3, VSS_TP_SecTickCount_Lvl1_2_ST3, VSS_TP_SecTickCount_Lvl1_3_ST3, VSS_TP_SecTickCount_Lvl1_4_ST3, VSS_TP_SecTickCount_Lvl1_5_ST3, VSS_TP_SecTickCount_Lvl1_6_ST3, VSS_TP_SecTickCount_Lvl1_7_ST3], system-signal-group=VSS_TP_SecTickCount_Lvl1_ST3_mzmfdqtqz5kvv1kfpvg0kql3  # VSS-Transportprotokoll für sichere Zeit Stufe 1 (degraded) / Vehicle Security System Transport Protocol for secure tick count level #1 (degraded)
package /ISignalGroups/HAD_IMU/PKG_HAD_IMU/IMU_B_HAD_IMU_GW_Container_ST3_VSS_TP_SharedSecret_ST3
  i signal group VSS_TP_SharedSecret_ST3_8pj4t8t4rm3tw3pk5hj7vonti: i-signal=[VSS_TP_SharedSecret_0_ST3, VSS_TP_SharedSecret_1_ST3, VSS_TP_SharedSecret_2_ST3, VSS_TP_SharedSecret_3_ST3, VSS_TP_SharedSecret_4_ST3, VSS_TP_SharedSecret_5_ST3, VSS_TP_SharedSecret_6_ST3, VSS_TP_SharedSecret_7_ST3], system-signal-group=VSS_TP_SharedSecret_ST3_8pj4t8t4rm3tw3pk5hj7vonti  # VSS-Transportprotokoll für gemeinsames Geheimnis (degraded) / Vehicle Security System Transport Protocol for shared secret broadcast (degraded)
package /ISignalGroups/HAD_IMU/PKG_HAD_IMU/IMU_B_HAD_IMU_GW_Container_ST3_VSS_TP_VIN_ST3
  i signal group VSS_TP_VIN_ST3_bz1xsv84cxzl09j028gn39p69: i-signal=[VSS_TP_VIN_0_ST3, VSS_TP_VIN_1_ST3, VSS_TP_VIN_2_ST3, VSS_TP_VIN_3_ST3, VSS_TP_VIN_4_ST3, VSS_TP_VIN_5_ST3, VSS_TP_VIN_6_ST3, VSS_TP_VIN_7_ST3], system-signal-group=VSS_TP_VIN_ST3_bz1xsv84cxzl09j028gn39p69  # VSS-Transportprotokoll für Fahrzeugidentifikationsnummer (degraded) / Vehicle Security System Transport Protocol for Vehicle Identification Number (degraded)
package /ISignalGroups/HAD_IMU/PKG_HAD_IMU/IMU_B_Output_Fast_ST3
  i signal group IMU_B_Output_Fast_Pr5_ST3_dk96owji618h3fdh75ws5eyj3:  # IMU B Output Pr 5 ST3 (degraded)
    com-based-signal-group-transformations=BaseTrans_Profile_5_40
    i-signal=[CRC_IMU_B_Output_Fast_Pr5_ST3, IMU_B_AngAcc_Stat_Fast_ST3, IMU_B_AngAcc_X_Fast_ST3, IMU_B_AngAcc_Y_Fast_ST3, IMU_B_AngAcc_Z_Fast_ST3, IMU_B_AngRate_X_Fast_ST3, IMU_B_AngRate_Y_Fast_ST3, IMU_B_AngRate_Z_Fast_ST3, IMU_B_AngRates_Stat_Fast_ST3, IMU_B_SpecForce_Stat_Fast_ST3, IMU_B_SpecForce_X_Fast_ST3, IMU_B_SpecForce_Y_Fast_ST3, IMU_B_SpecForce_Z_Fast_ST3, IMU_B_Stat_Fast_ST3, IMU_B_Temp_Fast_ST3, IMU_B_TmStmp_NanoSec_Fast_ST3, IMU_B_TmStmp_Sec_Fast_ST3, IMU_B_TmSync_Stat_Fast_ST3, Rsrv01_IMU_B_Output_Fast_Pr5_ST3, Rsrv02_IMU_B_Output_Fast_Pr5_ST3, Rsrv03_IMU_B_Output_Fast_Pr5_ST3, Rsrv04_IMU_B_Output_Fast_Pr5_ST3, Rsrv05_IMU_B_Output_Fast_Pr5_ST3, Rsrv06_IMU_B_Output_Fast_Pr5_ST3, Rsrv07_IMU_B_Output_Fast_Pr5_ST3, SQC_IMU_B_Output_Fast_Pr5_ST3]
    system-signal-group=IMU_B_Output_Fast_Pr5_ST3_dk96owji618h3fdh75ws5eyj3
    end-to-end-transformation-i-signal-props{transformer=E2E_Profile_5, data-ids=923, data-length=320}
package /SecureCommunicationPropsSet
  secure communication props set XDIS_singleton_SecCommPropsSet
    secure communication authentication props SECOC_AP_CMAC_AES_128_24: auth-info-tx-length=24
    secure communication freshness props SECOC_FP_10000_40_8_true: freshness-timestamp-time-period-factor=10000, freshness-value-length=40, freshness-value-tx-length=8, use-freshness-timestamp=true
package /CommunicationClusters/HAD_IMU
  can cluster HAD_IMU: baudrate=500000, protocol-name=CAN, protocol-version=can2.0b, can-fd-baudrate=1000000
    can physical channel HAD_IMU: comm-connectors=[IDC_M_FSI_HAD_IMU_4176sqdaqq92x7hd4zy6lbigy, IMU_B_HAD_IMU_e7z1zoxtgl3nmnp12dav9hlcf]
      frame IMU_B_HAD_IMU_GW_Container_ST3: id 0x167, from IMU_B, to IDC_M_FSI, frame-length=64, can-addressing-mode=STANDARD, can-frame-rx-behavior=CAN-FD, can-frame-tx-behavior=CAN-FD  # IMU B HAD IMU GW Container ST3
        container i pdu IMU_B_HAD_IMU_GW_Container_ST3_ContainerIPdu:  # IMU B HAD IMU GW Container ST3
          length=64
          contained-pdu-triggering=[IMU_B_HAD_IMU_GW_Container_ST3_IMU_B_HAD_IMU_GW_Container_ST3_DI_OdoSpeedometer_ST3_atcuextqldrbpmjkyrnkfnip3, IMU_B_HAD_IMU_GW_Container_ST3_IMU_B_HAD_IMU_GW_Container_ST3_Ign_Stat_ST3_285oi6zg7swv51av1r6gdiy1o, IMU_B_HAD_IMU_GW_Container_ST3_IMU_B_HAD_IMU_GW_Container_ST3_PN14_Master_Stat1_ST3_13xmsb9qu5h0g81k7extj473z, IMU_B_HAD_IMU_GW_Container_ST3_IMU_B_HAD_IMU_GW_Container_ST3_VSS_TP_Auth_ST3_b54vbdzbggdh8efh1p4lajl0h, IMU_B_HAD_IMU_GW_Container_ST3_IMU_B_HAD_IMU_GW_Container_ST3_VSS_TP_RealTmOffset_ST3_czs3mjqahl980ga3yi92g7ruy, IMU_B_HAD_IMU_GW_Container_ST3_IMU_B_HAD_IMU_GW_Container_ST3_VSS_TP_SecTickCount_Lvl1_ST3_4x8o9rc2k1x3j893u8vk7u572, IMU_B_HAD_IMU_GW_Container_ST3_IMU_B_HAD_IMU_GW_Container_ST3_VSS_TP_SharedSecret_ST3_c26qeduqxw7t06nmevx5m087e, IMU_B_HAD_IMU_GW_Container_ST3_IMU_B_HAD_IMU_GW_Container_ST3_VSS_TP_VIN_ST3_3v850grcbot5b9w4bxvr0beeu]
          container-timeout=0.01
          container-trigger=DEFAULT-TRIGGER
          header-type=SHORT-HEADER
          minimum-tx-container-queue-size=2
          rx-accept-contained-i-pdu=ACCEPT-ALL
          threshold-size=59
      frame IDC_M_FSI_HAD_IMU_Container_ST3: id 0x1F3, from IDC_M_FSI, to IMU_B, frame-length=64, can-addressing-mode=STANDARD, can-frame-rx-behavior=CAN-FD, can-frame-tx-behavior=CAN-FD  # IDC M FSI HAD IMU Container ST3
        container i pdu IDC_M_FSI_HAD_IMU_Container_ST3_ContainerIPdu: length=64, contained-pdu-triggering=IDC_M_FSI_HAD_IMU_Container_ST3_IDC_M_FSI_HAD_IMU_Container_ST3_ADAS_HAD_Stat_IDC_M_FSI_ST3_6btv7gi5tcht8bwdlzxd01jt7, container-timeout=0.01, container-trigger=DEFAULT-TRIGGER, header-type=SHORT-HEADER, minimum-tx-container-queue-size=1, rx-accept-contained-i-pdu=ACCEPT-ALL  # IDC M FSI HAD IMU Container ST3
      frame IMU_A_Output_Fast_ST3: id 0x2B3, from IMU_B, to IDC_M_FSI, frame-length=44, can-addressing-mode=STANDARD, can-frame-rx-behavior=CAN-FD, can-frame-tx-behavior=CAN-FD  # IMU A Output ST3
        secured i pdu IMU_A_Output_Fast_ST3_secured: length=44, authentication-props=SECOC_AP_CMAC_AES_128_24, freshness-props=SECOC_FP_10000_40_8_true, payload=IMU_A_Output_Fast_ST3_bqkj0d7svmqxyvx0vx3rxgf24, secure-communication-props={authentication-retries=0, data-id=38379, freshness-value-id=1}
      frame IMU_B_Output_Fast_ST3: id 0x2B5, from IMU_B, to IDC_M_FSI, frame-length=44, can-addressing-mode=STANDARD, can-frame-rx-behavior=CAN-FD, can-frame-tx-behavior=CAN-FD  # IMU B Output ST3
        secured i pdu IMU_B_Output_Fast_ST3_secured: length=44, authentication-props=SECOC_AP_CMAC_AES_128_24, freshness-props=SECOC_FP_10000_40_8_true, payload=IMU_B_Output_Fast_ST3_dbxhz0i601fnsbdah785lfpkr, secure-communication-props={authentication-retries=0, data-id=36544, freshness-value-id=1}
      frame NM_IDC_M_FSI_ST3: id 0x14420163, from IDC_M_FSI, frame-length=8, can-addressing-mode=EXTENDED, can-frame-rx-behavior=CAN-20, can-frame-tx-behavior=CAN-20  # STAR3 NM PDU
        nm pdu NM_IDC_M_FSI_ST3: length=8, nm-data-information=true, unused-bit-pattern=0  # STAR3 NM PDU
          signal NM_ActvWakeup: start 4, 1 bit, little-endian, data-type-policy=OVERRIDE, i-signal-type=PRIMITIVE, init-value=0, base-type=boolean, transfer-property=PENDING  # Active Wakeup Bit
          signal NM_Coord_Id: start 1, 2 bit, little-endian, data-type-policy=OVERRIDE, i-signal-type=PRIMITIVE, init-value=0, base-type=uint8, range raw 0..3, transfer-property=PENDING  # NM Coordinator ID
          signal NM_Coord_SleepRdy: start 3, 1 bit, little-endian, data-type-policy=OVERRIDE, i-signal-type=PRIMITIVE, init-value=0, base-type=boolean, transfer-property=PENDING  # NM Coordinator Sleep Ready Bit
          signal NM_PartNw_Info: start 6, 1 bit, little-endian, data-type-policy=OVERRIDE, i-signal-type=PRIMITIVE, init-value=0, base-type=boolean, transfer-property=PENDING  # Partial Network Information Bit
          signal NM_RepeatMsg_Rq: start 0, 1 bit, little-endian, data-type-policy=OVERRIDE, i-signal-type=PRIMITIVE, init-value=0, base-type=boolean, transfer-property=PENDING  # Repeat Message Request
          signal PNC_00_All_Active_ST3: start 8, 1 bit, little-endian, data-type-policy=OVERRIDE, i-signal-type=PRIMITIVE, init-value=0, base-type=boolean, transfer-property=PENDING  # PNC All Active
          signal PNC_01_HV_Charging_ST3: start 9, 1 bit, little-endian, data-type-policy=OVERRIDE, i-signal-type=PRIMITIVE, init-value=0, base-type=boolean, transfer-property=PENDING  # PNC Hochspannungsladen / PNC high voltage charging
          signal PNC_02_Recharge_Mode_HV_12V_ST3: start 10, 1 bit, little-endian, data-type-policy=OVERRIDE, i-signal-type=PRIMITIVE, init-value=0, base-type=boolean, transfer-property=PENDING  # PNC Umladen zwischen Hochspannung und 12V / PNC recharge betweeen high voltage and 12V
          signal PNC_03_Preconditioning_ST3: start 11, 1 bit, little-endian, data-type-policy=OVERRIDE, i-signal-type=PRIMITIVE, init-value=0, base-type=boolean, transfer-property=PENDING  # PNC Vorkonditionierung / PNC Preconditioning
          signal PNC_04_Telematics_Standalone_ST3: start 12, 1 bit, little-endian, data-type-policy=OVERRIDE, i-signal-type=PRIMITIVE, init-value=0, base-type=boolean, transfer-property=PENDING  # PNC Telematic standalone
          signal PNC_05_Warning_Lights_ST3: start 13, 1 bit, little-endian, data-type-policy=OVERRIDE, i-signal-type=PRIMITIVE, init-value=0, base-type=boolean, transfer-property=PENDING  # PNC Warnblinker / PNC Warning lights
          signal PNC_06_Exit_Warning_ST3: start 14, 1 bit, little-endian, data-type-policy=OVERRIDE, i-signal-type=PRIMITIVE, init-value=0, base-type=boolean, transfer-property=PENDING  # PNC Ausstiegswarnung / PNC Exit warning
          signal PNC_07_SeatComfort_ST3: start 15, 1 bit, little-endian, data-type-policy=OVERRIDE, i-signal-type=PRIMITIVE, init-value=0, base-type=boolean, transfer-property=PENDING  # PNC_07 Seat Comfort
          signal PNC_08_Telematics_Communication_ST3: start 16, 1 bit, little-endian, data-type-policy=OVERRIDE, i-signal-type=PRIMITIVE, init-value=0, base-type=boolean, transfer-property=PENDING  # PNC Telematics communication
          signal PNC_09_IDC_Standalone_ST3: start 17, 1 bit, little-endian, data-type-policy=OVERRIDE, i-signal-type=PRIMITIVE, init-value=0, base-type=boolean, transfer-property=PENDING  # PNC IDC Standalone
          signal PNC_10_Inside_Temp_ST3: start 18, 1 bit, little-endian, data-type-policy=OVERRIDE, i-signal-type=PRIMITIVE, init-value=0, base-type=boolean, transfer-property=PENDING  # PNC Innentemperatur / PNC Inside temperature
          signal PNC_11_Real_Time_Monitoring_ST3: start 19, 1 bit, little-endian, data-type-policy=OVERRIDE, i-signal-type=PRIMITIVE, init-value=0, base-type=boolean, transfer-property=PENDING  # PNC Real time monitoring
          signal PNC_12_Interior_Light_ST3: start 20, 1 bit, little-endian, data-type-policy=OVERRIDE, i-signal-type=PRIMITIVE, init-value=0, base-type=boolean, transfer-property=PENDING  # PNC Innenlicht / PNC Interior lights
          signal PNC_13_Living_ST3: start 21, 1 bit, little-endian, data-type-policy=OVERRIDE, i-signal-type=PRIMITIVE, init-value=0, base-type=boolean, transfer-property=PENDING  # PNC Living
          signal PNC_14_Driver_Information_ST3: start 22, 1 bit, little-endian, data-type-policy=OVERRIDE, i-signal-type=PRIMITIVE, init-value=0, base-type=boolean, transfer-property=PENDING
          signal PNC_15_FOTA_ST3: start 23, 1 bit, little-endian, data-type-policy=OVERRIDE, i-signal-type=PRIMITIVE, init-value=0, base-type=boolean, transfer-property=PENDING
          signal PNC_16_BMS_Sensor_Active_ST3: start 24, 1 bit, little-endian, data-type-policy=OVERRIDE, i-signal-type=PRIMITIVE, init-value=0, base-type=boolean, transfer-property=PENDING
          signal PNC_17_EIS_Active_ST3: start 25, 1 bit, little-endian, data-type-policy=OVERRIDE, i-signal-type=PRIMITIVE, init-value=0, base-type=boolean, transfer-property=PENDING
          signal PNC_18_HV_Charging_UI_Set_ST3: start 26, 1 bit, little-endian, data-type-policy=OVERRIDE, i-signal-type=PRIMITIVE, init-value=0, base-type=boolean, transfer-property=PENDING  # PNC 18 HV Charging Bedienung Einstellungen ST3 / PNC 18 HV Charging User Interaction settings ST3
          signal PNC_19_Afterrun_Cooling_ST3: start 27, 1 bit, little-endian, data-type-policy=OVERRIDE, i-signal-type=PRIMITIVE, init-value=0, base-type=boolean, transfer-property=PENDING  # PNC Afterrun Cooling
          signal PNC_20_Driving_ST3: start 28, 1 bit, little-endian, data-type-policy=OVERRIDE, i-signal-type=PRIMITIVE, init-value=0, base-type=boolean, transfer-property=PENDING  # PNC 20 Driving
          signal PNC_21_KeylessGo_ST3: start 29, 1 bit, little-endian, data-type-policy=OVERRIDE, i-signal-type=PRIMITIVE, init-value=0, base-type=boolean, transfer-property=PENDING
          signal PNC_22_ThermalComfort_ST3: start 30, 1 bit, little-endian, data-type-policy=OVERRIDE, i-signal-type=PRIMITIVE, init-value=0, base-type=boolean, transfer-property=PENDING
          signal PNC_23_HAD_Driving_ST3: start 31, 1 bit, little-endian, data-type-policy=OVERRIDE, i-signal-type=PRIMITIVE, init-value=0, base-type=boolean, transfer-property=PENDING
          signal PNC_24_SecondaryPowernet_ST3: start 32, 1 bit, little-endian, data-type-policy=OVERRIDE, i-signal-type=PRIMITIVE, init-value=0, base-type=boolean, transfer-property=PENDING
          signal PNC_25_Trailer_ST3: start 33, 1 bit, little-endian, data-type-policy=OVERRIDE, i-signal-type=PRIMITIVE, init-value=0, base-type=boolean, transfer-property=PENDING
          signal PNC_26_ECall_ST35: start 34, 1 bit, little-endian, data-type-policy=OVERRIDE, i-signal-type=PRIMITIVE, init-value=0, base-type=boolean, transfer-property=PENDING
          signal PNC_27_eDrive_active_ComCtrl_ST3: start 35, 1 bit, little-endian, data-type-policy=OVERRIDE, i-signal-type=PRIMITIVE, init-value=0, base-type=boolean, transfer-property=PENDING
          signal PNC_28_Charging_Components_ComCtrl_ST3: start 36, 1 bit, little-endian, data-type-policy=OVERRIDE, i-signal-type=PRIMITIVE, init-value=0, base-type=boolean, transfer-property=PENDING
      frame NM_IMU_B_ST3: id 0x1442016B, from IMU_B, frame-length=8, can-addressing-mode=EXTENDED, can-frame-rx-behavior=CAN-20, can-frame-tx-behavior=CAN-20  # Netzwerk-Management / Network Management
        nm pdu NM_IMU_B_ST3: length=8, nm-data-information=true, unused-bit-pattern=0  # STAR3 NM PDU
          signal NM_ActvWakeup: start 4, 1 bit, little-endian, data-type-policy=OVERRIDE, i-signal-type=PRIMITIVE, init-value=0, base-type=boolean, transfer-property=PENDING  # Active Wakeup Bit
          signal NM_Coord_Id: start 1, 2 bit, little-endian, data-type-policy=OVERRIDE, i-signal-type=PRIMITIVE, init-value=0, base-type=uint8, range raw 0..3, transfer-property=PENDING  # NM Coordinator ID
          signal NM_Coord_SleepRdy: start 3, 1 bit, little-endian, data-type-policy=OVERRIDE, i-signal-type=PRIMITIVE, init-value=0, base-type=boolean, transfer-property=PENDING  # NM Coordinator Sleep Ready Bit
          signal NM_PartNw_Info: start 6, 1 bit, little-endian, data-type-policy=OVERRIDE, i-signal-type=PRIMITIVE, init-value=0, base-type=boolean, transfer-property=PENDING  # Partial Network Information Bit
          signal NM_RepeatMsg_Rq: start 0, 1 bit, little-endian, data-type-policy=OVERRIDE, i-signal-type=PRIMITIVE, init-value=0, base-type=boolean, transfer-property=PENDING  # Repeat Message Request
          signal PNC_00_All_Active_ST3: start 8, 1 bit, little-endian, data-type-policy=OVERRIDE, i-signal-type=PRIMITIVE, init-value=0, base-type=boolean, transfer-property=PENDING  # PNC All Active
          signal PNC_01_HV_Charging_ST3: start 9, 1 bit, little-endian, data-type-policy=OVERRIDE, i-signal-type=PRIMITIVE, init-value=0, base-type=boolean, transfer-property=PENDING  # PNC Hochspannungsladen / PNC high voltage charging
          signal PNC_02_Recharge_Mode_HV_12V_ST3: start 10, 1 bit, little-endian, data-type-policy=OVERRIDE, i-signal-type=PRIMITIVE, init-value=0, base-type=boolean, transfer-property=PENDING  # PNC Umladen zwischen Hochspannung und 12V / PNC recharge betweeen high voltage and 12V
          signal PNC_03_Preconditioning_ST3: start 11, 1 bit, little-endian, data-type-policy=OVERRIDE, i-signal-type=PRIMITIVE, init-value=0, base-type=boolean, transfer-property=PENDING  # PNC Vorkonditionierung / PNC Preconditioning
          signal PNC_04_Telematics_Standalone_ST3: start 12, 1 bit, little-endian, data-type-policy=OVERRIDE, i-signal-type=PRIMITIVE, init-value=0, base-type=boolean, transfer-property=PENDING  # PNC Telematic standalone
          signal PNC_05_Warning_Lights_ST3: start 13, 1 bit, little-endian, data-type-policy=OVERRIDE, i-signal-type=PRIMITIVE, init-value=0, base-type=boolean, transfer-property=PENDING  # PNC Warnblinker / PNC Warning lights
          signal PNC_06_Exit_Warning_ST3: start 14, 1 bit, little-endian, data-type-policy=OVERRIDE, i-signal-type=PRIMITIVE, init-value=0, base-type=boolean, transfer-property=PENDING  # PNC Ausstiegswarnung / PNC Exit warning
          signal PNC_07_SeatComfort_ST3: start 15, 1 bit, little-endian, data-type-policy=OVERRIDE, i-signal-type=PRIMITIVE, init-value=0, base-type=boolean, transfer-property=PENDING  # PNC_07 Seat Comfort
          signal PNC_08_Telematics_Communication_ST3: start 16, 1 bit, little-endian, data-type-policy=OVERRIDE, i-signal-type=PRIMITIVE, init-value=0, base-type=boolean, transfer-property=PENDING  # PNC Telematics communication
          signal PNC_09_IDC_Standalone_ST3: start 17, 1 bit, little-endian, data-type-policy=OVERRIDE, i-signal-type=PRIMITIVE, init-value=0, base-type=boolean, transfer-property=PENDING  # PNC IDC Standalone
          signal PNC_10_Inside_Temp_ST3: start 18, 1 bit, little-endian, data-type-policy=OVERRIDE, i-signal-type=PRIMITIVE, init-value=0, base-type=boolean, transfer-property=PENDING  # PNC Innentemperatur / PNC Inside temperature
          signal PNC_11_Real_Time_Monitoring_ST3: start 19, 1 bit, little-endian, data-type-policy=OVERRIDE, i-signal-type=PRIMITIVE, init-value=0, base-type=boolean, transfer-property=PENDING  # PNC Real time monitoring
          signal PNC_12_Interior_Light_ST3: start 20, 1 bit, little-endian, data-type-policy=OVERRIDE, i-signal-type=PRIMITIVE, init-value=0, base-type=boolean, transfer-property=PENDING  # PNC Innenlicht / PNC Interior lights
          signal PNC_13_Living_ST3: start 21, 1 bit, little-endian, data-type-policy=OVERRIDE, i-signal-type=PRIMITIVE, init-value=0, base-type=boolean, transfer-property=PENDING  # PNC Living
          signal PNC_14_Driver_Information_ST3: start 22, 1 bit, little-endian, data-type-policy=OVERRIDE, i-signal-type=PRIMITIVE, init-value=0, base-type=boolean, transfer-property=PENDING
          signal PNC_15_FOTA_ST3: start 23, 1 bit, little-endian, data-type-policy=OVERRIDE, i-signal-type=PRIMITIVE, init-value=0, base-type=boolean, transfer-property=PENDING
          signal PNC_16_BMS_Sensor_Active_ST3: start 24, 1 bit, little-endian, data-type-policy=OVERRIDE, i-signal-type=PRIMITIVE, init-value=0, base-type=boolean, transfer-property=PENDING
          signal PNC_17_EIS_Active_ST3: start 25, 1 bit, little-endian, data-type-policy=OVERRIDE, i-signal-type=PRIMITIVE, init-value=0, base-type=boolean, transfer-property=PENDING
          signal PNC_18_HV_Charging_UI_Set_ST3: start 26, 1 bit, little-endian, data-type-policy=OVERRIDE, i-signal-type=PRIMITIVE, init-value=0, base-type=boolean, transfer-property=PENDING  # PNC 18 HV Charging Bedienung Einstellungen ST3 / PNC 18 HV Charging User Interaction settings ST3
          signal PNC_19_Afterrun_Cooling_ST3: start 27, 1 bit, little-endian, data-type-policy=OVERRIDE, i-signal-type=PRIMITIVE, init-value=0, base-type=boolean, transfer-property=PENDING  # PNC Afterrun Cooling
          signal PNC_20_Driving_ST3: start 28, 1 bit, little-endian, data-type-policy=OVERRIDE, i-signal-type=PRIMITIVE, init-value=0, base-type=boolean, transfer-property=PENDING  # PNC 20 Driving
          signal PNC_21_KeylessGo_ST3: start 29, 1 bit, little-endian, data-type-policy=OVERRIDE, i-signal-type=PRIMITIVE, init-value=0, base-type=boolean, transfer-property=PENDING
          signal PNC_22_ThermalComfort_ST3: start 30, 1 bit, little-endian, data-type-policy=OVERRIDE, i-signal-type=PRIMITIVE, init-value=0, base-type=boolean, transfer-property=PENDING
          signal PNC_23_HAD_Driving_ST3: start 31, 1 bit, little-endian, data-type-policy=OVERRIDE, i-signal-type=PRIMITIVE, init-value=0, base-type=boolean, transfer-property=PENDING
          signal PNC_24_SecondaryPowernet_ST3: start 32, 1 bit, little-endian, data-type-policy=OVERRIDE, i-signal-type=PRIMITIVE, init-value=0, base-type=boolean, transfer-property=PENDING
          signal PNC_25_Trailer_ST3: start 33, 1 bit, little-endian, data-type-policy=OVERRIDE, i-signal-type=PRIMITIVE, init-value=0, base-type=boolean, transfer-property=PENDING
          signal PNC_26_ECall_ST35: start 34, 1 bit, little-endian, data-type-policy=OVERRIDE, i-signal-type=PRIMITIVE, init-value=0, base-type=boolean, transfer-property=PENDING
          signal PNC_27_eDrive_active_ComCtrl_ST3: start 35, 1 bit, little-endian, data-type-policy=OVERRIDE, i-signal-type=PRIMITIVE, init-value=0, base-type=boolean, transfer-property=PENDING
          signal PNC_28_Charging_Components_ComCtrl_ST3: start 36, 1 bit, little-endian, data-type-policy=OVERRIDE, i-signal-type=PRIMITIVE, init-value=0, base-type=boolean, transfer-property=PENDING
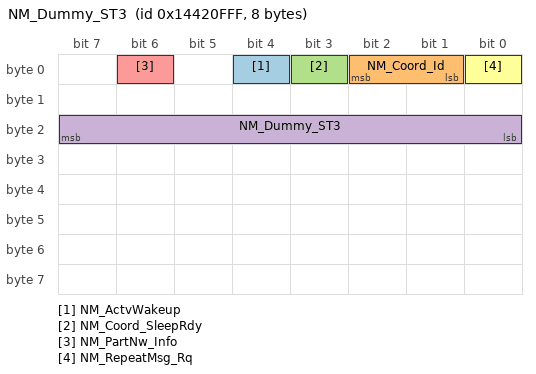
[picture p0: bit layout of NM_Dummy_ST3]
      frame NM_Dummy_ST3: id 0x14420FFF, to IDC_M_FSI IMU_B, frame-length=8, can-addressing-mode=EXTENDED, can-frame-rx-behavior=CAN-20, can-frame-tx-behavior=CAN-20, rx-identifier-range={lower-can-id=339869696, upper-can-id=339873791}  # Netzwerk-Management / Network Management
        nm pdu NM_Dummy_ST3: length=8, nm-data-information=true, unused-bit-pattern=0  # Netzwerk-Management / Network Management
          signal NM_ActvWakeup: start 4, 1 bit, little-endian, data-type-policy=OVERRIDE, i-signal-type=PRIMITIVE, init-value=0, base-type=boolean, transfer-property=PENDING  # Active Wakeup Bit
          signal NM_Coord_Id: start 1, 2 bit, little-endian, data-type-policy=OVERRIDE, i-signal-type=PRIMITIVE, init-value=0, base-type=uint8, range raw 0..3, transfer-property=PENDING  # NM Coordinator ID
          signal NM_Coord_SleepRdy: start 3, 1 bit, little-endian, data-type-policy=OVERRIDE, i-signal-type=PRIMITIVE, init-value=0, base-type=boolean, transfer-property=PENDING  # NM Coordinator Sleep Ready Bit
          signal NM_Dummy_ST3: start 16, 8 bit, little-endian, data-type-policy=OVERRIDE, i-signal-type=PRIMITIVE, init-value=0, base-type=uint8, data-constr=c08_UInt_SNA_na, transfer-property=PENDING  # Netzwerk-Management Dummy-Signal für alle NM-PDUs / Network Management dummy signal for all NM PDUs
          signal NM_PartNw_Info: start 6, 1 bit, little-endian, data-type-policy=OVERRIDE, i-signal-type=PRIMITIVE, init-value=0, base-type=boolean, transfer-property=PENDING  # Partial Network Information Bit
          signal NM_RepeatMsg_Rq: start 0, 1 bit, little-endian, data-type-policy=OVERRIDE, i-signal-type=PRIMITIVE, init-value=0, base-type=boolean, transfer-property=PENDING  # Repeat Message Request
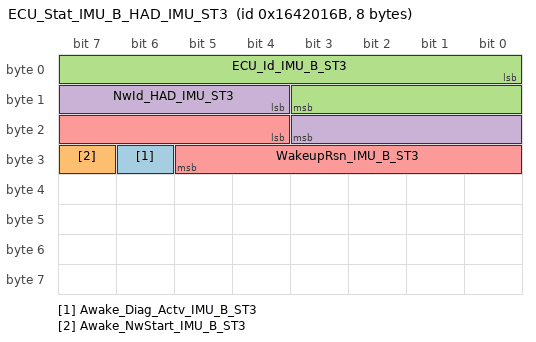
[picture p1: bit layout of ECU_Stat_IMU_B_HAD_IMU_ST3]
      frame ECU_Stat_IMU_B_HAD_IMU_ST3: id 0x1642016B, from IMU_B, frame-length=8, can-addressing-mode=EXTENDED, can-frame-rx-behavior=CAN-FD, can-frame-tx-behavior=CAN-FD  # ECU Status / ECU state
        pdu ECU_Stat_IMU_B_HAD_IMU_ST3: length=8, transmission-mode-true-timing=cyclic-timing={time-offset=0.005, time-period=1.0}, unused-bit-pattern=0  # ECU Status / ECU state
          signal Awake_Diag_Actv_IMU_B_ST3: start 30, 1 bit, little-endian, data-type-policy=OVERRIDE, i-signal-type=PRIMITIVE, init-value=0, base-type=boolean, transfer-property=PENDING  # Wachhalten für Diagnose aktiv / Stay awake for diagnostics active
          signal Awake_NwStart_IMU_B_ST3: start 31, 1 bit, little-endian, data-type-policy=OVERRIDE, i-signal-type=PRIMITIVE, init-value=0, base-type=boolean, transfer-property=PENDING  # Wachhalten für Netzwerkstartphase / Stay awake for network startup
          signal ECU_Id_IMU_B_ST3: start 0, 12 bit, little-endian, data-type-policy=OVERRIDE, i-signal-type=PRIMITIVE, init-value=363, base-type=uint16, invalid-value=4095, compu-method=c12_0_4094_1_SNA, data-constr=c12_0_4094_1_SNA, transfer-property=PENDING  # ECU-Identifizierungsnummer / ECU identifier
          signal NwId_HAD_IMU_ST3: start 12, 8 bit, little-endian, data-type-policy=OVERRIDE, i-signal-type=PRIMITIVE, init-value=46, base-type=uint8, invalid-value=255, compu-method=c08_0_254_1_SNA_255, data-constr=c08_0_254_1_SNA_255, transfer-property=PENDING  # Netzwerk-Identifizierungsnummer / Network identifier
          signal WakeupRsn_IMU_B_ST3: start 20, 10 bit, little-endian, data-type-policy=OVERRIDE, i-signal-type=PRIMITIVE, init-value=1023, base-type=uint16, invalid-value=1023, compu-method=c10_WakeupRsn_ST3, data-constr=c10_WakeupRsn_ST3, transfer-property=PENDING  # Weckgrund / Wakeup reason
      pdu triggering IMU_B_HAD_IMU_GW_Container_ST3_IMU_B_HAD_IMU_GW_Container_ST3_DI_OdoSpeedometer_ST3_atcuextqldrbpmjkyrnkfnip3: pdu=IMU_B_HAD_IMU_GW_Container_ST3_DI_OdoSpeedometer_ST3, from IMU_B, to IDC_M_FSI
      pdu triggering IMU_B_HAD_IMU_GW_Container_ST3_IMU_B_HAD_IMU_GW_Container_ST3_Ign_Stat_ST3_9o5nwdmsgjwwul51gt4t8a2ev: pdu=IMU_B_HAD_IMU_GW_Container_ST3_Ign_Stat_ST3, from IMU_B, to IDC_M_FSI
      pdu triggering IMU_B_HAD_IMU_GW_Container_ST3_IMU_B_HAD_IMU_GW_Container_ST3_Ign_Stat_ST3_285oi6zg7swv51av1r6gdiy1o: pdu=IMU_B_HAD_IMU_GW_Container_ST3_IMU_B_HAD_IMU_GW_Container_ST3_Ign_Stat_ST3_secured, from IMU_B, to IDC_M_FSI
      pdu triggering IMU_B_HAD_IMU_GW_Container_ST3_IMU_B_HAD_IMU_GW_Container_ST3_PN14_Master_Stat1_ST3_55a6a0fnjme4imo147rnfut1q: pdu=IMU_B_HAD_IMU_GW_Container_ST3_PN14_Master_Stat1_ST3, from IMU_B, to IDC_M_FSI
      pdu triggering IMU_B_HAD_IMU_GW_Container_ST3_IMU_B_HAD_IMU_GW_Container_ST3_PN14_Master_Stat1_ST3_13xmsb9qu5h0g81k7extj473z: pdu=IMU_B_HAD_IMU_GW_Container_ST3_IMU_B_HAD_IMU_GW_Container_ST3_PN14_Master_Stat1_ST3_secured, from IMU_B, to IDC_M_FSI
      pdu triggering IMU_B_HAD_IMU_GW_Container_ST3_IMU_B_HAD_IMU_GW_Container_ST3_VSS_TP_Auth_ST3_b54vbdzbggdh8efh1p4lajl0h: pdu=IMU_B_HAD_IMU_GW_Container_ST3_VSS_TP_Auth_ST3, from IMU_B, to IDC_M_FSI
      pdu triggering IMU_B_HAD_IMU_GW_Container_ST3_IMU_B_HAD_IMU_GW_Container_ST3_VSS_TP_RealTmOffset_ST3_czs3mjqahl980ga3yi92g7ruy: pdu=IMU_B_HAD_IMU_GW_Container_ST3_VSS_TP_RealTmOffset_ST3, from IMU_B, to IDC_M_FSI
      pdu triggering IMU_B_HAD_IMU_GW_Container_ST3_IMU_B_HAD_IMU_GW_Container_ST3_VSS_TP_SecTickCount_Lvl1_ST3_4x8o9rc2k1x3j893u8vk7u572: pdu=IMU_B_HAD_IMU_GW_Container_ST3_VSS_TP_SecTickCount_Lvl1_ST3, from IMU_B, to IDC_M_FSI
      pdu triggering IMU_B_HAD_IMU_GW_Container_ST3_IMU_B_HAD_IMU_GW_Container_ST3_VSS_TP_SharedSecret_ST3_c26qeduqxw7t06nmevx5m087e: pdu=IMU_B_HAD_IMU_GW_Container_ST3_VSS_TP_SharedSecret_ST3, from IMU_B, to IDC_M_FSI
      pdu triggering IMU_B_HAD_IMU_GW_Container_ST3_IMU_B_HAD_IMU_GW_Container_ST3_VSS_TP_VIN_ST3_3v850grcbot5b9w4bxvr0beeu: pdu=IMU_B_HAD_IMU_GW_Container_ST3_VSS_TP_VIN_ST3, from IMU_B, to IDC_M_FSI
      pdu triggering IDC_M_FSI_HAD_IMU_Container_ST3_IDC_M_FSI_HAD_IMU_Container_ST3_ADAS_HAD_Stat_IDC_M_FSI_ST3_3ft8f4vbg9cfnchzrcot530mq: pdu=IDC_M_FSI_HAD_IMU_Container_ST3_ADAS_HAD_Stat_IDC_M_FSI_ST3, from IDC_M_FSI, to IMU_B
      pdu triggering IDC_M_FSI_HAD_IMU_Container_ST3_IDC_M_FSI_HAD_IMU_Container_ST3_ADAS_HAD_Stat_IDC_M_FSI_ST3_6btv7gi5tcht8bwdlzxd01jt7: pdu=IDC_M_FSI_HAD_IMU_Container_ST3_IDC_M_FSI_HAD_IMU_Container_ST3_ADAS_HAD_Stat_IDC_M_FSI_ST3_secured, from IDC_M_FSI, to IMU_B
      pdu triggering IMU_A_Output_Fast_ST3_bqkj0d7svmqxyvx0vx3rxgf24: pdu=IMU_A_Output_Fast_ST3, from IMU_B, to IDC_M_FSI
      pdu triggering IMU_B_Output_Fast_ST3_dbxhz0i601fnsbdah785lfpkr: pdu=IMU_B_Output_Fast_ST3, from IMU_B, to IDC_M_FSI
package /NmConfigs
  nm config NM_CONFIG: can-nm-cluster-coupling{coupled-cluster=HAD_IMU, nm-busload-reduction-enabled=false, nm-immediate-restart-enabled=false}
    can nm cluster HAD_IMU: communication-cluster=HAD_IMU, nm-channel-id=46, nm-channel-sleep-master=false, nm-pnc-participation=true, nm-synchronizing-network=false, nm-busload-reduction-active=false, nm-cbv-position=0, nm-immediate-nm-cycle-time=0.02, nm-immediate-nm-transmissions=6, nm-message-timeout-time=0.5, nm-msg-cycle-time=1.0, nm-network-timeout=2.5, nm-remote-sleep-indication-time=2.5, nm-repeat-message-time=3.0, nm-wait-bus-sleep-time=1.5
      can nm node IDC_M_FSI_HAD_IMUNMNODE: controller=IDC_M_FSI_HAD_IMU, nm-if-ecu=IDC_M_FSI_CAN_NMECU, nm-passive-mode-enabled=false, rx-nm-pdu=NM_Dummy_ST3, tx-nm-pdu=NM_IDC_M_FSI_ST3, nm-msg-cycle-offset=0.0
      can nm node IMU_B_HAD_IMUNMNODE: controller=IMU_B_HAD_IMU, nm-if-ecu=IMU_B_CAN_NMECU, nm-passive-mode-enabled=false, rx-nm-pdu=NM_Dummy_ST3, tx-nm-pdu=NM_IMU_B_ST3, nm-msg-cycle-offset=0.0
    nm-if-ecus:
      nm ecu IDC_M_FSI_CAN_NMECU: ecu-instance=IDC_M_FSI, nm-com-control-enabled=true, nm-remote-sleep-ind-enabled=true, nm-user-data-enabled=false
      nm ecu IMU_B_CAN_NMECU: ecu-instance=IMU_B, nm-com-control-enabled=true, nm-remote-sleep-ind-enabled=true, nm-user-data-enabled=false
package /ISignalIPduGroups/HAD_IMU/PKG_HAD_IMU
  12 x i signal i pdu group, all with communication-mode=Partial Network:
    IDC_M_FSI_HAD_IMU_Tx_PNC_All_Active: communication-direction=OUT, i-signal-i-pdus=IDC_M_FSI_HAD_IMU_Container_ST3_ADAS_HAD_Stat_IDC_M_FSI_ST3
    IDC_M_FSI_HAD_IMU_Tx_PNC_20: communication-direction=OUT, i-signal-i-pdus=IDC_M_FSI_HAD_IMU_Container_ST3_ADAS_HAD_Stat_IDC_M_FSI_ST3
    IDC_M_FSI_HAD_IMU_Tx_PNC_23: communication-direction=OUT, i-signal-i-pdus=IDC_M_FSI_HAD_IMU_Container_ST3_ADAS_HAD_Stat_IDC_M_FSI_ST3
    IMU_B_HAD_IMU_Tx_PNC_All_Active: communication-direction=OUT
      i-signal-i-pdus:
        ECU_Stat_IMU_B_HAD_IMU_ST3
        IMU_A_Output_Fast_ST3
        IMU_B_HAD_IMU_GW_Container_ST3_DI_OdoSpeedometer_ST3
        IMU_B_HAD_IMU_GW_Container_ST3_Ign_Stat_ST3
        IMU_B_HAD_IMU_GW_Container_ST3_PN14_Master_Stat1_ST3
        IMU_B_HAD_IMU_GW_Container_ST3_VSS_TP_Auth_ST3
        IMU_B_HAD_IMU_GW_Container_ST3_VSS_TP_RealTmOffset_ST3
        IMU_B_HAD_IMU_GW_Container_ST3_VSS_TP_SecTickCount_Lvl1_ST3
        IMU_B_HAD_IMU_GW_Container_ST3_VSS_TP_SharedSecret_ST3
        IMU_B_HAD_IMU_GW_Container_ST3_VSS_TP_VIN_ST3
        IMU_B_Output_Fast_ST3
    IMU_B_HAD_IMU_Tx_PNC_20: communication-direction=OUT
      i-signal-i-pdus:
        ECU_Stat_IMU_B_HAD_IMU_ST3
        IMU_A_Output_Fast_ST3
        IMU_B_HAD_IMU_GW_Container_ST3_DI_OdoSpeedometer_ST3
        IMU_B_HAD_IMU_GW_Container_ST3_Ign_Stat_ST3
        IMU_B_HAD_IMU_GW_Container_ST3_PN14_Master_Stat1_ST3
        IMU_B_HAD_IMU_GW_Container_ST3_VSS_TP_Auth_ST3
        IMU_B_HAD_IMU_GW_Container_ST3_VSS_TP_RealTmOffset_ST3
        IMU_B_HAD_IMU_GW_Container_ST3_VSS_TP_SecTickCount_Lvl1_ST3
        IMU_B_HAD_IMU_GW_Container_ST3_VSS_TP_SharedSecret_ST3
        IMU_B_HAD_IMU_GW_Container_ST3_VSS_TP_VIN_ST3
        IMU_B_Output_Fast_ST3
    IMU_B_HAD_IMU_Tx_PNC_23: communication-direction=OUT
      i-signal-i-pdus:
        ECU_Stat_IMU_B_HAD_IMU_ST3
        IMU_A_Output_Fast_ST3
        IMU_B_HAD_IMU_GW_Container_ST3_DI_OdoSpeedometer_ST3
        IMU_B_HAD_IMU_GW_Container_ST3_Ign_Stat_ST3
        IMU_B_HAD_IMU_GW_Container_ST3_PN14_Master_Stat1_ST3
        IMU_B_HAD_IMU_GW_Container_ST3_VSS_TP_Auth_ST3
        IMU_B_HAD_IMU_GW_Container_ST3_VSS_TP_RealTmOffset_ST3
        IMU_B_HAD_IMU_GW_Container_ST3_VSS_TP_SecTickCount_Lvl1_ST3
        IMU_B_HAD_IMU_GW_Container_ST3_VSS_TP_SharedSecret_ST3
        IMU_B_HAD_IMU_GW_Container_ST3_VSS_TP_VIN_ST3
        IMU_B_Output_Fast_ST3
    IDC_M_FSI_HAD_IMU_Rx_PNC_All_Active: communication-direction=IN
      i-signal-i-pdus:
        IMU_A_Output_Fast_ST3
        IMU_B_HAD_IMU_GW_Container_ST3_DI_OdoSpeedometer_ST3
        IMU_B_HAD_IMU_GW_Container_ST3_Ign_Stat_ST3
        IMU_B_HAD_IMU_GW_Container_ST3_PN14_Master_Stat1_ST3
        IMU_B_HAD_IMU_GW_Container_ST3_VSS_TP_Auth_ST3
        IMU_B_HAD_IMU_GW_Container_ST3_VSS_TP_RealTmOffset_ST3
        IMU_B_HAD_IMU_GW_Container_ST3_VSS_TP_SecTickCount_Lvl1_ST3
        IMU_B_HAD_IMU_GW_Container_ST3_VSS_TP_SharedSecret_ST3
        IMU_B_HAD_IMU_GW_Container_ST3_VSS_TP_VIN_ST3
        IMU_B_Output_Fast_ST3
    IDC_M_FSI_HAD_IMU_Rx_PNC_20: communication-direction=IN
      i-signal-i-pdus:
        IMU_A_Output_Fast_ST3
        IMU_B_HAD_IMU_GW_Container_ST3_DI_OdoSpeedometer_ST3
        IMU_B_HAD_IMU_GW_Container_ST3_Ign_Stat_ST3
        IMU_B_HAD_IMU_GW_Container_ST3_PN14_Master_Stat1_ST3
        IMU_B_HAD_IMU_GW_Container_ST3_VSS_TP_Auth_ST3
        IMU_B_HAD_IMU_GW_Container_ST3_VSS_TP_RealTmOffset_ST3
        IMU_B_HAD_IMU_GW_Container_ST3_VSS_TP_SecTickCount_Lvl1_ST3
        IMU_B_HAD_IMU_GW_Container_ST3_VSS_TP_SharedSecret_ST3
        IMU_B_HAD_IMU_GW_Container_ST3_VSS_TP_VIN_ST3
        IMU_B_Output_Fast_ST3
    IDC_M_FSI_HAD_IMU_Rx_PNC_23: communication-direction=IN
      i-signal-i-pdus:
        IMU_A_Output_Fast_ST3
        IMU_B_HAD_IMU_GW_Container_ST3_DI_OdoSpeedometer_ST3
        IMU_B_HAD_IMU_GW_Container_ST3_Ign_Stat_ST3
        IMU_B_HAD_IMU_GW_Container_ST3_PN14_Master_Stat1_ST3
        IMU_B_HAD_IMU_GW_Container_ST3_VSS_TP_Auth_ST3
        IMU_B_HAD_IMU_GW_Container_ST3_VSS_TP_RealTmOffset_ST3
        IMU_B_HAD_IMU_GW_Container_ST3_VSS_TP_SecTickCount_Lvl1_ST3
        IMU_B_HAD_IMU_GW_Container_ST3_VSS_TP_SharedSecret_ST3
        IMU_B_HAD_IMU_GW_Container_ST3_VSS_TP_VIN_ST3
        IMU_B_Output_Fast_ST3
    IMU_B_HAD_IMU_Rx_PNC_All_Active: communication-direction=IN, i-signal-i-pdus=IDC_M_FSI_HAD_IMU_Container_ST3_ADAS_HAD_Stat_IDC_M_FSI_ST3
    IMU_B_HAD_IMU_Rx_PNC_20: communication-direction=IN, i-signal-i-pdus=IDC_M_FSI_HAD_IMU_Container_ST3_ADAS_HAD_Stat_IDC_M_FSI_ST3
    IMU_B_HAD_IMU_Rx_PNC_23: communication-direction=IN, i-signal-i-pdus=IDC_M_FSI_HAD_IMU_Container_ST3_ADAS_HAD_Stat_IDC_M_FSI_ST3
package /Systems
  system SYSTEM_XDIS: category=SYSTEM_EXTRACT, container-i-pdu-header-byte-order=big-endian, pnc-vector-length=7, pnc-vector-offset=1, system-version=2024.05.00
    system mapping XDIS_SYSTEMMAPPING
      5 x sec oc crypto service mapping, all with authentication=CMAC_AES_128:
        SECPDU_IDC_M_FSI_HAD_IMU_Container_ST3_ADAS_HAD_Stat_IDC_M_FSI_ST3: crypto-service-key=CSK_28326CRYPTO_ALGOFAM_AES128
        SECPDU_IMU_A_Output_Fast_ST3: crypto-service-key=CSK_38379CRYPTO_ALGOFAM_AES128
        SECPDU_IMU_B_HAD_IMU_GW_Container_ST3_Ign_Stat_ST3: crypto-service-key=CSK_28212CRYPTO_ALGOFAM_AES128
        SECPDU_IMU_B_HAD_IMU_GW_Container_ST3_PN14_Master_Stat1_ST3: crypto-service-key=CSK_57668CRYPTO_ALGOFAM_AES128
        SECPDU_IMU_B_Output_Fast_ST3: crypto-service-key=CSK_36544CRYPTO_ALGOFAM_AES128
      pnc-mapping physical-channel=HAD_IMU, pnc-group=[IDC_M_FSI_HAD_IMU_Rx_PNC_All_Active, IDC_M_FSI_HAD_IMU_Tx_PNC_All_Active, IMU_B_HAD_IMU_Rx_PNC_All_Active, IMU_B_HAD_IMU_Tx_PNC_All_Active], pnc-identifier=8, pnc-wakeup-enable=true, wakeup-frame=[NM_IDC_M_FSI_ST3_xnygw77p221gchoh0wlitej4, NM_IMU_B_ST3_5n3tsppcblgyfz59fa3fxhygu]:
        ident PNC_00_MAPPING
      pnc-mapping physical-channel=HAD_IMU, pnc-group=[IDC_M_FSI_HAD_IMU_Rx_PNC_20, IDC_M_FSI_HAD_IMU_Tx_PNC_20, IMU_B_HAD_IMU_Rx_PNC_20, IMU_B_HAD_IMU_Tx_PNC_20], pnc-identifier=28, pnc-wakeup-enable=true, wakeup-frame=[NM_IDC_M_FSI_ST3_xnygw77p221gchoh0wlitej4, NM_IMU_B_ST3_5n3tsppcblgyfz59fa3fxhygu]:
        ident PNC_20_MAPPING
      pnc-mapping physical-channel=HAD_IMU, pnc-group=[IDC_M_FSI_HAD_IMU_Rx_PNC_23, IDC_M_FSI_HAD_IMU_Tx_PNC_23, IMU_B_HAD_IMU_Rx_PNC_23, IMU_B_HAD_IMU_Tx_PNC_23], pnc-identifier=31, pnc-wakeup-enable=true, wakeup-frame=[NM_IDC_M_FSI_ST3_xnygw77p221gchoh0wlitej4, NM_IMU_B_ST3_5n3tsppcblgyfz59fa3fxhygu]:
        ident PNC_23_MAPPING
package /CryptoPrimitives
  crypto service primitive CMAC_AES_128: algorithm-family=CRYPTO_ALGOFAM_AES, algorithm-mode=CRYPTO_ALGOMODE_CMAC
package /CryptoDevelopmentKeys
  5 x crypto service key, all with algorithm-family=CRYPTO_ALGOFAM_AES, length=128:
    CSK_28326CRYPTO_ALGOFAM_AES128
    CSK_38379CRYPTO_ALGOFAM_AES128
    CSK_28212CRYPTO_ALGOFAM_AES128
    CSK_57668CRYPTO_ALGOFAM_AES128
    CSK_36544CRYPTO_ALGOFAM_AES128
